VERSION ""

NS_ :

BS_:

BU_:

BO_ 2163223550 CN: 8 Vector__XXX
 SG_ CrashChecksum : 60|4@1+ (1,0) [0|15] "count" Vector__XXX
 SG_ CrashCounter : 56|4@1+ (1,0) [0|15] "count" Vector__XXX
 SG_ CrashType : 0|5@1+ (5,0) [0|0] "bit-mapped" Vector__XXX

BO_ 2230333950 WAND: 8 Vector__XXX
 SG_ WandAngle : 0|16@1+ (0.002,-64) [-64|64.51] "deg" Vector__XXX
 SG_ WandSensorFigureofMerit : 16|2@1+ (1,0) [0|3] "" Vector__XXX

BO_ 2230334206 LDISP: 8 Vector__XXX
 SG_ LnrDsplmntSnsrSnsrFgrfMrt : 16|2@1+ (1,0) [0|3] "" Vector__XXX
 SG_ MeasuredLinearDisplacement : 0|16@1+ (0.1,0) [0|6425.5] "mm" Vector__XXX

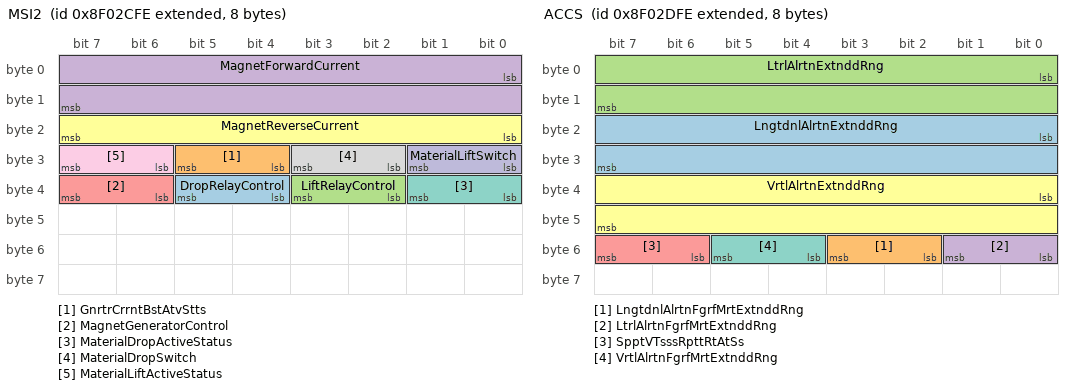
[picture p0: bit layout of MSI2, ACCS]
BO_ 2297441534 MSI2: 8 Vector__XXX
 SG_ DropRelayControl : 36|2@1+ (1,0) [0|3] "" Vector__XXX
 SG_ GnrtrCrrntBstAtvStts : 28|2@1+ (1,0) [0|3] "" Vector__XXX
 SG_ LiftRelayControl : 34|2@1+ (1,0) [0|3] "" Vector__XXX
 SG_ MagnetForwardCurrent : 0|16@1+ (1,0) [0|64255] "A" Vector__XXX
 SG_ MagnetGeneratorControl : 38|2@1+ (1,0) [0|3] "" Vector__XXX
 SG_ MagnetReverseCurrent : 16|8@1+ (1,0) [0|250] "A" Vector__XXX
 SG_ MaterialDropActiveStatus : 32|2@1+ (1,0) [0|3] "" Vector__XXX
 SG_ MaterialDropSwitch : 26|2@1+ (1,0) [0|3] "" Vector__XXX
 SG_ MaterialLiftActiveStatus : 30|2@1+ (1,0) [0|3] "" Vector__XXX
 SG_ MaterialLiftSwitch : 24|2@1+ (1,0) [0|3] "" Vector__XXX

BO_ 2297441790 ACCS: 8 Vector__XXX
 SG_ LngtdnlAlrtnExtnddRng : 16|16@1+ (0.01,-320) [-320|322.55] "m/(s*s)" Vector__XXX
 SG_ LngtdnlAlrtnFgrfMrtExtnddRng : 50|2@1+ (1,0) [0|3] "" Vector__XXX
 SG_ LtrlAlrtnExtnddRng : 0|16@1+ (0.01,-320) [-320|322.55] "m/(s*s)" Vector__XXX
 SG_ LtrlAlrtnFgrfMrtExtnddRng : 48|2@1+ (1,0) [0|3] "" Vector__XXX
 SG_ SpptVTsssRpttRtAtSs : 54|2@1+ (1,0) [0|3] "" Vector__XXX
 SG_ VrtlAlrtnExtnddRng : 32|16@1+ (0.01,-320) [-320|322.55] "m/(s*s)" Vector__XXX
 SG_ VrtlAlrtnFgrfMrtExtnddRng : 52|2@1+ (1,0) [0|3] "" Vector__XXX

BO_ 2297455358 ETC12: 8 Vector__XXX
 SG_ TrnsmssnDrtnlOtptShftSpd : 32|16@1+ (1,-32127) [-32127|32128] "rpm" Vector__XXX
 SG_ TrnsmssnHdrsttLp1Prssr : 0|16@1+ (1,0) [0|64255] "kPa" Vector__XXX
 SG_ TrnsmssnHdrsttLp2Prssr : 16|16@1+ (1,0) [0|64255] "kPa" Vector__XXX
 SG_ TrnsmssnIntrmdtShftSpd : 48|16@1+ (0.125,0) [0|8031.875] "rpm" Vector__XXX

BO_ 2297499902 B2: 8 Vector__XXX
 SG_ BrakePedalSwitch2 : 16|2@1+ (1,0) [0|3] "" Vector__XXX
 SG_ DmnddBrkAppltnPrssr : 0|16@1+ (0.1,0) [0|6425.5] "kPa" Vector__XXX

BO_ 2298375934 HRW: 8 Vector__XXX
 SG_ FrontAxleLeftWheelSpeed : 0|16@1+ (0.00390625,0) [0|250.996] "km/h" Vector__XXX
 SG_ Frontaxlerightwheelspeed : 16|16@1+ (0.00390625,0) [0|250.996] "km/h" Vector__XXX
 SG_ Rearaxleleftwheelspeed : 32|16@1+ (0.00390625,0) [0|250.996] "km/h" Vector__XXX
 SG_ Rearaxlerightwheelspeed : 48|16@1+ (0.00390625,0) [0|250.996] "km/h" Vector__XXX

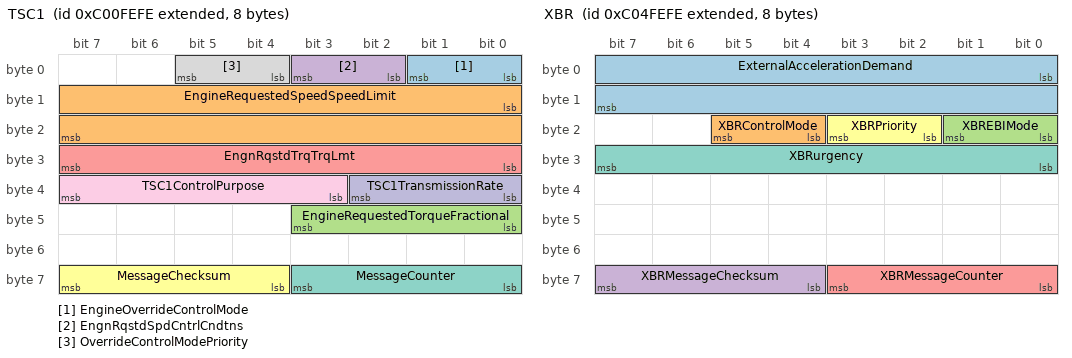
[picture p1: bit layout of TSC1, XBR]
BO_ 2348875518 TSC1: 8 Vector__XXX
 SG_ EngineOverrideControlMode : 0|2@1+ (1,0) [0|3] "" Vector__XXX
 SG_ EngineRequestedSpeedSpeedLimit : 8|16@1+ (0.125,0) [0|8031.875] "rpm" Vector__XXX
 SG_ EngineRequestedTorqueFractional : 40|4@1+ (0.125,0) [0|0.875] "%" Vector__XXX
 SG_ EngnRqstdSpdCntrlCndtns : 2|2@1+ (1,0) [0|3] "" Vector__XXX
 SG_ EngnRqstdTrqTrqLmt : 24|8@1+ (1,-125) [-125|125] "%" Vector__XXX
 SG_ MessageChecksum : 60|4@1+ (1,0) [0|15] "count" Vector__XXX
 SG_ MessageCounter : 56|4@1+ (1,0) [0|15] "count" Vector__XXX
 SG_ OverrideControlModePriority : 4|2@1+ (1,0) [0|3] "" Vector__XXX
 SG_ TSC1ControlPurpose : 35|5@1+ (1,0) [0|31] "" Vector__XXX
 SG_ TSC1TransmissionRate : 32|3@1+ (1,0) [0|7] "" Vector__XXX

BO_ 2348941054 TC1: 8 Vector__XXX
 SG_ DisengageDrivelineRequest : 4|2@1+ (1,0) [0|3] "" Vector__XXX
 SG_ DsnggDffrntlLkRqstCntrl : 32|2@1+ (1,0) [0|3] "" Vector__XXX
 SG_ DsnggDffrntlLkRqstCntrlFrnt : 34|2@1+ (1,0) [0|3] "" Vector__XXX
 SG_ DsnggDffrntlLkRqstCntrlRr : 36|2@1+ (1,0) [0|3] "" Vector__XXX
 SG_ DsnggDffrntlLkRqstFrntAxl1 : 24|2@1+ (1,0) [0|3] "" Vector__XXX
 SG_ DsnggDffrntlLkRqstFrntAxl2 : 26|2@1+ (1,0) [0|3] "" Vector__XXX
 SG_ DsnggDffrntlLkRqstRrAxl1 : 28|2@1+ (1,0) [0|3] "" Vector__XXX
 SG_ DsnggDffrntlLkRqstRrAxl2 : 30|2@1+ (1,0) [0|3] "" Vector__XXX
 SG_ RequestedPercentClutchSlip : 8|8@1+ (0.4,0) [0|100] "%" Vector__XXX
 SG_ TransmissionMode1 : 40|2@1+ (1,0) [0|3] "" Vector__XXX
 SG_ TransmissionMode2 : 42|2@1+ (1,0) [0|3] "" Vector__XXX
 SG_ TransmissionMode3 : 44|2@1+ (1,0) [0|3] "" Vector__XXX
 SG_ TransmissionMode4 : 46|2@1+ (1,0) [0|3] "" Vector__XXX
 SG_ TransmissionMode5 : 56|2@1+ (1,0) [0|3] "" Vector__XXX
 SG_ TransmissionMode6 : 58|2@1+ (1,0) [0|3] "" Vector__XXX
 SG_ TransmissionMode7 : 60|2@1+ (1,0) [0|3] "" Vector__XXX
 SG_ TransmissionMode8 : 62|2@1+ (1,0) [0|3] "" Vector__XXX
 SG_ TransmissionRequestedGear : 16|8@1+ (1,-125) [-125|125] "gear value" Vector__XXX
 SG_ TransmissionRequestedLaunchGear : 50|4@1+ (1,0) [0|15] "" Vector__XXX
 SG_ TrnsmssnAtNtrlMnlRtrnRqst : 48|2@1+ (1,0) [0|3] "" Vector__XXX
 SG_ TrnsmssnGrShftInhtRqst : 0|2@1+ (1,0) [0|3] "" Vector__XXX
 SG_ TrnsmssnLdRdtnInhtRqst : 38|2@1+ (1,0) [0|3] "" Vector__XXX
 SG_ TrnsmssnRvrsGrShftInhtRqst : 6|2@1+ (1,0) [0|3] "" Vector__XXX
 SG_ TrnsmssnShftSltrDsplMdSwth : 54|2@1+ (1,0) [0|3] "" Vector__XXX
 SG_ TrnsmssnTrqCnvrtrLkpRqst : 2|2@1+ (1,0) [0|3] "" Vector__XXX

BO_ 2349137662 XBR: 8 Vector__XXX
 SG_ ExternalAccelerationDemand : 0|16@1+ (0.00048828125,-15.687) [-15.687|15.687] "m/(s*s)" Vector__XXX
 SG_ XBRControlMode : 20|2@1+ (1,0) [0|3] "" Vector__XXX
 SG_ XBREBIMode : 16|2@1+ (1,0) [0|3] "" Vector__XXX
 SG_ XBRMessageChecksum : 60|4@1+ (1,0) [0|15] "count" Vector__XXX
 SG_ XBRMessageCounter : 56|4@1+ (1,0) [0|15] "count" Vector__XXX
 SG_ XBRPriority : 18|2@1+ (1,0) [0|3] "" Vector__XXX
 SG_ XBRurgency : 24|8@1+ (0.4,0) [0|100] "%" Vector__XXX

BO_ 2349399806 AUXIO5: 8 Vector__XXX
 SG_ AuxiliaryIOChannel3 : 48|16@1+ (1,0) [0|64255] "count" Vector__XXX
 SG_ AuxiliaryIOChannel4 : 32|16@1+ (1,0) [0|64255] "count" Vector__XXX
 SG_ AuxiliaryIOChannel5 : 16|16@1+ (1,0) [0|64255] "count" Vector__XXX
 SG_ AuxiliaryIOChannel6 : 0|16@1+ (1,0) [0|64255] "count" Vector__XXX

BO_ 2349465342 SRASI: 8 Vector__XXX
 SG_ StaticRollAngle : 0|8@1+ (1,-125) [-125|125] "deg" Vector__XXX
 SG_ StaticRollAngleStatus : 8|3@1+ (1,0) [0|7] "" Vector__XXX

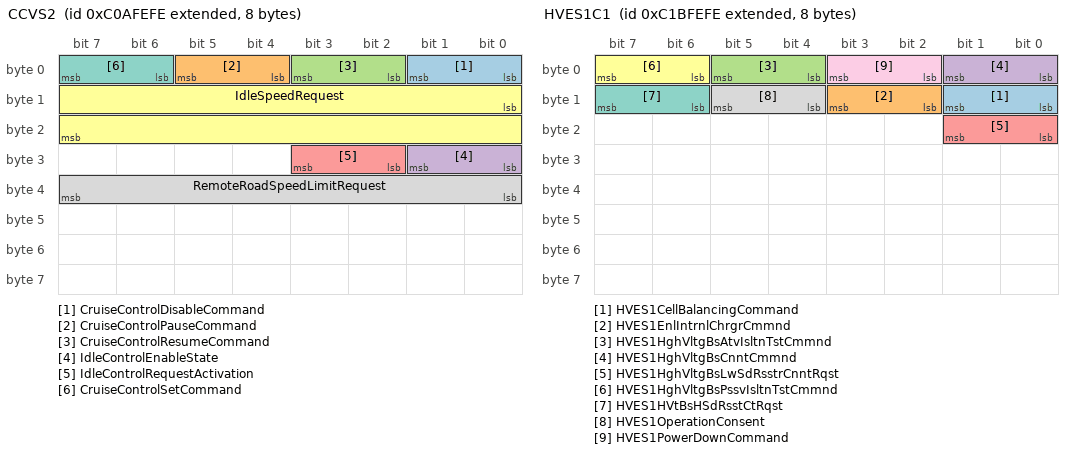
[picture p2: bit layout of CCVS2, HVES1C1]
BO_ 2349530878 CCVS2: 8 Vector__XXX
 SG_ CruiseControlDisableCommand : 0|2@1+ (1,0) [0|3] "" Vector__XXX
 SG_ CruiseControlPauseCommand : 4|2@1+ (1,0) [0|3] "" Vector__XXX
 SG_ CruiseControlResumeCommand : 2|2@1+ (1,0) [0|3] "" Vector__XXX
 SG_ IdleControlEnableState : 24|2@1+ (1,0) [0|3] "" Vector__XXX
 SG_ IdleControlRequestActivation : 26|2@1+ (1,0) [0|3] "" Vector__XXX
 SG_ IdleSpeedRequest : 8|16@1+ (0.125,0) [0|8031.875] "rpm" Vector__XXX
 SG_ CruiseControlSetCommand : 6|2@1+ (1,0) [0|3] "" Vector__XXX
 SG_ RemoteRoadSpeedLimitRequest : 32|8@1+ (1,0) [0|250] "km/h" Vector__XXX

BO_ 2349596414 AEBS2: 8 Vector__XXX
 SG_ AEBS2messagechecksum : 60|4@1+ (1,0) [0|15] "count" Vector__XXX
 SG_ AEBS2messageCounter : 56|4@1+ (1,0) [0|15] "count" Vector__XXX
 SG_ DvtvtddAdvdEBSst : 0|2@1+ (1,0) [0|3] "" Vector__XXX

BO_ 2349727486 TC2: 8 Vector__XXX
 SG_ TransmissionMode10 : 2|2@1+ (1,0) [0|3] "" Vector__XXX
 SG_ TransmissionMode9 : 0|2@1+ (1,0) [0|3] "" Vector__XXX

BO_ 2350644990 HVES1C1: 8 Vector__XXX
 SG_ HVES1CellBalancingCommand : 8|2@1+ (1,0) [0|3] "" Vector__XXX
 SG_ HVES1EnlIntrnlChrgrCmmnd : 10|2@1+ (1,0) [0|3] "" Vector__XXX
 SG_ HVES1HghVltgBsAtvIsltnTstCmmnd : 4|2@1+ (1,0) [0|3] "" Vector__XXX
 SG_ HVES1HghVltgBsCnntCmmnd : 0|2@1+ (1,0) [0|3] "" Vector__XXX
 SG_ HVES1HghVltgBsLwSdRsstrCnntRqst : 16|2@1+ (1,0) [0|3] "" Vector__XXX
 SG_ HVES1HghVltgBsPssvIsltnTstCmmnd : 6|2@1+ (1,0) [0|3] "" Vector__XXX
 SG_ HVES1HVtBsHSdRsstCtRqst : 14|2@1+ (1,0) [0|3] "" Vector__XXX
 SG_ HVES1OperationConsent : 12|2@1+ (1,0) [0|3] "" Vector__XXX
 SG_ HVES1PowerDownCommand : 2|2@1+ (1,0) [0|3] "" Vector__XXX

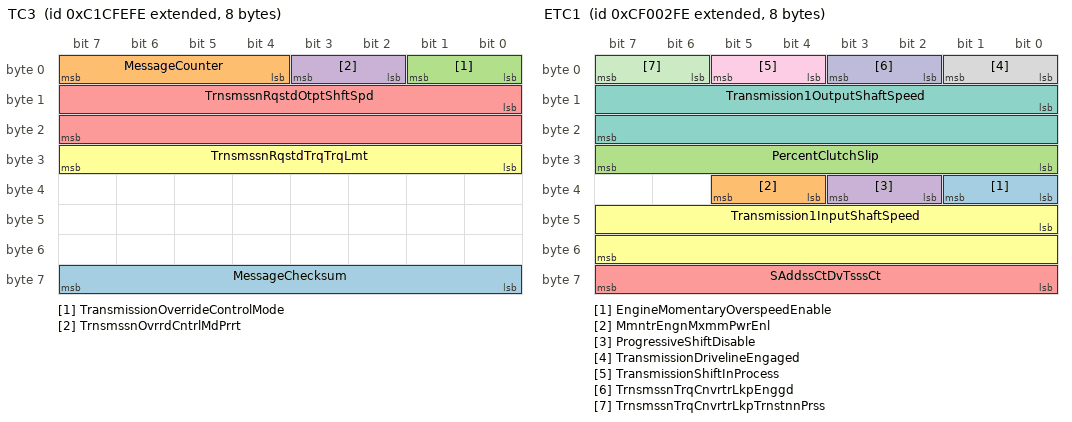
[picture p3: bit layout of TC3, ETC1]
BO_ 2350710526 TC3: 8 Vector__XXX
 SG_ MessageChecksum : 56|8@1+ (1,0) [0|255] "count" Vector__XXX
 SG_ MessageCounter : 4|4@1+ (1,0) [0|15] "count" Vector__XXX
 SG_ TransmissionOverrideControlMode : 0|2@1+ (1,0) [0|3] "" Vector__XXX
 SG_ TrnsmssnOvrrdCntrlMdPrrt : 2|2@1+ (1,0) [0|3] "" Vector__XXX
 SG_ TrnsmssnRqstdOtptShftSpd : 8|16@1+ (0.25,-8031.75) [-8031.75|8032] "rpm" Vector__XXX
 SG_ TrnsmssnRqstdTrqTrqLmt : 24|8@1+ (1,-125) [-125|125] "%" Vector__XXX

BO_ 2350776062 EIC: 8 Vector__XXX
 SG_ EngineTimingAdvance : 0|16@1+ (0.0078125,-200) [-200|301.99] "deg" Vector__XXX

BO_ 2350841598 ALTC: 8 Vector__XXX
 SG_ AlternatorTorqueRampTimeCommand : 24|8@1+ (0.1,0) [0|25] "s" Vector__XXX
 SG_ AltrntrExttnMxmmCrrntLmt : 16|8@1+ (0.25,0) [0|62.5] "A" Vector__XXX
 SG_ AltrntrStpntVltgCmmnd : 0|16@1+ (0.001,0) [0|64.255] "V" Vector__XXX
 SG_ AltrntrTrqRmpMxmmSpdCmmnd : 32|8@1+ (32,0) [0|8000] "rpm" Vector__XXX

BO_ 2358902526 JLCM: 8 Vector__XXX
 SG_ Joystick1Lamp10Command : 18|2@1+ (1,0) [0|3] "" Vector__XXX
 SG_ Joystick1Lamp1Command : 0|2@1+ (1,0) [0|3] "" Vector__XXX
 SG_ Joystick1Lamp2Command : 2|2@1+ (1,0) [0|3] "" Vector__XXX
 SG_ Joystick1Lamp3Command : 4|2@1+ (1,0) [0|3] "" Vector__XXX
 SG_ Joystick1Lamp4Command : 6|2@1+ (1,0) [0|3] "" Vector__XXX
 SG_ Joystick1Lamp5Command : 8|2@1+ (1,0) [0|3] "" Vector__XXX
 SG_ Joystick1Lamp6Command : 10|2@1+ (1,0) [0|3] "" Vector__XXX
 SG_ Joystick1Lamp7Command : 12|2@1+ (1,0) [0|3] "" Vector__XXX
 SG_ Joystick1Lamp8Command : 14|2@1+ (1,0) [0|3] "" Vector__XXX
 SG_ Joystick1Lamp9Command : 16|2@1+ (1,0) [0|3] "" Vector__XXX
 SG_ Joystick2Lamp10Command : 38|2@1+ (1,0) [0|3] "" Vector__XXX
 SG_ Joystick2Lamp1Command : 20|2@1+ (1,0) [0|3] "" Vector__XXX
 SG_ Joystick2Lamp2Command : 22|2@1+ (1,0) [0|3] "" Vector__XXX
 SG_ Joystick2Lamp3Command : 24|2@1+ (1,0) [0|3] "" Vector__XXX
 SG_ Joystick2Lamp4Command : 26|2@1+ (1,0) [0|3] "" Vector__XXX
 SG_ Joystick2Lamp5Command : 28|2@1+ (1,0) [0|3] "" Vector__XXX
 SG_ Joystick2Lamp6Command : 30|2@1+ (1,0) [0|3] "" Vector__XXX
 SG_ Joystick2Lamp7Command : 32|2@1+ (1,0) [0|3] "" Vector__XXX
 SG_ Joystick2Lamp8Command : 34|2@1+ (1,0) [0|3] "" Vector__XXX
 SG_ Joystick2Lamp9Command : 36|2@1+ (1,0) [0|3] "" Vector__XXX
 SG_ Joystick3Lamp10Command : 58|2@1+ (1,0) [0|3] "" Vector__XXX
 SG_ Joystick3Lamp1Command : 40|2@1+ (1,0) [0|3] "" Vector__XXX
 SG_ Joystick3Lamp2Command : 42|2@1+ (1,0) [0|3] "" Vector__XXX
 SG_ Joystick3Lamp3Command : 44|2@1+ (1,0) [0|3] "" Vector__XXX
 SG_ Joystick3Lamp4Command : 46|2@1+ (1,0) [0|3] "" Vector__XXX
 SG_ Joystick3Lamp5Command : 48|2@1+ (1,0) [0|3] "" Vector__XXX
 SG_ Joystick3Lamp6Command : 50|2@1+ (1,0) [0|3] "" Vector__XXX
 SG_ Joystick3Lamp7Command : 52|2@1+ (1,0) [0|3] "" Vector__XXX
 SG_ Joystick3Lamp8Command : 54|2@1+ (1,0) [0|3] "" Vector__XXX
 SG_ Joystick3Lamp9Command : 56|2@1+ (1,0) [0|3] "" Vector__XXX

BO_ 2362572542 ASC6: 8 Vector__XXX
 SG_ LevelPresetFrontAxleLeft : 0|16@1+ (0.1,-3200) [-3200|3225.5] "mm" Vector__XXX
 SG_ LevelPresetFrontAxleRight : 16|16@1+ (0.1,-3200) [-3200|3225.5] "mm" Vector__XXX
 SG_ LevelPresetRearAxleLeft : 32|16@1+ (0.1,-3200) [-3200|3225.5] "mm" Vector__XXX
 SG_ LevelPresetRearAxleRight : 48|16@1+ (0.1,-3200) [-3200|3225.5] "mm" Vector__XXX

BO_ 2362638078 ASC2: 8 Vector__XXX
 SG_ AllwLvlCntrlDrngBrkngCmmnd : 54|2@1+ (1,0) [0|3] "" Vector__XXX
 SG_ Atmttrtnhlpldtrnsfr : 0|2@1+ (1,0) [0|3] "" Vector__XXX
 SG_ DamperStiffnessRequestFrontAxle : 24|8@1+ (0.4,0) [0|100] "%" Vector__XXX
 SG_ DamperStiffnessRequestRearAxle : 32|8@1+ (0.4,0) [0|100] "%" Vector__XXX
 SG_ DmprStffnssRqstLftTgAxl : 40|8@1+ (0.4,0) [0|100] "%" Vector__XXX
 SG_ KneelingCommandFrontAxle : 48|2@1+ (1,0) [0|3] "" Vector__XXX
 SG_ KneelingCommandRearAxle : 50|2@1+ (1,0) [0|3] "" Vector__XXX
 SG_ KneelingControlModeRequest : 6|2@1+ (1,0) [0|3] "" Vector__XXX
 SG_ KneelingRequestLeftSide : 2|2@1+ (1,0) [0|3] "" Vector__XXX
 SG_ KneelingRequestRightSide : 4|2@1+ (1,0) [0|3] "" Vector__XXX
 SG_ LevelControlModeRequest : 16|4@1+ (1,0) [0|15] "" Vector__XXX
 SG_ LiftAxle1PositionCommand : 20|2@1+ (1,0) [0|3] "" Vector__XXX
 SG_ LiftAxle2PositionCommand : 22|2@1+ (1,0) [0|3] "" Vector__XXX
 SG_ Memorylevelrequest : 60|4@1+ (1,0) [0|15] "" Vector__XXX
 SG_ NominalLevelRequestFrontAxle : 8|4@1+ (1,0) [0|15] "" Vector__XXX
 SG_ NominalLevelRequestRearAxle : 12|4@1+ (1,0) [0|15] "" Vector__XXX
 SG_ PrhtAtmtArSspnsnCntrl : 58|2@1+ (1,0) [0|3] "" Vector__XXX
 SG_ Prohibitairsuspensioncontrol : 52|2@1+ (1,0) [0|3] "" Vector__XXX
 SG_ SpdDpndntLvlCntrlRqst : 56|2@1+ (1,0) [0|3] "" Vector__XXX

BO_ 2364539646 ETC1: 8 Vector__XXX
 SG_ EngineMomentaryOverspeedEnable : 32|2@1+ (1,0) [0|3] "" Vector__XXX
 SG_ MmntrEngnMxmmPwrEnl : 36|2@1+ (1,0) [0|3] "" Vector__XXX
 SG_ PercentClutchSlip : 24|8@1+ (0.4,0) [0|100] "%" Vector__XXX
 SG_ ProgressiveShiftDisable : 34|2@1+ (1,0) [0|3] "" Vector__XXX
 SG_ SAddssCtDvTsssCt : 56|8@1+ (1,0) [0|255] "SA" Vector__XXX
 SG_ Transmission1InputShaftSpeed : 40|16@1+ (0.125,0) [0|8031.875] "rpm" Vector__XXX
 SG_ Transmission1OutputShaftSpeed : 8|16@1+ (0.125,0) [0|8031.875] "rpm" Vector__XXX
 SG_ TransmissionDrivelineEngaged : 0|2@1+ (1,0) [0|3] "" Vector__XXX
 SG_ TransmissionShiftInProcess : 4|2@1+ (1,0) [0|3] "" Vector__XXX
 SG_ TrnsmssnTrqCnvrtrLkpEnggd : 2|2@1+ (1,0) [0|3] "" Vector__XXX
 SG_ TrnsmssnTrqCnvrtrLkpTrnstnnPrss : 6|2@1+ (1,0) [0|3] "" Vector__XXX

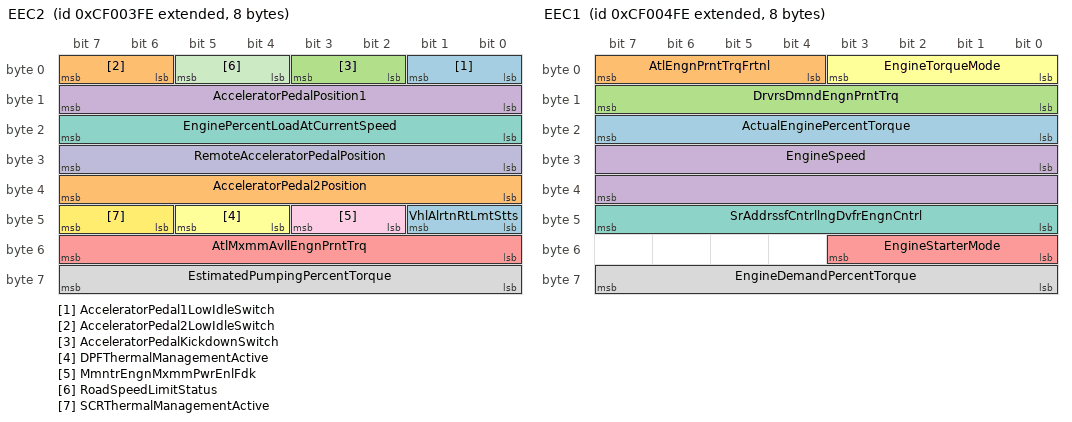
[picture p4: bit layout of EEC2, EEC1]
BO_ 2364539902 EEC2: 8 Vector__XXX
 SG_ AcceleratorPedal1LowIdleSwitch : 0|2@1+ (1,0) [0|3] "" Vector__XXX
 SG_ AcceleratorPedal2LowIdleSwitch : 6|2@1+ (1,0) [0|3] "" Vector__XXX
 SG_ AcceleratorPedalKickdownSwitch : 2|2@1+ (1,0) [0|3] "" Vector__XXX
 SG_ AcceleratorPedalPosition1 : 8|8@1+ (0.4,0) [0|100] "%" Vector__XXX
 SG_ AtlMxmmAvllEngnPrntTrq : 48|8@1+ (0.4,0) [0|100] "%" Vector__XXX
 SG_ DPFThermalManagementActive : 44|2@1+ (1,0) [0|3] "" Vector__XXX
 SG_ EnginePercentLoadAtCurrentSpeed : 16|8@1+ (1,0) [0|250] "%" Vector__XXX
 SG_ EstimatedPumpingPercentTorque : 56|8@1+ (1,-125) [-125|125] "%" Vector__XXX
 SG_ MmntrEngnMxmmPwrEnlFdk : 42|2@1+ (1,0) [0|3] "" Vector__XXX
 SG_ RemoteAcceleratorPedalPosition : 24|8@1+ (0.4,0) [0|100] "%" Vector__XXX
 SG_ RoadSpeedLimitStatus : 4|2@1+ (1,0) [0|3] "" Vector__XXX
 SG_ SCRThermalManagementActive : 46|2@1+ (1,0) [0|3] "" Vector__XXX
 SG_ VhlAlrtnRtLmtStts : 40|2@1+ (1,0) [0|3] "" Vector__XXX
 SG_ AcceleratorPedal2Position : 32|8@1+ (0.4,0) [0|100] "%" Vector__XXX

BO_ 2364540158 EEC1: 8 Vector__XXX
 SG_ ActualEnginePercentTorque : 16|8@1+ (1,-125) [-125|125] "%" Vector__XXX
 SG_ AtlEngnPrntTrqFrtnl : 4|4@1+ (0.125,0) [0|0.875] "%" Vector__XXX
 SG_ DrvrsDmndEngnPrntTrq : 8|8@1+ (1,-125) [-125|125] "%" Vector__XXX
 SG_ EngineSpeed : 24|16@1+ (0.125,0) [0|8031.875] "rpm" Vector__XXX
 SG_ EngineStarterMode : 48|4@1+ (1,0) [0|15] "" Vector__XXX
 SG_ EngineTorqueMode : 0|4@1+ (1,0) [0|15] "" Vector__XXX
 SG_ SrAddrssfCntrllngDvfrEngnCntrl : 40|8@1+ (1,0) [0|255] "SA" Vector__XXX
 SG_ EngineDemandPercentTorque : 56|8@1+ (1,-125) [-125|125] "%" Vector__XXX

BO_ 2364541694 EGF1: 8 Vector__XXX
 SG_ EngineIntakeAirMassFlowRate : 16|16@1+ (0.05,0) [0|3212.75] "kg/h" Vector__XXX
 SG_ EngnExhstGsRrltn1MssFlwRt : 0|16@1+ (0.05,0) [0|3212.75] "kg/h" Vector__XXX
 SG_ EngnExhstGsRrltn2MssFlwRt : 32|16@1+ (0.05,0) [0|3212.75] "kg/h" Vector__XXX

BO_ 2364542206 ETC8: 8 Vector__XXX
 SG_ TrnsmssnClthCnvrtrInptSpd : 16|16@1+ (0.125,0) [0|8031.875] "rpm" Vector__XXX
 SG_ TrnsmssnTrqCnvrtrRt : 0|16@1+ (0.001,0) [0|64.255] "Ratio" Vector__XXX
 SG_ TransmissionShiftInhibitReason : 32|8@1+ (1,0) [0|255] "" Vector__XXX
 SG_ TrnsmssnTrqCnvrtrLkpInhtRsn : 40|8@1+ (1,0) [0|255] "" Vector__XXX
 SG_ TrnsmssnTrqCnvrtrLkpInhtIndtr : 48|2@1+ (1,0) [0|3] "" Vector__XXX

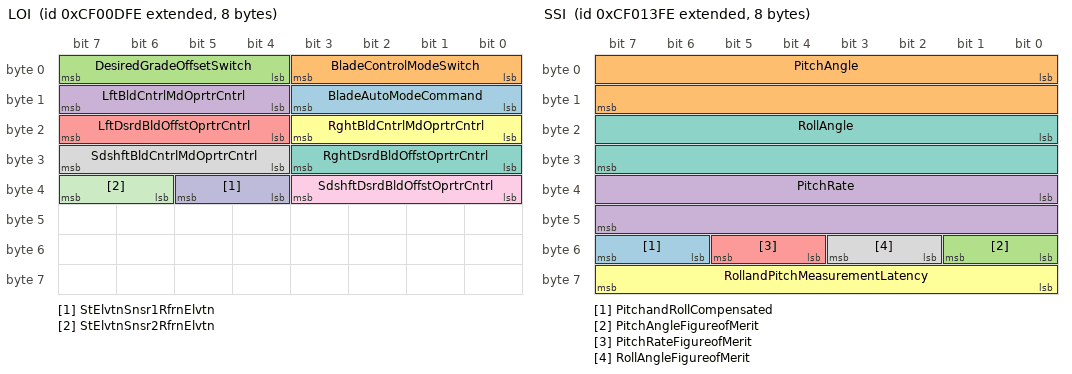
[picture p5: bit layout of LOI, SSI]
BO_ 2364542462 LOI: 8 Vector__XXX
 SG_ BladeAutoModeCommand : 8|4@1+ (1,0) [0|15] "" Vector__XXX
 SG_ BladeControlModeSwitch : 0|4@1+ (1,0) [0|15] "" Vector__XXX
 SG_ DesiredGradeOffsetSwitch : 4|4@1+ (1,0) [0|15] "" Vector__XXX
 SG_ LftBldCntrlMdOprtrCntrl : 12|4@1+ (1,0) [0|15] "" Vector__XXX
 SG_ LftDsrdBldOffstOprtrCntrl : 20|4@1+ (1,0) [0|15] "" Vector__XXX
 SG_ RghtBldCntrlMdOprtrCntrl : 16|4@1+ (1,0) [0|15] "" Vector__XXX
 SG_ RghtDsrdBldOffstOprtrCntrl : 24|4@1+ (1,0) [0|15] "" Vector__XXX
 SG_ SdshftBldCntrlMdOprtrCntrl : 28|4@1+ (1,0) [0|15] "" Vector__XXX
 SG_ SdshftDsrdBldOffstOprtrCntrl : 32|4@1+ (1,0) [0|15] "" Vector__XXX
 SG_ StElvtnSnsr1RfrnElvtn : 36|2@1+ (1,0) [0|3] "" Vector__XXX
 SG_ StElvtnSnsr2RfrnElvtn : 38|2@1+ (1,0) [0|3] "" Vector__XXX

BO_ 2364543998 SSI: 8 Vector__XXX
 SG_ PitchandRollCompensated : 54|2@1+ (1,0) [0|3] "" Vector__XXX
 SG_ PitchAngle : 0|16@1+ (0.002,-64) [-64|64.51] "deg" Vector__XXX
 SG_ PitchAngleFigureofMerit : 48|2@1+ (1,0) [0|3] "" Vector__XXX
 SG_ PitchRate : 32|16@1+ (0.002,-64) [-64|64.51] "deg/s" Vector__XXX
 SG_ PitchRateFigureofMerit : 52|2@1+ (1,0) [0|3] "" Vector__XXX
 SG_ RollandPitchMeasurementLatency : 56|8@1+ (0.5,0) [0|125] "ms" Vector__XXX
 SG_ RollAngle : 16|16@1+ (0.002,-64) [-64|64.51] "deg" Vector__XXX
 SG_ RollAngleFigureofMerit : 50|2@1+ (1,0) [0|3] "" Vector__XXX

BO_ 2364544254 BI: 8 Vector__XXX
 SG_ BladeRotationAngle : 16|16@1+ (0.0078125,-200) [-200|301.99] "deg" Vector__XXX
 SG_ BladeRotationAngleFigureofMerit : 42|2@1+ (1,0) [0|3] "" Vector__XXX
 SG_ RelativeBladeHeight : 0|16@1+ (0.1,-3200) [-3200|3225.5] "mm" Vector__XXX
 SG_ RltvBldHghtFgrfMrt : 40|2@1+ (1,0) [0|3] "" Vector__XXX
 SG_ RtvBdHtdBdRttAMstLt : 32|8@1+ (0.5,0) [0|125] "ms" Vector__XXX

BO_ 2364544510 RGTACRP: 8 Vector__XXX
 SG_ RqstdGnrtrOvrllPwrFtr : 32|16@1+ (0.00006103515625,-1) [-1|2.921814] "" Vector__XXX
 SG_ RqstdGnrtrOvrllPwrFtrLggng : 48|2@1+ (1,0) [0|3] "" Vector__XXX
 SG_ RqstdGnrtrTtlACRtvPwr : 0|32@1+ (1,-2000000000) [-2000000000|2.21108E+09] "VA" Vector__XXX

BO_ 2364544766 CCS: 8 Vector__XXX
 SG_ EngineCylinder1CombustionStatus : 0|2@1+ (1,0) [0|3] "" Vector__XXX
 SG_ EngineCylinder2CombustionStatus : 2|2@1+ (1,0) [0|3] "" Vector__XXX
 SG_ EngineCylinder3CombustionStatus : 4|2@1+ (1,0) [0|3] "" Vector__XXX
 SG_ EngineCylinder4CombustionStatus : 6|2@1+ (1,0) [0|3] "" Vector__XXX
 SG_ EngineCylinder5CombustionStatus : 8|2@1+ (1,0) [0|3] "" Vector__XXX
 SG_ EngineCylinder6CombustionStatus : 10|2@1+ (1,0) [0|3] "" Vector__XXX
 SG_ EngineCylinder7CombustionStatus : 12|2@1+ (1,0) [0|3] "" Vector__XXX
 SG_ EngineCylinder8CombustionStatus : 14|2@1+ (1,0) [0|3] "" Vector__XXX
 SG_ EngineCylinder9CombustionStatus : 16|2@1+ (1,0) [0|3] "" Vector__XXX
 SG_ EngnClndr10CmstnStts : 18|2@1+ (1,0) [0|3] "" Vector__XXX
 SG_ EngnClndr11CmstnStts : 20|2@1+ (1,0) [0|3] "" Vector__XXX
 SG_ EngnClndr12CmstnStts : 22|2@1+ (1,0) [0|3] "" Vector__XXX
 SG_ EngnClndr13CmstnStts : 24|2@1+ (1,0) [0|3] "" Vector__XXX
 SG_ EngnClndr14CmstnStts : 26|2@1+ (1,0) [0|3] "" Vector__XXX
 SG_ EngnClndr15CmstnStts : 28|2@1+ (1,0) [0|3] "" Vector__XXX
 SG_ EngnClndr16CmstnStts : 30|2@1+ (1,0) [0|3] "" Vector__XXX
 SG_ EngnClndr17CmstnStts : 32|2@1+ (1,0) [0|3] "" Vector__XXX
 SG_ EngnClndr18CmstnStts : 34|2@1+ (1,0) [0|3] "" Vector__XXX
 SG_ EngnClndr19CmstnStts : 36|2@1+ (1,0) [0|3] "" Vector__XXX
 SG_ EngnClndr20CmstnStts : 38|2@1+ (1,0) [0|3] "" Vector__XXX
 SG_ EngnClndr21CmstnStts : 40|2@1+ (1,0) [0|3] "" Vector__XXX
 SG_ EngnClndr22CmstnStts : 42|2@1+ (1,0) [0|3] "" Vector__XXX
 SG_ EngnClndr23CmstnStts : 44|2@1+ (1,0) [0|3] "" Vector__XXX
 SG_ EngnClndr24CmstnStts : 46|2@1+ (1,0) [0|3] "" Vector__XXX

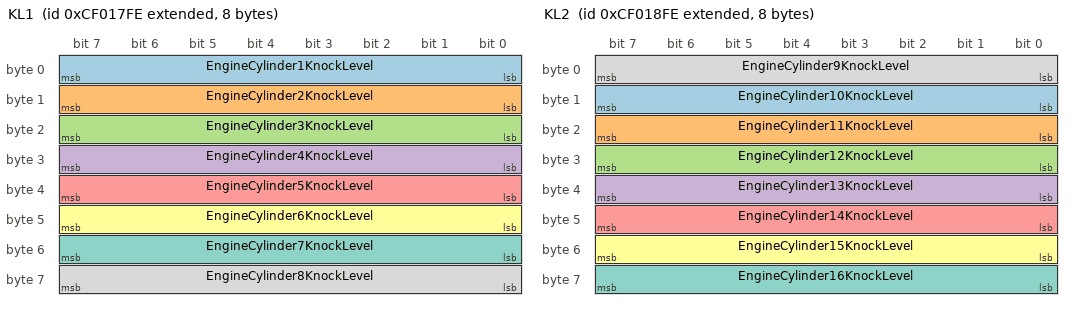
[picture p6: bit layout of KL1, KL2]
BO_ 2364545022 KL1: 8 Vector__XXX
 SG_ EngineCylinder1KnockLevel : 0|8@1+ (1,0) [0|250] "%" Vector__XXX
 SG_ EngineCylinder2KnockLevel : 8|8@1+ (1,0) [0|250] "%" Vector__XXX
 SG_ EngineCylinder3KnockLevel : 16|8@1+ (1,0) [0|250] "%" Vector__XXX
 SG_ EngineCylinder4KnockLevel : 24|8@1+ (1,0) [0|250] "%" Vector__XXX
 SG_ EngineCylinder5KnockLevel : 32|8@1+ (1,0) [0|250] "%" Vector__XXX
 SG_ EngineCylinder6KnockLevel : 40|8@1+ (1,0) [0|250] "%" Vector__XXX
 SG_ EngineCylinder7KnockLevel : 48|8@1+ (1,0) [0|250] "%" Vector__XXX
 SG_ EngineCylinder8KnockLevel : 56|8@1+ (1,0) [0|250] "%" Vector__XXX

BO_ 2364545278 KL2: 8 Vector__XXX
 SG_ EngineCylinder10KnockLevel : 8|8@1+ (1,0) [0|250] "%" Vector__XXX
 SG_ EngineCylinder11KnockLevel : 16|8@1+ (1,0) [0|250] "%" Vector__XXX
 SG_ EngineCylinder12KnockLevel : 24|8@1+ (1,0) [0|250] "%" Vector__XXX
 SG_ EngineCylinder13KnockLevel : 32|8@1+ (1,0) [0|250] "%" Vector__XXX
 SG_ EngineCylinder14KnockLevel : 40|8@1+ (1,0) [0|250] "%" Vector__XXX
 SG_ EngineCylinder15KnockLevel : 48|8@1+ (1,0) [0|250] "%" Vector__XXX
 SG_ EngineCylinder16KnockLevel : 56|8@1+ (1,0) [0|250] "%" Vector__XXX
 SG_ EngineCylinder9KnockLevel : 0|8@1+ (1,0) [0|250] "%" Vector__XXX

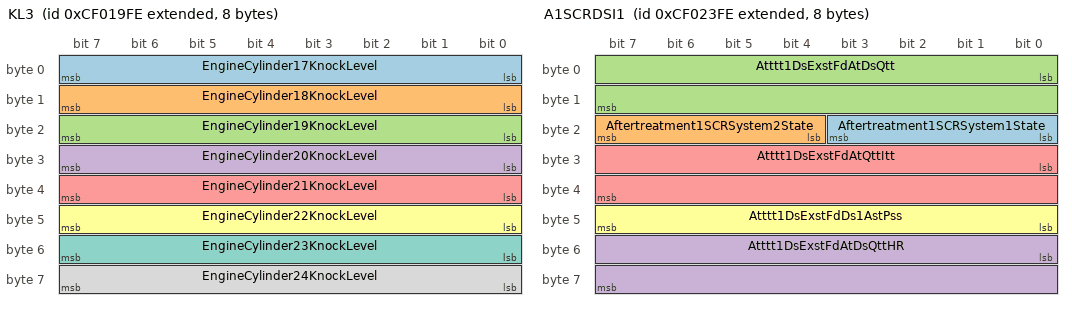
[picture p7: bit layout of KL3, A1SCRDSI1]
BO_ 2364545534 KL3: 8 Vector__XXX
 SG_ EngineCylinder17KnockLevel : 0|8@1+ (1,0) [0|250] "%" Vector__XXX
 SG_ EngineCylinder18KnockLevel : 8|8@1+ (1,0) [0|250] "%" Vector__XXX
 SG_ EngineCylinder19KnockLevel : 16|8@1+ (1,0) [0|250] "%" Vector__XXX
 SG_ EngineCylinder20KnockLevel : 24|8@1+ (1,0) [0|250] "%" Vector__XXX
 SG_ EngineCylinder21KnockLevel : 32|8@1+ (1,0) [0|250] "%" Vector__XXX
 SG_ EngineCylinder22KnockLevel : 40|8@1+ (1,0) [0|250] "%" Vector__XXX
 SG_ EngineCylinder23KnockLevel : 48|8@1+ (1,0) [0|250] "%" Vector__XXX
 SG_ EngineCylinder24KnockLevel : 56|8@1+ (1,0) [0|250] "%" Vector__XXX

BO_ 2364546302 RGAAC: 8 Vector__XXX
 SG_ RqstdGnrtrAvrgLnLnACRMSVltg : 0|32@1+ (0.0078125,0) [0|3.28990E+07] "V" Vector__XXX

BO_ 2364546814 GC2: 8 Vector__XXX
 SG_ EngineLoadSetpointRequest : 24|16@1+ (0.5,0) [0|32127.5] "kW" Vector__XXX
 SG_ EngineSelfInducedDerateInhibit : 16|2@1+ (1,0) [0|3] "" Vector__XXX
 SG_ GeneratorGoverningBias : 0|16@1+ (0.004,-125) [-125|132.02] "%" Vector__XXX

BO_ 2364548094 A1SCRDSI1: 8 Vector__XXX
 SG_ Aftertreatment1SCRSystem1State : 16|4@1+ (1,0) [0|15] "" Vector__XXX
 SG_ Aftertreatment1SCRSystem2State : 20|4@1+ (1,0) [0|15] "" Vector__XXX
 SG_ Atttt1DsExstFdAtDsQtt : 0|16@1+ (0.3,0) [0|19276.5] "g/h" Vector__XXX
 SG_ Atttt1DsExstFdAtDsQttHR : 48|16@1+ (0.05,0) [0|3212.75] "g/min" Vector__XXX
 SG_ Atttt1DsExstFdAtQttItt : 24|16@1+ (0.1,0) [0|6425.5] "g" Vector__XXX
 SG_ Atttt1DsExstFdDs1AstPss : 40|8@1+ (8,0) [0|2000] "kPa" Vector__XXX

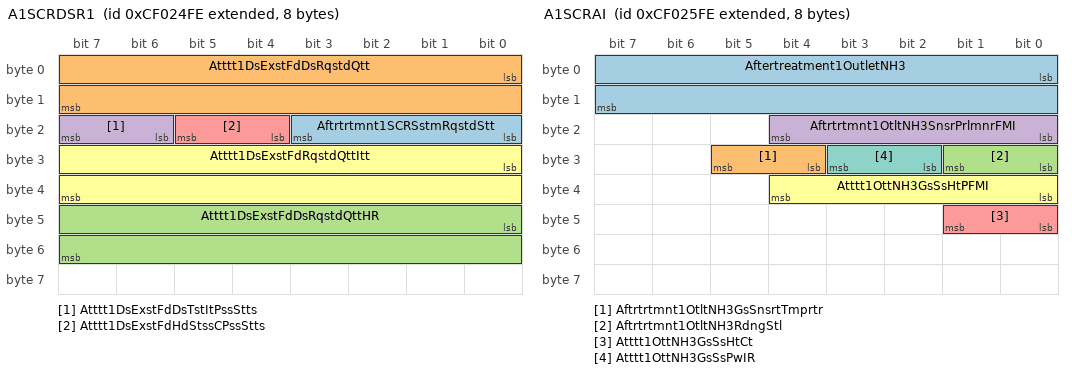
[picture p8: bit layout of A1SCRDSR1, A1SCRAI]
BO_ 2364548350 A1SCRDSR1: 8 Vector__XXX
 SG_ Aftrtrtmnt1SCRSstmRqstdStt : 16|4@1+ (1,0) [0|15] "" Vector__XXX
 SG_ Atttt1DsExstFdDsRqstdQtt : 0|16@1+ (0.3,0) [0|19276.5] "g/h" Vector__XXX
 SG_ Atttt1DsExstFdDsRqstdQttHR : 40|16@1+ (0.05,0) [0|3212.75] "g/min" Vector__XXX
 SG_ Atttt1DsExstFdDsTstItPssStts : 22|2@1+ (1,0) [0|3] "" Vector__XXX
 SG_ Atttt1DsExstFdHdStssCPssStts : 20|2@1+ (1,0) [0|3] "" Vector__XXX
 SG_ Atttt1DsExstFdRqstdQttItt : 24|16@1+ (0.1,0) [0|6425.5] "g" Vector__XXX

BO_ 2364548606 A1SCRAI: 8 Vector__XXX
 SG_ Aftertreatment1OutletNH3 : 0|16@1+ (0.05,-200) [-200|3012.75] "ppm" Vector__XXX
 SG_ Aftrtrtmnt1OtltNH3GsSnsrtTmprtr : 28|2@1+ (1,0) [0|3] "" Vector__XXX
 SG_ Aftrtrtmnt1OtltNH3RdngStl : 24|2@1+ (1,0) [0|3] "" Vector__XXX
 SG_ Aftrtrtmnt1OtltNH3SnsrPrlmnrFMI : 16|5@1+ (1,0) [0|31] "binary" Vector__XXX
 SG_ Atttt1OttNH3GsSsHtCt : 40|2@1+ (1,0) [0|3] "" Vector__XXX
 SG_ Atttt1OttNH3GsSsHtPFMI : 32|5@1+ (1,0) [0|31] "binary" Vector__XXX
 SG_ Atttt1OttNH3GsSsPwIR : 26|2@1+ (1,0) [0|3] "" Vector__XXX

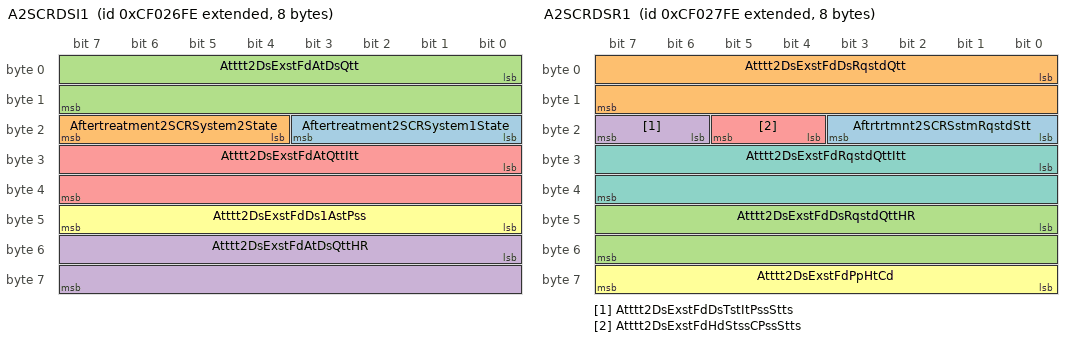
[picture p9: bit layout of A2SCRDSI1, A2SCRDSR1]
BO_ 2364548862 A2SCRDSI1: 8 Vector__XXX
 SG_ Aftertreatment2SCRSystem1State : 16|4@1+ (1,0) [0|15] "" Vector__XXX
 SG_ Aftertreatment2SCRSystem2State : 20|4@1+ (1,0) [0|15] "" Vector__XXX
 SG_ Atttt2DsExstFdAtDsQtt : 0|16@1+ (0.3,0) [0|19276.5] "g/h" Vector__XXX
 SG_ Atttt2DsExstFdAtDsQttHR : 48|16@1+ (0.05,0) [0|3212.75] "g/min" Vector__XXX
 SG_ Atttt2DsExstFdAtQttItt : 24|16@1+ (0.1,0) [0|6425.5] "g" Vector__XXX
 SG_ Atttt2DsExstFdDs1AstPss : 40|8@1+ (8,0) [0|2000] "kPa" Vector__XXX

BO_ 2364549118 A2SCRDSR1: 8 Vector__XXX
 SG_ Aftrtrtmnt2SCRSstmRqstdStt : 16|4@1+ (1,0) [0|15] "" Vector__XXX
 SG_ Atttt2DsExstFdDsRqstdQtt : 0|16@1+ (0.3,0) [0|19276.5] "g/h" Vector__XXX
 SG_ Atttt2DsExstFdDsRqstdQttHR : 40|16@1+ (0.05,0) [0|3212.75] "g/min" Vector__XXX
 SG_ Atttt2DsExstFdDsTstItPssStts : 22|2@1+ (1,0) [0|3] "" Vector__XXX
 SG_ Atttt2DsExstFdHdStssCPssStts : 20|2@1+ (1,0) [0|3] "" Vector__XXX
 SG_ Atttt2DsExstFdPpHtCd : 56|8@1+ (0.4,0) [0|100] "%" Vector__XXX
 SG_ Atttt2DsExstFdRqstdQttItt : 24|16@1+ (0.1,0) [0|6425.5] "g" Vector__XXX

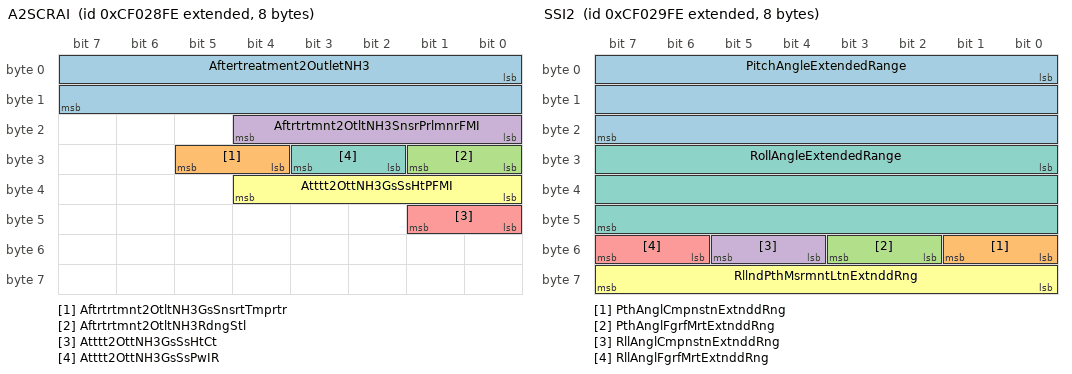
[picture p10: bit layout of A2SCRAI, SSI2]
BO_ 2364549374 A2SCRAI: 8 Vector__XXX
 SG_ Aftertreatment2OutletNH3 : 0|16@1+ (0.05,-200) [-200|3012.75] "ppm" Vector__XXX
 SG_ Aftrtrtmnt2OtltNH3GsSnsrtTmprtr : 28|2@1+ (1,0) [0|3] "" Vector__XXX
 SG_ Aftrtrtmnt2OtltNH3RdngStl : 24|2@1+ (1,0) [0|3] "" Vector__XXX
 SG_ Aftrtrtmnt2OtltNH3SnsrPrlmnrFMI : 16|5@1+ (1,0) [0|31] "binary" Vector__XXX
 SG_ Atttt2OttNH3GsSsHtCt : 40|2@1+ (1,0) [0|3] "" Vector__XXX
 SG_ Atttt2OttNH3GsSsHtPFMI : 32|5@1+ (1,0) [0|31] "binary" Vector__XXX
 SG_ Atttt2OttNH3GsSsPwIR : 26|2@1+ (1,0) [0|3] "" Vector__XXX

BO_ 2364549630 SSI2: 8 Vector__XXX
 SG_ PitchAngleExtendedRange : 0|24@1+ (0.000030517578125,-250) [-250|252] "deg" Vector__XXX
 SG_ PthAnglCmpnstnExtnddRng : 48|2@1+ (1,0) [0|3] "" Vector__XXX
 SG_ PthAnglFgrfMrtExtnddRng : 50|2@1+ (1,0) [0|3] "" Vector__XXX
 SG_ RllAnglCmpnstnExtnddRng : 52|2@1+ (1,0) [0|3] "" Vector__XXX
 SG_ RllAnglFgrfMrtExtnddRng : 54|2@1+ (1,0) [0|3] "" Vector__XXX
 SG_ RllndPthMsrmntLtnExtnddRng : 56|8@1+ (0.5,0) [0|125] "ms" Vector__XXX
 SG_ RollAngleExtendedRange : 24|24@1+ (0.000030517578125,-250) [-250|252] "deg" Vector__XXX

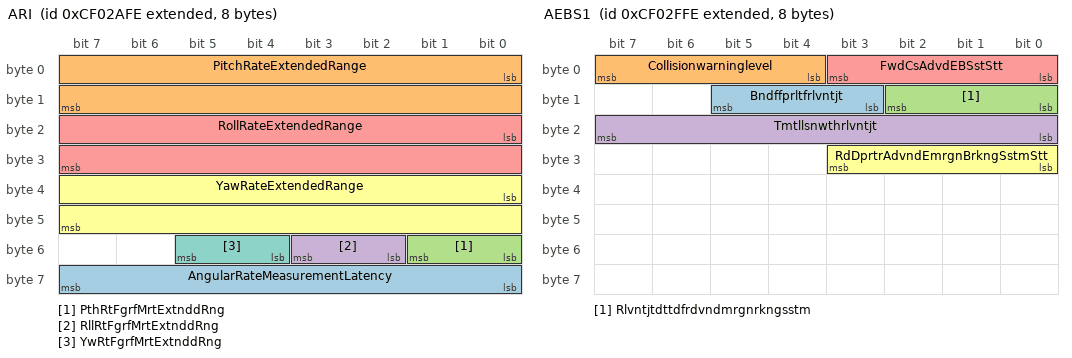
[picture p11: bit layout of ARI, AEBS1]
BO_ 2364549886 ARI: 8 Vector__XXX
 SG_ AngularRateMeasurementLatency : 56|8@1+ (0.5,0) [0|125] "ms" Vector__XXX
 SG_ PitchRateExtendedRange : 0|16@1+ (0.0078125,-250) [-250|250.992] "deg/s" Vector__XXX
 SG_ PthRtFgrfMrtExtnddRng : 48|2@1+ (1,0) [0|3] "" Vector__XXX
 SG_ RllRtFgrfMrtExtnddRng : 50|2@1+ (1,0) [0|3] "" Vector__XXX
 SG_ RollRateExtendedRange : 16|16@1+ (0.0078125,-250) [-250|250.992] "deg/s" Vector__XXX
 SG_ YawRateExtendedRange : 32|16@1+ (0.0078125,-250) [-250|250.992] "deg/s" Vector__XXX
 SG_ YwRtFgrfMrtExtnddRng : 52|2@1+ (1,0) [0|3] "" Vector__XXX

BO_ 2364551166 AEBS1: 8 Vector__XXX
 SG_ Bndffprltfrlvntjt : 11|3@1+ (1,0) [0|7] "" Vector__XXX
 SG_ Collisionwarninglevel : 4|4@1+ (1,0) [0|15] "" Vector__XXX
 SG_ Rlvntjtdttdfrdvndmrgnrkngsstm : 8|3@1+ (1,0) [0|7] "" Vector__XXX
 SG_ Tmtllsnwthrlvntjt : 16|8@1+ (0.05,0) [0|12.5] "s" Vector__XXX
 SG_ FwdCsAdvdEBSstStt : 0|4@1+ (1,0) [0|15] "" Vector__XXX
 SG_ RdDprtrAdvndEmrgnBrkngSstmStt : 24|4@1+ (1,0) [0|15] "" Vector__XXX

BO_ 2364551422 WS: 8 Vector__XXX
 SG_ TransmitterCommandState : 20|4@1+ (1,0) [0|15] "" Vector__XXX
 SG_ TransmitterID1 : 24|24@1+ (1,0) [0|1.64496E+07] "ID" Vector__XXX
 SG_ WirelessRollingMessageCounter : 0|16@1+ (1,0) [0|64255] "count" Vector__XXX
 SG_ WirelessSignalStrength1 : 48|8@1+ (0.5,-125) [-125|0] "dBm" Vector__XXX

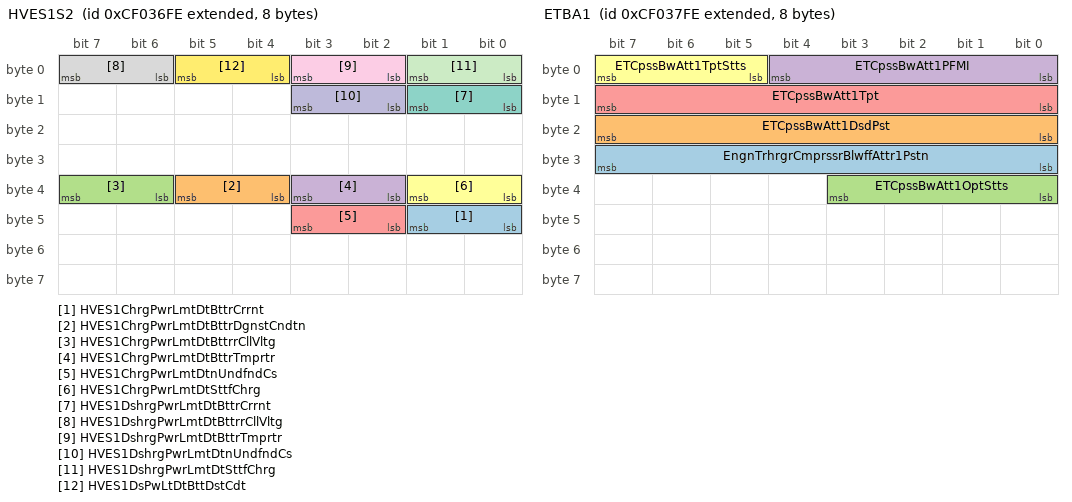
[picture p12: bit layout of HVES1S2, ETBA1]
BO_ 2364552958 HVES1S2: 8 Vector__XXX
 SG_ HVES1ChrgPwrLmtDtBttrCrrnt : 40|2@1+ (1,0) [0|3] "" Vector__XXX
 SG_ HVES1ChrgPwrLmtDtBttrDgnstCndtn : 36|2@1+ (1,0) [0|3] "" Vector__XXX
 SG_ HVES1ChrgPwrLmtDtBttrrCllVltg : 38|2@1+ (1,0) [0|3] "" Vector__XXX
 SG_ HVES1ChrgPwrLmtDtBttrTmprtr : 34|2@1+ (1,0) [0|3] "" Vector__XXX
 SG_ HVES1ChrgPwrLmtDtnUndfndCs : 42|2@1+ (1,0) [0|3] "" Vector__XXX
 SG_ HVES1ChrgPwrLmtDtSttfChrg : 32|2@1+ (1,0) [0|3] "" Vector__XXX
 SG_ HVES1DshrgPwrLmtDtBttrCrrnt : 8|2@1+ (1,0) [0|3] "" Vector__XXX
 SG_ HVES1DshrgPwrLmtDtBttrrCllVltg : 6|2@1+ (1,0) [0|3] "" Vector__XXX
 SG_ HVES1DshrgPwrLmtDtBttrTmprtr : 2|2@1+ (1,0) [0|3] "" Vector__XXX
 SG_ HVES1DshrgPwrLmtDtnUndfndCs : 10|2@1+ (1,0) [0|3] "" Vector__XXX
 SG_ HVES1DshrgPwrLmtDtSttfChrg : 0|2@1+ (1,0) [0|3] "" Vector__XXX
 SG_ HVES1DsPwLtDtBttDstCdt : 4|2@1+ (1,0) [0|3] "" Vector__XXX

BO_ 2364553214 ETBA1: 8 Vector__XXX
 SG_ EngnTrhrgrCmprssrBlwffAttr1Pstn : 24|8@1+ (0.4,0) [0|100] "%" Vector__XXX
 SG_ ETCpssBwAtt1DsdPst : 16|8@1+ (0.4,0) [0|100] "%" Vector__XXX
 SG_ ETCpssBwAtt1OptStts : 32|4@1+ (1,0) [0|15] "" Vector__XXX
 SG_ ETCpssBwAtt1PFMI : 0|5@1+ (1,0) [0|31] "binary" Vector__XXX
 SG_ ETCpssBwAtt1Tpt : 8|8@1+ (1,-40) [-40|210] "degC" Vector__XXX
 SG_ ETCpssBwAtt1TptStts : 5|3@1+ (1,0) [0|7] "" Vector__XXX

BO_ 2364553470 ETFR: 8 Vector__XXX
 SG_ EngineCylinderTorque : 40|16@1+ (1,0) [0|64255] "Nm" Vector__XXX
 SG_ EngineDualFuelModeCommand : 56|2@1+ (1,0) [0|3] "" Vector__XXX
 SG_ EngnClndrDslMssFlwRtCmmnd : 24|16@1+ (0.00006103515625,0) [0|3.921813965] "kg/s" Vector__XXX
 SG_ EngnClndrGsMssFlwRtCmmnd : 8|16@1+ (0.00006103515625,0) [0|3.921813965] "kg/s" Vector__XXX
 SG_ EngnGsSstttnFlPrntgCmmnd : 0|8@1+ (0.5,0) [0|125] "%" Vector__XXX

BO_ 2364553726 EASI: 8 Vector__XXX
 SG_ EngineDesiredAirFuelRatio : 0|16@1+ (0.001,0) [0|64.255] "Ratio" Vector__XXX
 SG_ EngnFlSstm1TtlIntkMssArFlwRt : 16|16@1+ (0.0009765625,0) [0|62.74902344] "kg/s" Vector__XXX
 SG_ EngnFlSstm2TtlIntkMssArFlwRt : 32|16@1+ (0.0009765625,0) [0|62.74902344] "kg/s" Vector__XXX

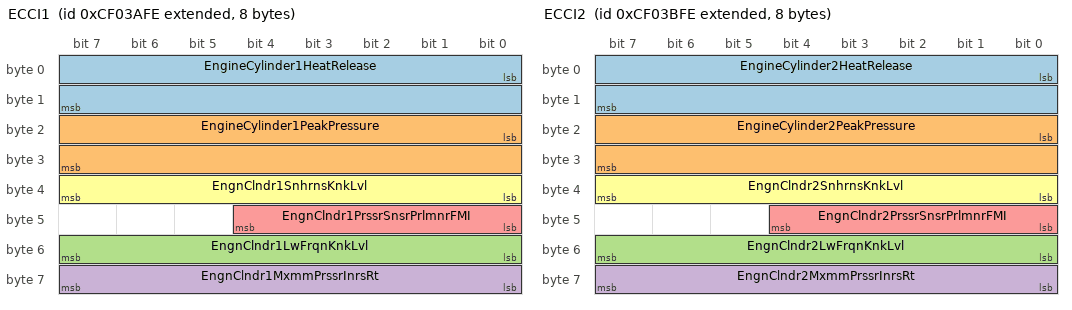
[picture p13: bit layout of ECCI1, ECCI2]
BO_ 2364553982 ECCI1: 8 Vector__XXX
 SG_ EngineCylinder1HeatRelease : 0|16@1+ (0.0001220703125,-1) [-1|6.84362793] "kJ/l" Vector__XXX
 SG_ EngineCylinder1PeakPressure : 16|16@1+ (0.0009765625,0) [0|62.74902344] "MPa" Vector__XXX
 SG_ EngnClndr1LwFrqnKnkLvl : 48|8@1+ (1,0) [0|250] "%" Vector__XXX
 SG_ EngnClndr1MxmmPrssrInrsRt : 56|8@1+ (16,0) [0|4000] "kPa/deg crank angle" Vector__XXX
 SG_ EngnClndr1PrssrSnsrPrlmnrFMI : 40|5@1+ (1,0) [0|31] "binary" Vector__XXX
 SG_ EngnClndr1SnhrnsKnkLvl : 32|8@1+ (1,0) [0|250] "%" Vector__XXX

BO_ 2364554238 ECCI2: 8 Vector__XXX
 SG_ EngineCylinder2HeatRelease : 0|16@1+ (0.0001220703125,-1) [-1|6.84362793] "kJ/l" Vector__XXX
 SG_ EngineCylinder2PeakPressure : 16|16@1+ (0.0009765625,0) [0|62.74902344] "MPa" Vector__XXX
 SG_ EngnClndr2LwFrqnKnkLvl : 48|8@1+ (1,0) [0|250] "%" Vector__XXX
 SG_ EngnClndr2MxmmPrssrInrsRt : 56|8@1+ (16,0) [0|4000] "kPa/deg crank angle" Vector__XXX
 SG_ EngnClndr2PrssrSnsrPrlmnrFMI : 40|5@1+ (1,0) [0|31] "binary" Vector__XXX
 SG_ EngnClndr2SnhrnsKnkLvl : 32|8@1+ (1,0) [0|250] "%" Vector__XXX

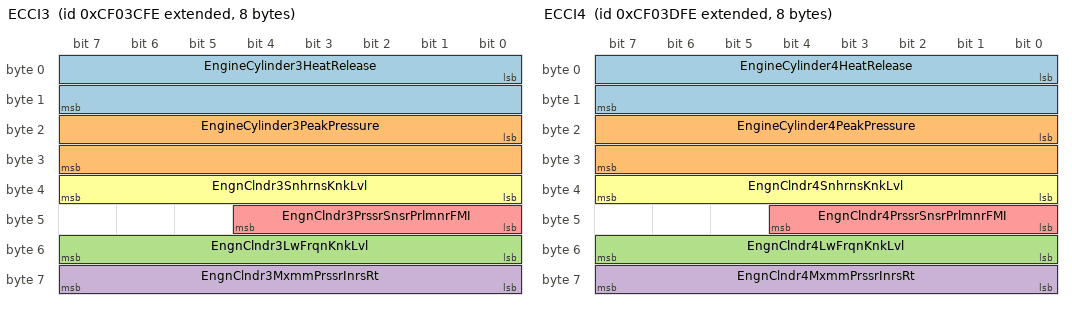
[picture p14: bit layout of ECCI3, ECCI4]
BO_ 2364554494 ECCI3: 8 Vector__XXX
 SG_ EngineCylinder3HeatRelease : 0|16@1+ (0.0001220703125,-1) [-1|6.84362793] "kJ/l" Vector__XXX
 SG_ EngineCylinder3PeakPressure : 16|16@1+ (0.0009765625,0) [0|62.74902344] "MPa" Vector__XXX
 SG_ EngnClndr3LwFrqnKnkLvl : 48|8@1+ (1,0) [0|250] "%" Vector__XXX
 SG_ EngnClndr3MxmmPrssrInrsRt : 56|8@1+ (16,0) [0|4000] "kPa/deg crank angle" Vector__XXX
 SG_ EngnClndr3PrssrSnsrPrlmnrFMI : 40|5@1+ (1,0) [0|31] "binary" Vector__XXX
 SG_ EngnClndr3SnhrnsKnkLvl : 32|8@1+ (1,0) [0|250] "%" Vector__XXX

BO_ 2364554750 ECCI4: 8 Vector__XXX
 SG_ EngineCylinder4HeatRelease : 0|16@1+ (0.0001220703125,-1) [-1|6.84362793] "kJ/l" Vector__XXX
 SG_ EngineCylinder4PeakPressure : 16|16@1+ (0.0009765625,0) [0|62.74902344] "MPa" Vector__XXX
 SG_ EngnClndr4LwFrqnKnkLvl : 48|8@1+ (1,0) [0|250] "%" Vector__XXX
 SG_ EngnClndr4MxmmPrssrInrsRt : 56|8@1+ (16,0) [0|4000] "kPa/deg crank angle" Vector__XXX
 SG_ EngnClndr4PrssrSnsrPrlmnrFMI : 40|5@1+ (1,0) [0|31] "binary" Vector__XXX
 SG_ EngnClndr4SnhrnsKnkLvl : 32|8@1+ (1,0) [0|250] "%" Vector__XXX

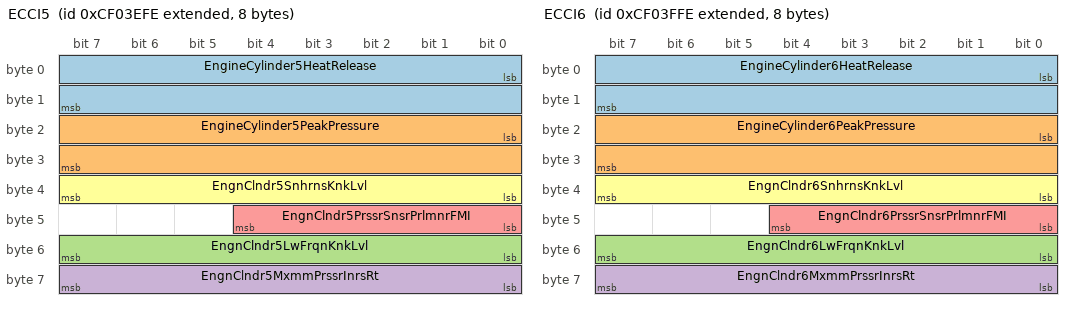
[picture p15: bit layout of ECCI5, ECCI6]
BO_ 2364555006 ECCI5: 8 Vector__XXX
 SG_ EngineCylinder5HeatRelease : 0|16@1+ (0.0001220703125,-1) [-1|6.84362793] "kJ/l" Vector__XXX
 SG_ EngineCylinder5PeakPressure : 16|16@1+ (0.0009765625,0) [0|62.74902344] "MPa" Vector__XXX
 SG_ EngnClndr5LwFrqnKnkLvl : 48|8@1+ (1,0) [0|250] "%" Vector__XXX
 SG_ EngnClndr5MxmmPrssrInrsRt : 56|8@1+ (16,0) [0|4000] "kPa/deg crank angle" Vector__XXX
 SG_ EngnClndr5PrssrSnsrPrlmnrFMI : 40|5@1+ (1,0) [0|31] "binary" Vector__XXX
 SG_ EngnClndr5SnhrnsKnkLvl : 32|8@1+ (1,0) [0|250] "%" Vector__XXX

BO_ 2364555262 ECCI6: 8 Vector__XXX
 SG_ EngineCylinder6HeatRelease : 0|16@1+ (0.0001220703125,-1) [-1|6.84362793] "kJ/l" Vector__XXX
 SG_ EngineCylinder6PeakPressure : 16|16@1+ (0.0009765625,0) [0|62.74902344] "MPa" Vector__XXX
 SG_ EngnClndr6LwFrqnKnkLvl : 48|8@1+ (1,0) [0|250] "%" Vector__XXX
 SG_ EngnClndr6MxmmPrssrInrsRt : 56|8@1+ (16,0) [0|4000] "kPa/deg crank angle" Vector__XXX
 SG_ EngnClndr6PrssrSnsrPrlmnrFMI : 40|5@1+ (1,0) [0|31] "binary" Vector__XXX
 SG_ EngnClndr6SnhrnsKnkLvl : 32|8@1+ (1,0) [0|250] "%" Vector__XXX

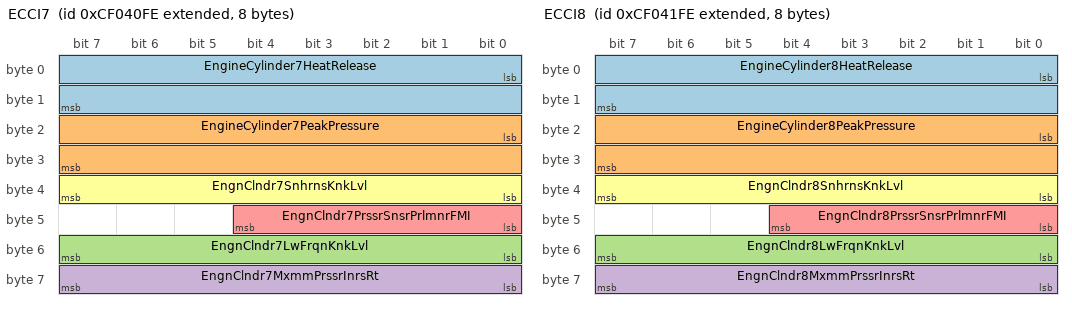
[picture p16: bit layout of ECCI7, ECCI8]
BO_ 2364555518 ECCI7: 8 Vector__XXX
 SG_ EngineCylinder7HeatRelease : 0|16@1+ (0.0001220703125,-1) [-1|6.84362793] "kJ/l" Vector__XXX
 SG_ EngineCylinder7PeakPressure : 16|16@1+ (0.0009765625,0) [0|62.74902344] "MPa" Vector__XXX
 SG_ EngnClndr7LwFrqnKnkLvl : 48|8@1+ (1,0) [0|250] "%" Vector__XXX
 SG_ EngnClndr7MxmmPrssrInrsRt : 56|8@1+ (16,0) [0|4000] "kPa/deg crank angle" Vector__XXX
 SG_ EngnClndr7PrssrSnsrPrlmnrFMI : 40|5@1+ (1,0) [0|31] "binary" Vector__XXX
 SG_ EngnClndr7SnhrnsKnkLvl : 32|8@1+ (1,0) [0|250] "%" Vector__XXX

BO_ 2364555774 ECCI8: 8 Vector__XXX
 SG_ EngineCylinder8HeatRelease : 0|16@1+ (0.0001220703125,-1) [-1|6.84362793] "kJ/l" Vector__XXX
 SG_ EngineCylinder8PeakPressure : 16|16@1+ (0.0009765625,0) [0|62.74902344] "MPa" Vector__XXX
 SG_ EngnClndr8LwFrqnKnkLvl : 48|8@1+ (1,0) [0|250] "%" Vector__XXX
 SG_ EngnClndr8MxmmPrssrInrsRt : 56|8@1+ (16,0) [0|4000] "kPa/deg crank angle" Vector__XXX
 SG_ EngnClndr8PrssrSnsrPrlmnrFMI : 40|5@1+ (1,0) [0|31] "binary" Vector__XXX
 SG_ EngnClndr8SnhrnsKnkLvl : 32|8@1+ (1,0) [0|250] "%" Vector__XXX

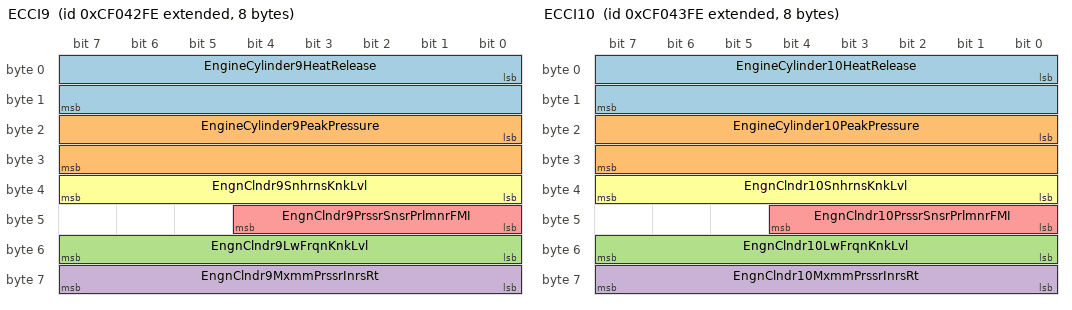
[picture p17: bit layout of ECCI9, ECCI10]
BO_ 2364556030 ECCI9: 8 Vector__XXX
 SG_ EngineCylinder9HeatRelease : 0|16@1+ (0.0001220703125,-1) [-1|6.84362793] "kJ/l" Vector__XXX
 SG_ EngineCylinder9PeakPressure : 16|16@1+ (0.0009765625,0) [0|62.74902344] "MPa" Vector__XXX
 SG_ EngnClndr9LwFrqnKnkLvl : 48|8@1+ (1,0) [0|250] "%" Vector__XXX
 SG_ EngnClndr9MxmmPrssrInrsRt : 56|8@1+ (16,0) [0|4000] "kPa/deg crank angle" Vector__XXX
 SG_ EngnClndr9PrssrSnsrPrlmnrFMI : 40|5@1+ (1,0) [0|31] "binary" Vector__XXX
 SG_ EngnClndr9SnhrnsKnkLvl : 32|8@1+ (1,0) [0|250] "%" Vector__XXX

BO_ 2364556286 ECCI10: 8 Vector__XXX
 SG_ EngineCylinder10HeatRelease : 0|16@1+ (0.0001220703125,-1) [-1|6.84362793] "kJ/l" Vector__XXX
 SG_ EngineCylinder10PeakPressure : 16|16@1+ (0.0009765625,0) [0|62.74902344] "MPa" Vector__XXX
 SG_ EngnClndr10LwFrqnKnkLvl : 48|8@1+ (1,0) [0|250] "%" Vector__XXX
 SG_ EngnClndr10MxmmPrssrInrsRt : 56|8@1+ (16,0) [0|4000] "kPa/deg crank angle" Vector__XXX
 SG_ EngnClndr10PrssrSnsrPrlmnrFMI : 40|5@1+ (1,0) [0|31] "binary" Vector__XXX
 SG_ EngnClndr10SnhrnsKnkLvl : 32|8@1+ (1,0) [0|250] "%" Vector__XXX

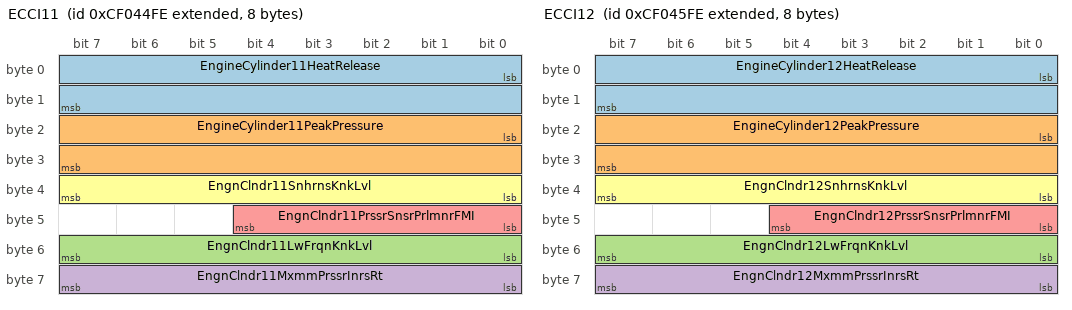
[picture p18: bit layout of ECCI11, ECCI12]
BO_ 2364556542 ECCI11: 8 Vector__XXX
 SG_ EngineCylinder11HeatRelease : 0|16@1+ (0.0001220703125,-1) [-1|6.84362793] "kJ/l" Vector__XXX
 SG_ EngineCylinder11PeakPressure : 16|16@1+ (0.0009765625,0) [0|62.74902344] "MPa" Vector__XXX
 SG_ EngnClndr11LwFrqnKnkLvl : 48|8@1+ (1,0) [0|250] "%" Vector__XXX
 SG_ EngnClndr11MxmmPrssrInrsRt : 56|8@1+ (16,0) [0|4000] "kPa/deg crank angle" Vector__XXX
 SG_ EngnClndr11PrssrSnsrPrlmnrFMI : 40|5@1+ (1,0) [0|31] "binary" Vector__XXX
 SG_ EngnClndr11SnhrnsKnkLvl : 32|8@1+ (1,0) [0|250] "%" Vector__XXX

BO_ 2364556798 ECCI12: 8 Vector__XXX
 SG_ EngineCylinder12HeatRelease : 0|16@1+ (0.0001220703125,-1) [-1|6.84362793] "kJ/l" Vector__XXX
 SG_ EngineCylinder12PeakPressure : 16|16@1+ (0.0009765625,0) [0|62.74902344] "MPa" Vector__XXX
 SG_ EngnClndr12LwFrqnKnkLvl : 48|8@1+ (1,0) [0|250] "%" Vector__XXX
 SG_ EngnClndr12MxmmPrssrInrsRt : 56|8@1+ (16,0) [0|4000] "kPa/deg crank angle" Vector__XXX
 SG_ EngnClndr12PrssrSnsrPrlmnrFMI : 40|5@1+ (1,0) [0|31] "binary" Vector__XXX
 SG_ EngnClndr12SnhrnsKnkLvl : 32|8@1+ (1,0) [0|250] "%" Vector__XXX

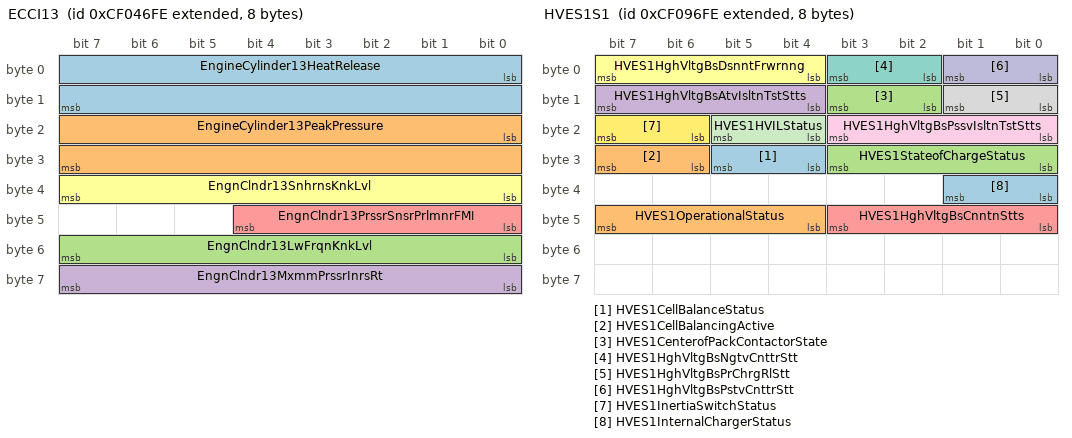
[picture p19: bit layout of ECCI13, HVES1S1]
BO_ 2364557054 ECCI13: 8 Vector__XXX
 SG_ EngineCylinder13HeatRelease : 0|16@1+ (0.0001220703125,-1) [-1|6.84362793] "kJ/l" Vector__XXX
 SG_ EngineCylinder13PeakPressure : 16|16@1+ (0.0009765625,0) [0|62.74902344] "MPa" Vector__XXX
 SG_ EngnClndr13LwFrqnKnkLvl : 48|8@1+ (1,0) [0|250] "%" Vector__XXX
 SG_ EngnClndr13MxmmPrssrInrsRt : 56|8@1+ (16,0) [0|4000] "kPa/deg crank angle" Vector__XXX
 SG_ EngnClndr13PrssrSnsrPrlmnrFMI : 40|5@1+ (1,0) [0|31] "binary" Vector__XXX
 SG_ EngnClndr13SnhrnsKnkLvl : 32|8@1+ (1,0) [0|250] "%" Vector__XXX

BO_ 2364557310 ECCI14: 8 Vector__XXX
 SG_ EngineCylinder14HeatRelease : 0|16@1+ (0.0001220703125,-1) [-1|6.84362793] "kJ/l" Vector__XXX
 SG_ EngineCylinder14PeakPressure : 16|16@1+ (0.0009765625,0) [0|62.74902344] "MPa" Vector__XXX
 SG_ EngnClndr14LwFrqnKnkLvl : 48|8@1+ (1,0) [0|250] "%" Vector__XXX
 SG_ EngnClndr14MxmmPrssrInrsRt : 56|8@1+ (16,0) [0|4000] "kPa/deg crank angle" Vector__XXX
 SG_ EngnClndr14PrssrSnsrPrlmnrFMI : 40|5@1+ (1,0) [0|31] "binary" Vector__XXX
 SG_ EngnClndr14SnhrnsKnkLvl : 32|8@1+ (1,0) [0|250] "%" Vector__XXX

BO_ 2364557566 ECCI15: 8 Vector__XXX
 SG_ EngineCylinder15HeatRelease : 0|16@1+ (0.0001220703125,-1) [-1|6.84362793] "kJ/l" Vector__XXX
 SG_ EngineCylinder15PeakPressure : 16|16@1+ (0.0009765625,0) [0|62.74902344] "MPa" Vector__XXX
 SG_ EngnClndr15LwFrqnKnkLvl : 48|8@1+ (1,0) [0|250] "%" Vector__XXX
 SG_ EngnClndr15MxmmPrssrInrsRt : 56|8@1+ (16,0) [0|4000] "kPa/deg crank angle" Vector__XXX
 SG_ EngnClndr15PrssrSnsrPrlmnrFMI : 40|5@1+ (1,0) [0|31] "binary" Vector__XXX
 SG_ EngnClndr15SnhrnsKnkLvl : 32|8@1+ (1,0) [0|250] "%" Vector__XXX

BO_ 2364557822 ECCI16: 8 Vector__XXX
 SG_ EngineCylinder16HeatRelease : 0|16@1+ (0.0001220703125,-1) [-1|6.84362793] "kJ/l" Vector__XXX
 SG_ EngineCylinder16PeakPressure : 16|16@1+ (0.0009765625,0) [0|62.74902344] "MPa" Vector__XXX
 SG_ EngnClndr16LwFrqnKnkLvl : 48|8@1+ (1,0) [0|250] "%" Vector__XXX
 SG_ EngnClndr16MxmmPrssrInrsRt : 56|8@1+ (16,0) [0|4000] "kPa/deg crank angle" Vector__XXX
 SG_ EngnClndr16PrssrSnsrPrlmnrFMI : 40|5@1+ (1,0) [0|31] "binary" Vector__XXX
 SG_ EngnClndr16SnhrnsKnkLvl : 32|8@1+ (1,0) [0|250] "%" Vector__XXX

BO_ 2364558078 ECCI17: 8 Vector__XXX
 SG_ EngineCylinder17HeatRelease : 0|16@1+ (0.0001220703125,-1) [-1|6.84362793] "kJ/l" Vector__XXX
 SG_ EngineCylinder17PeakPressure : 16|16@1+ (0.0009765625,0) [0|62.74902344] "MPa" Vector__XXX
 SG_ EngnClndr17LwFrqnKnkLvl : 48|8@1+ (1,0) [0|250] "%" Vector__XXX
 SG_ EngnClndr17MxmmPrssrInrsRt : 56|8@1+ (16,0) [0|4000] "kPa/deg crank angle" Vector__XXX
 SG_ EngnClndr17PrssrSnsrPrlmnrFMI : 40|5@1+ (1,0) [0|31] "binary" Vector__XXX
 SG_ EngnClndr17SnhrnsKnkLvl : 32|8@1+ (1,0) [0|250] "%" Vector__XXX

BO_ 2364558334 ECCI18: 8 Vector__XXX
 SG_ EngineCylinder18HeatRelease : 0|16@1+ (0.0001220703125,-1) [-1|6.84362793] "kJ/l" Vector__XXX
 SG_ EngineCylinder18PeakPressure : 16|16@1+ (0.0009765625,0) [0|62.74902344] "MPa" Vector__XXX
 SG_ EngnClndr18LwFrqnKnkLvl : 48|8@1+ (1,0) [0|250] "%" Vector__XXX
 SG_ EngnClndr18MxmmPrssrInrsRt : 56|8@1+ (16,0) [0|4000] "kPa/deg crank angle" Vector__XXX
 SG_ EngnClndr18PrssrSnsrPrlmnrFMI : 40|5@1+ (1,0) [0|31] "binary" Vector__XXX
 SG_ EngnClndr18SnhrnsKnkLvl : 32|8@1+ (1,0) [0|250] "%" Vector__XXX

BO_ 2364558590 ECCI19: 8 Vector__XXX
 SG_ EngineCylinder19HeatRelease : 0|16@1+ (0.0001220703125,-1) [-1|6.84362793] "kJ/l" Vector__XXX
 SG_ EngineCylinder19PeakPressure : 16|16@1+ (0.0009765625,0) [0|62.74902344] "MPa" Vector__XXX
 SG_ EngnClndr19LwFrqnKnkLvl : 48|8@1+ (1,0) [0|250] "%" Vector__XXX
 SG_ EngnClndr19MxmmPrssrInrsRt : 56|8@1+ (16,0) [0|4000] "kPa/deg crank angle" Vector__XXX
 SG_ EngnClndr19PrssrSnsrPrlmnrFMI : 40|5@1+ (1,0) [0|31] "binary" Vector__XXX
 SG_ EngnClndr19SnhrnsKnkLvl : 32|8@1+ (1,0) [0|250] "%" Vector__XXX

BO_ 2364558846 ECCI20: 8 Vector__XXX
 SG_ EngineCylinder20HeatRelease : 0|16@1+ (0.0001220703125,-1) [-1|6.84362793] "kJ/l" Vector__XXX
 SG_ EngineCylinder20PeakPressure : 16|16@1+ (0.0009765625,0) [0|62.74902344] "MPa" Vector__XXX
 SG_ EngnClndr20LwFrqnKnkLvl : 48|8@1+ (1,0) [0|250] "%" Vector__XXX
 SG_ EngnClndr20MxmmPrssrInrsRt : 56|8@1+ (16,0) [0|4000] "kPa/deg crank angle" Vector__XXX
 SG_ EngnClndr20PrssrSnsrPrlmnrFMI : 40|5@1+ (1,0) [0|31] "binary" Vector__XXX
 SG_ EngnClndr20SnhrnsKnkLvl : 32|8@1+ (1,0) [0|250] "%" Vector__XXX

BO_ 2364564478 GFI5: 8 Vector__XXX
 SG_ EngnGssFlVlvNmnlDrtnCmmnd : 0|16@1+ (2,0) [0|128510] "micro s" Vector__XXX
 SG_ EngnGssFlVlvNmnlStrtfAttnCmmnd : 16|16@1+ (0.0078125,-400) [-400|101.99] "deg" Vector__XXX
 SG_ EngnPrChmrFlVlvNmnlDrtnCmmnd : 32|16@1+ (2,0) [0|128510] "micro s" Vector__XXX
 SG_ EPCFVvNSttAttCd : 48|16@1+ (0.0078125,-400) [-400|101.99] "deg" Vector__XXX

BO_ 2364564734 EGFVDC1: 8 Vector__XXX
 SG_ EngnGssFlVlv1DrtnCmmnd : 0|16@1+ (2,0) [0|128510] "micro s" Vector__XXX
 SG_ EngnGssFlVlv2DrtnCmmnd : 16|16@1+ (2,0) [0|128510] "micro s" Vector__XXX
 SG_ EngnGssFlVlv3DrtnCmmnd : 32|16@1+ (2,0) [0|128510] "micro s" Vector__XXX
 SG_ EngnGssFlVlv4DrtnCmmnd : 48|16@1+ (2,0) [0|128510] "micro s" Vector__XXX

BO_ 2364564990 EGFVDC2: 8 Vector__XXX
 SG_ EngnGssFlVlv5DrtnCmmnd : 0|16@1+ (2,0) [0|128510] "micro s" Vector__XXX
 SG_ EngnGssFlVlv6DrtnCmmnd : 16|16@1+ (2,0) [0|128510] "micro s" Vector__XXX
 SG_ EngnGssFlVlv7DrtnCmmnd : 32|16@1+ (2,0) [0|128510] "micro s" Vector__XXX
 SG_ EngnGssFlVlv8DrtnCmmnd : 48|16@1+ (2,0) [0|128510] "micro s" Vector__XXX

BO_ 2364565246 EGFVDC3: 8 Vector__XXX
 SG_ EngnGssFlVlv10DrtnCmmnd : 16|16@1+ (2,0) [0|128510] "micro s" Vector__XXX
 SG_ EngnGssFlVlv11DrtnCmmnd : 32|16@1+ (2,0) [0|128510] "micro s" Vector__XXX
 SG_ EngnGssFlVlv12DrtnCmmnd : 48|16@1+ (2,0) [0|128510] "micro s" Vector__XXX
 SG_ EngnGssFlVlv9DrtnCmmnd : 0|16@1+ (2,0) [0|128510] "micro s" Vector__XXX

BO_ 2364565502 EGFVDC4: 8 Vector__XXX
 SG_ EngnGssFlVlv13DrtnCmmnd : 0|16@1+ (2,0) [0|128510] "micro s" Vector__XXX
 SG_ EngnGssFlVlv14DrtnCmmnd : 16|16@1+ (2,0) [0|128510] "micro s" Vector__XXX
 SG_ EngnGssFlVlv15DrtnCmmnd : 32|16@1+ (2,0) [0|128510] "micro s" Vector__XXX
 SG_ EngnGssFlVlv16DrtnCmmnd : 48|16@1+ (2,0) [0|128510] "micro s" Vector__XXX

BO_ 2364565758 EGFVDC5: 8 Vector__XXX
 SG_ EngnGssFlVlv17DrtnCmmnd : 0|16@1+ (2,0) [0|128510] "micro s" Vector__XXX
 SG_ EngnGssFlVlv18DrtnCmmnd : 16|16@1+ (2,0) [0|128510] "micro s" Vector__XXX
 SG_ EngnGssFlVlv19DrtnCmmnd : 32|16@1+ (2,0) [0|128510] "micro s" Vector__XXX
 SG_ EngnGssFlVlv20DrtnCmmnd : 48|16@1+ (2,0) [0|128510] "micro s" Vector__XXX

BO_ 2364566014 EGFVSOAC1: 8 Vector__XXX
 SG_ EngnGssFlVlv1StrtfAttnCmmnd : 0|16@1+ (0.0078125,-400) [-400|101.99] "deg" Vector__XXX
 SG_ EngnGssFlVlv2StrtfAttnCmmnd : 16|16@1+ (0.0078125,-400) [-400|101.99] "deg" Vector__XXX
 SG_ EngnGssFlVlv3StrtfAttnCmmnd : 32|16@1+ (0.0078125,-400) [-400|101.99] "deg" Vector__XXX
 SG_ EngnGssFlVlv4StrtfAttnCmmnd : 48|16@1+ (0.0078125,-400) [-400|101.99] "deg" Vector__XXX

BO_ 2364566270 EGFVSOAC2: 8 Vector__XXX
 SG_ EngnGssFlVlv5StrtfAttnCmmnd : 0|16@1+ (0.0078125,-400) [-400|101.99] "deg" Vector__XXX
 SG_ EngnGssFlVlv6StrtfAttnCmmnd : 16|16@1+ (0.0078125,-400) [-400|101.99] "deg" Vector__XXX
 SG_ EngnGssFlVlv7StrtfAttnCmmnd : 32|16@1+ (0.0078125,-400) [-400|101.99] "deg" Vector__XXX
 SG_ EngnGssFlVlv8StrtfAttnCmmnd : 48|16@1+ (0.0078125,-400) [-400|101.99] "deg" Vector__XXX

BO_ 2364566526 EGFVSOAC3: 8 Vector__XXX
 SG_ EngnGssFlVlv10StrtfAttnCmmnd : 16|16@1+ (0.0078125,-400) [-400|101.99] "deg" Vector__XXX
 SG_ EngnGssFlVlv11StrtfAttnCmmnd : 32|16@1+ (0.0078125,-400) [-400|101.99] "deg" Vector__XXX
 SG_ EngnGssFlVlv12StrtfAttnCmmnd : 48|16@1+ (0.0078125,-400) [-400|101.99] "deg" Vector__XXX
 SG_ EngnGssFlVlv9StrtfAttnCmmnd : 0|16@1+ (0.0078125,-400) [-400|101.99] "deg" Vector__XXX

BO_ 2364566782 EGFVSOAC4: 8 Vector__XXX
 SG_ EngnGssFlVlv13StrtfAttnCmmnd : 0|16@1+ (0.0078125,-400) [-400|101.99] "deg" Vector__XXX
 SG_ EngnGssFlVlv14StrtfAttnCmmnd : 16|16@1+ (0.0078125,-400) [-400|101.99] "deg" Vector__XXX
 SG_ EngnGssFlVlv15StrtfAttnCmmnd : 32|16@1+ (0.0078125,-400) [-400|101.99] "deg" Vector__XXX
 SG_ EngnGssFlVlv16StrtfAttnCmmnd : 48|16@1+ (0.0078125,-400) [-400|101.99] "deg" Vector__XXX

BO_ 2364567038 EGFVSOAC5: 8 Vector__XXX
 SG_ EngnGssFlVlv17StrtfAttnCmmnd : 0|16@1+ (0.0078125,-400) [-400|101.99] "deg" Vector__XXX
 SG_ EngnGssFlVlv18StrtfAttnCmmnd : 16|16@1+ (0.0078125,-400) [-400|101.99] "deg" Vector__XXX
 SG_ EngnGssFlVlv19StrtfAttnCmmnd : 32|16@1+ (0.0078125,-400) [-400|101.99] "deg" Vector__XXX
 SG_ EngnGssFlVlv20StrtfAttnCmmnd : 48|16@1+ (0.0078125,-400) [-400|101.99] "deg" Vector__XXX

BO_ 2364567294 FPAC: 8 Vector__XXX
 SG_ EngnFlInjtnPmp1FlCntrlVlvCmmnd : 0|16@1+ (0.0025,0) [0|160.6375] "%" Vector__XXX
 SG_ EngnFlInjtnPmp2FlCntrlVlvCmmnd : 16|16@1+ (0.0025,0) [0|160.6375] "%" Vector__XXX

BO_ 2364575998 HVES1D1: 8 Vector__XXX
 SG_ HVES1AvailableChargePower : 16|16@1+ (0.05,0) [0|3212.75] "kW" Vector__XXX
 SG_ HVES1AvailableDischargePower : 0|16@1+ (0.05,0) [0|3212.75] "kW" Vector__XXX
 SG_ HVES1Current : 48|16@1+ (0.05,-1600) [-1600|1612.75] "A" Vector__XXX
 SG_ HVES1VoltageLevel : 32|16@1+ (0.05,0) [0|3212.75] "V" Vector__XXX

BO_ 2364576254 HVES1D2: 8 Vector__XXX
 SG_ HVES1CllVltgDffrntlStts : 48|4@1+ (1,0) [0|15] "" Vector__XXX
 SG_ HVES1FastUpdateStateofCharge : 0|16@1+ (0.0015625,0) [0|100.3984375] "%" Vector__XXX
 SG_ HVES1HighestCellVoltage : 16|16@1+ (0.001,0) [0|64.255] "V" Vector__XXX
 SG_ HVES1LowestCellVoltage : 32|16@1+ (0.001,0) [0|64.255] "V" Vector__XXX

BO_ 2364576510 HVES1D3: 8 Vector__XXX
 SG_ HVES1AverageCellTemperature : 32|16@1+ (0.03125,-273) [-273|1734.96875] "degC" Vector__XXX
 SG_ HVES1CllTmprtrDffrntlStts : 48|2@1+ (1,0) [0|3] "" Vector__XXX
 SG_ HVES1HighestCellTemperature : 0|16@1+ (0.03125,-273) [-273|1734.96875] "degC" Vector__XXX
 SG_ HVES1LowestCellTemperature : 16|16@1+ (0.03125,-273) [-273|1734.96875] "degC" Vector__XXX

BO_ 2364576766 HVES1D4: 8 Vector__XXX
 SG_ HVES1CellBalancingCount : 32|16@1+ (1,0) [0|64255] "count" Vector__XXX
 SG_ HVES1ChargeCapacity : 16|16@1+ (0.01,0) [0|642.55] "Ah" Vector__XXX
 SG_ HVES1DischargeCapacity : 0|16@1+ (0.01,0) [0|642.55] "Ah" Vector__XXX

BO_ 2364577022 HVES1D5: 8 Vector__XXX
 SG_ HVES1ChargeCurrentLimit : 16|16@1+ (0.05,-1600) [-1600|1612.75] "A" Vector__XXX
 SG_ HVES1DischargeCurrentLimit : 0|16@1+ (0.05,-1600) [-1600|1612.75] "A" Vector__XXX
 SG_ HVES1MaximumCellStateofCharge : 48|16@1+ (0.0015625,0) [0|100.3984375] "%" Vector__XXX
 SG_ HVES1MinimumCellStateofCharge : 32|16@1+ (0.0015625,0) [0|100.3984375] "%" Vector__XXX

BO_ 2364577278 HVES1D6: 8 Vector__XXX
 SG_ HVES1BusVoltage : 0|16@1+ (0.05,0) [0|3212.75] "V" Vector__XXX
 SG_ HVES1ElectronicsTemperature : 48|8@1+ (1,-40) [-40|210] "degC" Vector__XXX
 SG_ HVES1IgnitionVoltage : 16|16@1+ (0.01,0) [0|642.55] "V" Vector__XXX
 SG_ HVES1IntakeCoolantTemperature : 32|8@1+ (1,-40) [-40|210] "degC" Vector__XXX
 SG_ HVES1OutletCoolantTemperature : 40|8@1+ (1,-40) [-40|210] "degC" Vector__XXX
 SG_ HVES1Temperature : 56|8@1+ (1,-40) [-40|210] "degC" Vector__XXX

BO_ 2364577534 HVES1S1: 8 Vector__XXX
 SG_ HVES1CellBalanceStatus : 28|2@1+ (1,0) [0|3] "" Vector__XXX
 SG_ HVES1CellBalancingActive : 30|2@1+ (1,0) [0|3] "" Vector__XXX
 SG_ HVES1CenterofPackContactorState : 10|2@1+ (1,0) [0|3] "" Vector__XXX
 SG_ HVES1HghVltgBsAtvIsltnTstStts : 12|4@1+ (1,0) [0|15] "" Vector__XXX
 SG_ HVES1HghVltgBsCnntnStts : 40|4@1+ (1,0) [0|15] "" Vector__XXX
 SG_ HVES1HghVltgBsDsnntFrwrnng : 4|4@1+ (1,0) [0|15] "" Vector__XXX
 SG_ HVES1HghVltgBsNgtvCnttrStt : 2|2@1+ (1,0) [0|3] "" Vector__XXX
 SG_ HVES1HghVltgBsPrChrgRlStt : 8|2@1+ (1,0) [0|3] "" Vector__XXX
 SG_ HVES1HghVltgBsPssvIsltnTstStts : 16|4@1+ (1,0) [0|15] "" Vector__XXX
 SG_ HVES1HghVltgBsPstvCnttrStt : 0|2@1+ (1,0) [0|3] "" Vector__XXX
 SG_ HVES1HVILStatus : 20|2@1+ (1,0) [0|3] "" Vector__XXX
 SG_ HVES1InertiaSwitchStatus : 22|2@1+ (1,0) [0|3] "" Vector__XXX
 SG_ HVES1InternalChargerStatus : 32|2@1+ (1,0) [0|3] "" Vector__XXX
 SG_ HVES1OperationalStatus : 44|4@1+ (1,0) [0|15] "" Vector__XXX
 SG_ HVES1StateofChargeStatus : 24|4@1+ (1,0) [0|15] "" Vector__XXX

BO_ 2364580094 HVES1D7: 8 Vector__XXX
 SG_ HVES1ChargeEnergyCapacity : 24|24@1+ (0.001,0) [0|16449.535] "kWh" Vector__XXX
 SG_ HVES1DischargeEnergyCapacity : 0|24@1+ (0.001,0) [0|16449.535] "kWh" Vector__XXX
 SG_ HVES1MaximumChargeVoltageLimit : 48|16@1+ (0.05,0) [0|3212.75] "V" Vector__XXX

CM_ BO_ 2163223550 "Crash Notification";
CM_ SG_ 2163223550 CrashChecksum "The Crash Checksum is used to verify the signal path from the airbag ECU to other devices in case of a crash.The 4 bit checksum is the sum of the high nibble an…";
CM_ SG_ 2163223550 CrashCounter "The Crash Counter prevents other ECUs from reacting to a faulty transmission of the Crash Notification PGN and serves as a safety mechanism. The Crash Counter b…";
CM_ SG_ 2163223550 CrashType "Type of crash event. 00001b = frontal crash00010b = rear crash00100b = side crash (left)01000b = side crash (right)10000b = rolloverIt is possible to combine di…";
CM_ BO_ 2230333950 "Wand Sensor";
CM_ SG_ 2230333950 WandAngle "A wand sensor measures the angle of deflection of a wand from its null position. This parameter reports the measured angle of a wand sensor.…";
CM_ SG_ 2230333950 WandSensorFigureofMerit "Figure of Merit sensor status for a wand sensor.00b = Sensor fully functional01b = Sensor degraded10b = Sensor failed11b = Sensor not available…";
CM_ BO_ 2230334206 "Linear Displacement Sensor";
CM_ SG_ 2230334206 LnrDsplmntSnsrSnsrFgrfMrt "Figure of Merit sensor status of Linear Displacement Sensor.00b = Sensor fully functional01b = Sensor degraded10b = Sensor failed11b = Sensor not available…";
CM_ SG_ 2230334206 MeasuredLinearDisplacement "Distance to target as measured by the Linear Displacement Sensor.…";
CM_ BO_ 2297441534 "Magnet Status Information 2";
CM_ SG_ 2297441534 DropRelayControl "Command signal used to Engage and Disengage the Drop Relay controlling a Steady-State Magnet.00b = Off, Disable Drop Relay Request01b = On, Enable Drop Relay Re…";
CM_ SG_ 2297441534 GnrtrCrrntBstAtvStts "Status of generator current boost relay that can boost the generator output current for picking-up material operations. When this relay is on, the generator is …";
CM_ SG_ 2297441534 LiftRelayControl "Command signal used to Engage and Disengage the Lift Relay controlling a Steady-State Magnet.00b = Off, Disable Lift Relay Request 01b = On, Enable Lift Relay R…";
CM_ SG_ 2297441534 MagnetForwardCurrent "The forward current being supplied by the generator to the electric magnet to create a magnet field to lift material.…";
CM_ SG_ 2297441534 MagnetGeneratorControl "Command signal used to Enable and Disable the Generator controlling a Magnet.00b = Off, Disable Generator01b = On, Enable Generator10b = Reserved11b = Take No A…";
CM_ SG_ 2297441534 MagnetReverseCurrent "A reverse current being supplied to the electric magnet to reduce the forward current generated magnet field as quick as possible so that the magnet can release…";
CM_ SG_ 2297441534 MaterialDropActiveStatus "The status of Material Drop Relay. When it is on, the generator generates reverse direction current so that the material handler machine can release material.00…";
CM_ SG_ 2297441534 MaterialDropSwitch "This is a switch that can be used to enable the drop functionality of the Material Handler machine.00b = Don't Drop01b = Drop10b = Error11b = Not Available…";
CM_ SG_ 2297441534 MaterialLiftActiveStatus "The status of Material Lift Relay. When it is on, the generator generates forward direction current so that the material handler machine can pick up material.00…";
CM_ SG_ 2297441534 MaterialLiftSwitch "This is a switch that can be used to enable the lift functionality of the Material Handler machine. When it is activated, the magnet is energized to pick up mat…";
CM_ BO_ 2297441790 "Acceleration Sensor";
CM_ SG_ 2297441790 LngtdnlAlrtnExtnddRng "Indicates longitudinal acceleration of the vehicle (the component of vehicle acceleration vector along the X-axis).  A positive longitudinal acceleration signal…";
CM_ SG_ 2297441790 LngtdnlAlrtnFgrfMrtExtnddRng "Figure of merit for longitudinal acceleration measurement.00b = longitudinal acceleration is fully functional.  Data is within sensor specification01b = longitu…";
CM_ SG_ 2297441790 LtrlAlrtnExtnddRng "Indicates lateral acceleration of the vehicle (the component of vehicle acceleration vector along the Y-axis).  A positive lateral acceleration signal results w…";
CM_ SG_ 2297441790 LtrlAlrtnFgrfMrtExtnddRng "Figure of merit for lateral acceleration measurement.00b = lateral acceleration is fully functional.  Data is within sensor specification01b = lateral accelerat…";
CM_ SG_ 2297441790 SpptVTsssRpttRtAtSs "Indicates which acceleration transmission rate are supported by the ECU in addition to the required 10 ms transmission rate.00 = Reserve for SAE assignment01 = …";
CM_ SG_ 2297441790 VrtlAlrtnExtnddRng "Indicates vertical acceleration of the vehicle and the effect of gravity (the component of vehicle acceleration vector along the Z-axis).  A positive vertical a…";
CM_ SG_ 2297441790 VrtlAlrtnFgrfMrtExtnddRng "Figure of merit for vertical acceleration measurement.00b = vertical acceleration is fully functional.  Data is within sensor specification01b = verticalacceler…";
CM_ BO_ 2297455358 "Electronic Transmission Controller #12";
CM_ SG_ 2297455358 TrnsmssnDrtnlOtptShftSpd "The rotational velocity and direction of the output shaft. Positive values are used for forward vehicle motion, negative values for reverse vehicle motion.SPN 1…";
CM_ SG_ 2297455358 TrnsmssnHdrsttLp1Prssr "Oil pressure in the transmission hydrostatic loop #1 between the pump and motor.…";
CM_ SG_ 2297455358 TrnsmssnHdrsttLp2Prssr "Oil pressure in the transmission hydrostatic loop #2 between the pump and motor.…";
CM_ SG_ 2297455358 TrnsmssnIntrmdtShftSpd "Rotational velocity of the first intermediate shaft of the transmission.…";
CM_ BO_ 2297499902 "Brakes 2";
CM_ SG_ 2297499902 BrakePedalSwitch2 "Second switch signal instance which indicates that the driver operated brake foot pedal is being pressed. This parameter is functionally equivalent to SPN 597, …";
CM_ SG_ 2297499902 DmnddBrkAppltnPrssr "Gage pressure of the compressed air or fluid in the vehicle braking system that is used to apply brake shoes (or pads) against the brake drums (or discs). This …";
CM_ BO_ 2298375934 "High Resolution Wheel Speed";
CM_ SG_ 2298375934 FrontAxleLeftWheelSpeed "High resolution measurement of the speed of the left wheel on the front axle.…";
CM_ SG_ 2298375934 Frontaxlerightwheelspeed "High resolution measurement of the speed of the right wheel on the front axle.…";
CM_ SG_ 2298375934 Rearaxleleftwheelspeed "High resolution measurement of the speed of the left wheel on the rear axle.…";
CM_ SG_ 2298375934 Rearaxlerightwheelspeed "High resolution measurement of the speed of the right wheel on the rear axle.…";
CM_ BO_ 2348875518 "Torque/Speed Control 1";
CM_ SG_ 2348875518 EngineOverrideControlMode "The override control mode defines which sort of command is used:00b = Override disabled - Disable any existing control commanded by the source of this command.0…";
CM_ SG_ 2348875518 EngineRequestedSpeedSpeedLimit "Parameter provided to the engine from external sources in the torque/speed control message.  This is the engine speed which the engine is expected to operate at…";
CM_ SG_ 2348875518 EngineRequestedTorqueFractional "This parameter displays an additional torque in percent of the reference engine torque. When the MSB is set to 1, this parameter is not available.  When the MSB…";
CM_ SG_ 2348875518 EngnRqstdSpdCntrlCndtns "This mode tells the engine control system the governor characteristics that are desired during speed control.  The four characteristics defined are:00b = Transi…";
CM_ SG_ 2348875518 EngnRqstdTrqTrqLmt "Parameter provided to the engine or retarder in the torque/speed control message for controlling or limiting the output torque.Requested torque to the engine is…";
CM_ SG_ 2348875518 MessageChecksum "The message checksum is used to verify the signal path from the transmitting device to the receiving device. The message checksum is calculated using the first …";
CM_ SG_ 2348875518 MessageCounter "The message counter is used to detect situations where the transmitting ECU malfunction repeats the same frame all the time.  The receiver of the information ma…";
CM_ SG_ 2348875518 OverrideControlModePriority "This field is used as an input to the engine or retarder to determine the priority of the Override Control Mode received in the Torque/Speed Control message (se…";
CM_ SG_ 2348875518 TSC1ControlPurpose "State signal which indicates which control mode the sending device is using to generate the TSC1 command.  Note that the modes are not in prioritized order. Not…";
CM_ SG_ 2348875518 TSC1TransmissionRate "This parameter indicates the transmission rate at which the sending device will transmit the TSC1 message.  The engine shall adjust its timeout for TSC1 message…";
CM_ BO_ 2348941054 "Transmission Control 1";
CM_ SG_ 2348941054 DisengageDrivelineRequest "Command signal used to simply disengage the driveline, e.g., to prevent engine drag torque from causing high wheel slip on slippery surfaces.00b = Allow driveli…";
CM_ SG_ 2348941054 DsnggDffrntlLkRqstCntrl "Command signal used to disengage the various differential locks, e.g., to allow an undistributed individual wheel control by ABS.  The differential locks are lo…";
CM_ SG_ 2348941054 DsnggDffrntlLkRqstCntrlFrnt "Command signal used to disengage the various differential locks, e.g., to allow an undistributed individual wheel control by ABS.  The differential locks are lo…";
CM_ SG_ 2348941054 DsnggDffrntlLkRqstCntrlRr "Command signal used to disengage the various differential locks, e.g., to allow an undistributed individual wheel control by ABS.  The differential locks are lo…";
CM_ SG_ 2348941054 DsnggDffrntlLkRqstFrntAxl1 "Command signal used to disengage the various differential locks, e.g., to allow an undistributed individual wheel control by ABS.  The differential locks are lo…";
CM_ SG_ 2348941054 DsnggDffrntlLkRqstFrntAxl2 "Command signal used to disengage the various differential locks, e.g., to allow an undistributed individual wheel control by ABS.  The differential locks are lo…";
CM_ SG_ 2348941054 DsnggDffrntlLkRqstRrAxl1 "Command signal used to disengage the various differential locks, e.g., to allow an undistributed individual wheel control by ABS.  The differential locks are lo…";
CM_ SG_ 2348941054 DsnggDffrntlLkRqstRrAxl2 "Command signal used to disengage the various differential locks, e.g., to allow an undistributed individual wheel control by ABS.  The differential locks are lo…";
CM_ SG_ 2348941054 RequestedPercentClutchSlip "Parameter which represents the percent clutch slip requested by a device.…";
CM_ SG_ 2348941054 TransmissionMode1 "Indicates whether transmission mode 1 is enabled.  Modes are manufacturer specific and are not necessarily mutually exclusive.  See also SPN 2536.00b = Disable0…";
CM_ SG_ 2348941054 TransmissionMode2 "Indicates whether transmission mode 2 is enabled.  Modes are manufacturer specific and are not necessarily mutually exclusive.  See also SPN 2537.00b = Disable0…";
CM_ SG_ 2348941054 TransmissionMode3 "Indicates whether transmission mode 3 is enabled.  Modes are manufacturer specific and are not necessarily mutually exclusive.  See also SPN 2538.00b = Disable0…";
CM_ SG_ 2348941054 TransmissionMode4 "Indicates whether transmission mode 4 is enabled.  Modes are manufacturer specific and are not necessarily mutually exclusive.  See also SPN 2539.00b = Disable0…";
CM_ SG_ 2348941054 TransmissionMode5 "Indicates whether transmission mode 5 is enabled. Modes are manufacturer specific and are not necessarily mutually exclusive. See also SPN 4250.00b = Disable01b…";
CM_ SG_ 2348941054 TransmissionMode6 "Indicates whether transmission mode 6 is enabled. Modes are manufacturer specific and are not necessarily mutually exclusive. See also SPN 4251.00b = Disable01b…";
CM_ SG_ 2348941054 TransmissionMode7 "Indicates whether transmission mode 7 is enabled. Modes are manufacturer specific and are not necessarily mutually exclusive. See also SPN 4252.00b = Disable01b…";
CM_ SG_ 2348941054 TransmissionMode8 "Indicates whether transmission mode 8 is enabled. Modes are manufacturer specific and are not necessarily mutually exclusive. See also SPN 4253.00b = Disable01b…";
CM_ SG_ 2348941054 TransmissionRequestedGear "Gear requested by the operator, ABS, or engine.Negative values are reverse gears, positive values are forward gears, zero is neutral, parameter specific indicat…";
CM_ SG_ 2348941054 TransmissionRequestedLaunchGear "Initial gear for the transmission to start out in when the vehicle is launched from a standing stop, as specified by the vehicle operator or vehicle system.  Au…";
CM_ SG_ 2348941054 TrnsmssnAtNtrlMnlRtrnRqst "This parameter conveys a vehicle system desire to override the operator's current shift selector request (e.g. Drive, Reverse) and shift the transmission into N…";
CM_ SG_ 2348941054 TrnsmssnGrShftInhtRqst "Command signal to inhibit gear shifts.00b = Gear shifts are allowed  (disable function)01b = Gear shifts are inhibited  (enable function)10b = Reserved11b = Tak…";
CM_ SG_ 2348941054 TrnsmssnLdRdtnInhtRqst "Request signal to the transmission to inhibit activation of load reduction functions.Automatic transmissions may incorporate functions designed to reduce engine…";
CM_ SG_ 2348941054 TrnsmssnRvrsGrShftInhtRqst "Allows devices external to the normal transmission shift selector system to request the transmission to inhibit shifts into any Reverse gear and force the trans…";
CM_ SG_ 2348941054 TrnsmssnShftSltrDsplMdSwth "Status of the operator's switch used to 'toggle' through multiple display modes of a shift selector display.  When a shift selector display is capable of displa…";
CM_ SG_ 2348941054 TrnsmssnTrqCnvrtrLkpRqst "Command signal to override normal transmission control of the torque converter lockup clutch. This command may be used to control lockup as needed for different…";
CM_ BO_ 2349137662 "External Brake Request";
CM_ SG_ 2349137662 ExternalAccelerationDemand "Parameter provided to the brake system from external sources. This is the acceleration which the brake system is expected to realize. It is specified as an abso…";
CM_ SG_ 2349137662 XBRControlMode "The XBR Control Mode is used as an input to the brake system and defines how the external acceleration demand has to be realized.00b = Override disabled – Disab…";
CM_ SG_ 2349137662 XBREBIMode "The XBR EBI (Endurance Brake Integration) Mode is used as an input for the brake system to prescribe the use of endurance brakes like retarders or engine brakes…";
CM_ SG_ 2349137662 XBRMessageChecksum "The XBR message checksum is used to verify the signal path from the demanding device to the brake controller on electronic brake systems.  The support of this p…";
CM_ SG_ 2349137662 XBRMessageCounter "The XBR message counter is to verify the signal path from the demanding device to the brake controller on electronic brake systems..  The support of this parame…";
CM_ SG_ 2349137662 XBRPriority "The XBR Priority is used as an input to the brake system to manage the priority of overlapping external and internal requests.00b = Highest priority – used for …";
CM_ SG_ 2349137662 XBRurgency "The idea of the urgency value is to adjust the endurance brake integration behavior in the EBS system according to the traffic situation.On low urgency values (…";
CM_ BO_ 2349399806 "Auxiliary Input/Output Status 5";
CM_ SG_ 2349399806 AuxiliaryIOChannel3 "Identifies the current value of auxiliary input/output channels that are configured uniquely per application.…";
CM_ SG_ 2349399806 AuxiliaryIOChannel4 "Identifies the current value of auxiliary input/output channels that are configured uniquely per application.…";
CM_ SG_ 2349399806 AuxiliaryIOChannel5 "Identifies the current value of auxiliary input/output channels that are configured uniquely per application.…";
CM_ SG_ 2349399806 AuxiliaryIOChannel6 "Identifies the current value of auxiliary input/output channels that are configured uniquely per application.…";
CM_ BO_ 2349465342 "Static Roll Angle Sensor Information";
CM_ SG_ 2349465342 StaticRollAngle "The measured static roll angle between the vehicle y-axis and the ground plane about the X-axis.  The sign of the roll angle is determined in accordance to the …";
CM_ SG_ 2349465342 StaticRollAngleStatus "Status of the transmitted roll angle data.000b = Sensor Busy001b = Sensor OK010b = Sensor Defect011b = Sensor Reboots100b = Angle Data Invalid101b = Reserved110…";
CM_ BO_ 2349530878 "Cruise Control / Vehicle Speed 2";
CM_ SG_ 2349530878 CruiseControlDisableCommand "This parameter is used to disable cruise control from a source other than the driver controlled switch if cruise control is active.  It is also used to inhibit …";
CM_ SG_ 2349530878 CruiseControlPauseCommand "This parameter is used to temporarily disable cruise control from a source other than the driver controlled switch if cruise control is active.  If this paramet…";
CM_ SG_ 2349530878 CruiseControlResumeCommand "This parameter is used to request the cruise control to resume operation from a source other than the driver controlled switch.  Implementers may wish to restri…";
CM_ SG_ 2349530878 IdleControlEnableState "Indicates whether enabling conditions (switch position, park brake, transmission neutral status, etc.) have been met for an idle speed request. Similar to a cru…";
CM_ SG_ 2349530878 IdleControlRequestActivation "Indicates whether the idle speed request (SPN 8438) should be honored. This parameter does not inhibit or apply to Engine Operator Primary Intermediate Speed Se…";
CM_ SG_ 2349530878 IdleSpeedRequest "Requested idle speed. Allows an operator or ECU to modify the engine idle setpoint within a range supported by the engine. Requests above or below the supported…";
CM_ SG_ 2349530878 CruiseControlSetCommand "This parameter is used to set the cruise control speed from a source other than the driver controlled switch when Cruise Control Enable Switch (SPN 596) is ON a…";
CM_ SG_ 2349530878 RemoteRoadSpeedLimitRequest "Indicates a request to temporarily limit the maximum vehicle speed.  The value is sent from a body builder platform or other vehicle system.As this request may …";
CM_ BO_ 2349596414 "Advanced Emergency Braking System 2";
CM_ SG_ 2349596414 AEBS2messagechecksum "Used to check the message checksum of the transmitting (HMI) unit within the AEBS2 system.Checksum = (Byte1 + Byte2 + Byte3 + Byte4 + Byte5 + Byte6 + Byte7 + (m…";
CM_ SG_ 2349596414 AEBS2messageCounter "The message counter is increased with every transmitted AEBS2 message.  After reaching a value of Fh the next value will be 0.…";
CM_ SG_ 2349596414 DvtvtddAdvdEBSst "According to the Vienna world convention on road traffic the driver must be provided with means to deactivate an Advanced Emergency Braking System. This command…";
CM_ BO_ 2349727486 "Transmission Control 2";
CM_ SG_ 2349727486 TransmissionMode10 "Indicates whether transmission mode 10 is enabled. Modes are manufacturer specific and are not necessarily mutually exclusive. See also SPN 6568. 00b = Disable0…";
CM_ SG_ 2349727486 TransmissionMode9 "Indicates whether transmission mode 9 is enabled. Modes are manufacturer specific and are not necessarily mutually exclusive. See also SPN 6567. 00b = Disable01…";
CM_ BO_ 2350644990 "High Voltage Energy Storage 1 Control 1";
CM_ SG_ 2350644990 HVES1CellBalancingCommand "Command for the High Voltage Energy Storage 1 pack (or system) to perform cell balancing.00b = Cell Balancing not requested01b = Cell Balancing requested10b = R…";
CM_ SG_ 2350644990 HVES1EnlIntrnlChrgrCmmnd "When the HVES has an internal charger this parameter will enable it.   External chargers may use the External Energy Source Connection Demand (SPN 7890) and rel…";
CM_ SG_ 2350644990 HVES1HghVltgBsAtvIsltnTstCmmnd "Command for the High Voltage Energy Storage 1 pack (or system) to perform an active electrical isolation test on the high voltage bus.An active isolation test m…";
CM_ SG_ 2350644990 HVES1HghVltgBsCnntCmmnd "Command to connect the High Voltage Energy Storage 1 pack (or system) to the high-voltage bus.  The emergency contactor closure request may be used in situation…";
CM_ SG_ 2350644990 HVES1HghVltgBsLwSdRsstrCnntRqst "This parameter is used to request connection of the HVES1 High-Voltage bus low side resistor in order to perform an isolation test.  See also HVES1 High-Voltage…";
CM_ SG_ 2350644990 HVES1HghVltgBsPssvIsltnTstCmmnd "Command for the High Voltage Energy Storage 1 pack (or system) to perform a passive electrical isolation test on the high voltage bus.A passive isolation test u…";
CM_ SG_ 2350644990 HVES1HVtBsHSdRsstCtRqst "This parameter is used to request connection of the HVES1 High-Voltage bus high side resistor in order to perform an isolation test.  See also HVES1 High-Voltag…";
CM_ SG_ 2350644990 HVES1OperationConsent "This parameter provides an indication to the HVES1 pack (or system) that an external device is ready for HVES1 to proceed with normal operation.  In application…";
CM_ SG_ 2350644990 HVES1PowerDownCommand "Command to shut down the High Voltage Energy Storage 1 pack (or system).  A normal power-down may involve steps that take some period of time (tests, writing of…";
CM_ BO_ 2350710526 "Transmission Control 3";
CM_ SG_ 2350710526 MessageChecksum "The message checksum is used to verify the signal path from the transmitting device to the receiving device. The message checksum is calculated using the first …";
CM_ SG_ 2350710526 MessageCounter "The message counter is used to detect situations where the transmitting ECU malfunction repeats the same frame all the time.  The receiver of the information ma…";
CM_ SG_ 2350710526 TransmissionOverrideControlMode "The override control mode defines the type of control mode used to control transmission operation.00b = Override disabled - Disable any existing control command…";
CM_ SG_ 2350710526 TrnsmssnOvrrdCntrlMdPrrt "This field is used as an input to the transmission to determine the priority of the Override Control Mode received in the Torque/Speed Control message.  The def…";
CM_ SG_ 2350710526 TrnsmssnRqstdOtptShftSpd "Used to request output shaft speed of the transmission which has a output through a driveline to the wheels of a machine/vehicle.…";
CM_ SG_ 2350710526 TrnsmssnRqstdTrqTrqLmt "Requested transmission output torque measured as a percentage of Transmission Reference Torque (SPN 7778). This is the output torque at which the transmission i…";
CM_ BO_ 2350776062 "Engine Ignition Controller";
CM_ SG_ 2350776062 EngineTimingAdvance "Ignition timing as a command to the ignition control module.  Positive values command an increasingly advanced timing from TDC. The same timing applies to all c…";
CM_ BO_ 2350841598 "Alternator Control";
CM_ SG_ 2350841598 AlternatorTorqueRampTimeCommand "Sets the torque ramp rate in which the alternator can respond to a change in electrical load. 100% represents the reference engine torque (SPN 544). This value …";
CM_ SG_ 2350841598 AltrntrExttnMxmmCrrntLmt "Command sent to alternator to set the maximum excitation current of the alternator.…";
CM_ SG_ 2350841598 AltrntrStpntVltgCmmnd "Setpoint voltage command to alternator. The setpoint voltage is the point that is regulated by the alternator. This may or may not be the output of the alternat…";
CM_ SG_ 2350841598 AltrntrTrqRmpMxmmSpdCmmnd "The Alternator Torque Ramp Time Command (SPN 7591) is applied if the alternator speed is less than Alternator Torque Ramp Maximum Speed Command (SPN 7592). If t…";
CM_ BO_ 2358902526 "Joystick Lamp Command Message";
CM_ SG_ 2358902526 Joystick1Lamp10Command "Tells joystick 1 to switch on/off/blinking lamp 10.00b = Off01b = On10b = Blinking11b = Don't care / Take no action…";
CM_ SG_ 2358902526 Joystick1Lamp1Command "Tells joystick 1 to switch on/off/blinking lamp 1.00b = Off01b = On10b = Blinking11b = Don't care / Take no action…";
CM_ SG_ 2358902526 Joystick1Lamp2Command "Tells joystick 1 to switch on/off/blinking lamp 2.00b = Off01b = On10b = Blinking11b = Don't care / Take no action…";
CM_ SG_ 2358902526 Joystick1Lamp3Command "Tells joystick 1 to switch on/off/blinking lamp 3.00b = Off01b = On10b = Blinking11b = Don't care / Take no action…";
CM_ SG_ 2358902526 Joystick1Lamp4Command "Tells joystick 1 to switch on/off/blinking lamp 4.00b = Off01b = On10b = Blinking11b = Don't care / Take no action…";
CM_ SG_ 2358902526 Joystick1Lamp5Command "Tells joystick 1 to switch on/off/blinking lamp 5.00b = Off01b = On10b = Blinking11b = Don't care / Take no action…";
CM_ SG_ 2358902526 Joystick1Lamp6Command "Tells joystick 1 to switch on/off/blinking lamp 6.00b = Off01b = On10b = Blinking11b = Don't care / Take no action…";
CM_ SG_ 2358902526 Joystick1Lamp7Command "Tells joystick 1 to switch on/off/blinking lamp 7.00b = Off01b = On10b = Blinking11b = Don't care / Take no action…";
CM_ SG_ 2358902526 Joystick1Lamp8Command "Tells joystick 1 to switch on/off/blinking lamp 8.00b = Off01b = On10b = Blinking11b = Don't care / Take no action…";
CM_ SG_ 2358902526 Joystick1Lamp9Command "Tells joystick 1 to switch on/off/blinking lamp 9.00b = Off01b = On10b = Blinking11b = Don't care / Take no action…";
CM_ SG_ 2358902526 Joystick2Lamp10Command "Tells joystick 2 to switch on/off/blinking lamp 10.00b = Off01b = On10b = Blinking11b = Don't care / Take no action…";
CM_ SG_ 2358902526 Joystick2Lamp1Command "Tells joystick 2 to switch on/off/blinking lamp 1.00b = Off01b = On10b = Blinking11b = Don't care / Take no action…";
CM_ SG_ 2358902526 Joystick2Lamp2Command "Tells joystick 2 to switch on/off/blinking lamp 2.00b = Off01b = On10b = Blinking11b = Don't care / Take no action…";
CM_ SG_ 2358902526 Joystick2Lamp3Command "Tells joystick 2 to switch on/off/blinking lamp 3.00b = Off01b = On10b = Blinking11b = Don't care / Take no action…";
CM_ SG_ 2358902526 Joystick2Lamp4Command "Tells joystick 2 to switch on/off/blinking lamp 4.00b = Off01b = On10b = Blinking11b = Don't care / Take no action…";
CM_ SG_ 2358902526 Joystick2Lamp5Command "Tells joystick 2 to switch on/off/blinking lamp 5.00b = Off01b = On10b = Blinking11b = Don't care / Take no action…";
CM_ SG_ 2358902526 Joystick2Lamp6Command "Tells joystick 2 to switch on/off/blinking lamp 6.00b = Off01b = On10b = Blinking11b = Don't care / Take no action…";
CM_ SG_ 2358902526 Joystick2Lamp7Command "Tells joystick 2 to switch on/off/blinking lamp 7.00b = Off01b = On10b = Blinking11b = Don't care / Take no action…";
CM_ SG_ 2358902526 Joystick2Lamp8Command "Tells joystick 2 to switch on/off/blinking lamp 8.00b = Off01b = On10b = Blinking11b = Don't care / Take no action…";
CM_ SG_ 2358902526 Joystick2Lamp9Command "Tells joystick 2 to switch on/off/blinking lamp 9.00b = Off01b = On10b = Blinking11b = Don't care / Take no action…";
CM_ SG_ 2358902526 Joystick3Lamp10Command "Tells joystick 3 to switch on/off/blinking lamp 10.00b = Off01b = On10b = Blinking11b = Don't care / Take no action…";
CM_ SG_ 2358902526 Joystick3Lamp1Command "Tells joystick 3 to switch on/off/blinking lamp 1.00b = Off01b = On10b = Blinking11b = Don't care / Take no action…";
CM_ SG_ 2358902526 Joystick3Lamp2Command "Tells joystick 3 to switch on/off/blinking lamp 2.00b = Off01b = On10b = Blinking11b = Don't care / Take no action…";
CM_ SG_ 2358902526 Joystick3Lamp3Command "Tells joystick 3 to switch on/off/blinking lamp 3.00b = Off01b = On10b = Blinking11b = Don't care / Take no action…";
CM_ SG_ 2358902526 Joystick3Lamp4Command "Tells joystick 3 to switch on/off/blinking lamp 4.00b = Off01b = On10b = Blinking11b = Don't care / Take no action…";
CM_ SG_ 2358902526 Joystick3Lamp5Command "Tells joystick 3 to switch on/off/blinking lamp 5.00b = Off01b = On10b = Blinking11b = Don't care / Take no action…";
CM_ SG_ 2358902526 Joystick3Lamp6Command "Tells joystick 3 to switch on/off/blinking lamp 6.00b = Off01b = On10b = Blinking11b = Don't care / Take no action…";
CM_ SG_ 2358902526 Joystick3Lamp7Command "Tells joystick 3 to switch on/off/blinking lamp 7.00b = Off01b = On10b = Blinking11b = Don't care / Take no action…";
CM_ SG_ 2358902526 Joystick3Lamp8Command "Tells joystick 3 to switch on/off/blinking lamp 8.00b = Off01b = On10b = Blinking11b = Don't care / Take no action…";
CM_ SG_ 2358902526 Joystick3Lamp9Command "Tells joystick 3 to switch on/off/blinking lamp 9.00b = Off01b = On10b = Blinking11b = Don't care / Take no action…";
CM_ BO_ 2362572542 "Air Suspension Control 6";
CM_ SG_ 2362572542 LevelPresetFrontAxleLeft "Set value for nominal level 'preset level' at the left side of the front axle. This value is referred to 'Normal level 1'.  For explanations of normal level 1 s…";
CM_ SG_ 2362572542 LevelPresetFrontAxleRight "Set value for nominal level 'preset level' at the right side of the front axle. This value is referred to 'Normal level 1'.  For explanations of normal level 1 …";
CM_ SG_ 2362572542 LevelPresetRearAxleLeft "Set value for nominal level 'preset level' at the left side of the rear axle. This value is referred to 'Normal level 1'.  For explanations of normal level 1 se…";
CM_ SG_ 2362572542 LevelPresetRearAxleRight "Set value for nominal level 'preset level' at the right side of the rear axle. This value is referred to 'Normal level 1'.  For explanations of normal level 1 s…";
CM_ BO_ 2362638078 "Air Suspension Control 2";
CM_ SG_ 2362638078 AllwLvlCntrlDrngBrkngCmmnd "This parameter overides the inhibit of level control during braking.00b = Disallow level control during braking (normal operation)01b = Allow level control duri…";
CM_ SG_ 2362638078 Atmttrtnhlpldtrnsfr "This signal enables the traction help (load transfer) in case of an active ASR function00b = Disable automatic traction help 01b = Enable automatic traction hel…";
CM_ SG_ 2362638078 DamperStiffnessRequestFrontAxle "Demand value for the shock absorber control at the front axle.…";
CM_ SG_ 2362638078 DamperStiffnessRequestRearAxle "Demand value for the shock absorber control at the rear  axle.…";
CM_ SG_ 2362638078 DmprStffnssRqstLftTgAxl "Demand value for the shock absorber control at the lift or tag axle…";
CM_ SG_ 2362638078 KneelingCommandFrontAxle "Command signal to activate the kneeling functionality at the front axle of the vehicle00b = Deactivate kneeling01b = Activate kneeling10b = Reserved11b = Don't …";
CM_ SG_ 2362638078 KneelingCommandRearAxle "Command signal to activate the kneeling functionality at the rear axle of the vehicle.00b = Deactivate kneeling01b = Activate kneeling10b = Reserved11b = Don't …";
CM_ SG_ 2362638078 KneelingControlModeRequest "Command signal to select the kneeling functionality00b = Automatically actuated01b = Manually actuated10b = Reserved11b = Don't care/take no action…";
CM_ SG_ 2362638078 KneelingRequestLeftSide "Command signal to activate the kneeling functionality on the left side of the vehicle00b = No kneeling request01b = Kneeling request10b = Reserved11b = Don't ca…";
CM_ SG_ 2362638078 KneelingRequestRightSide "Command signal to activate the kneeling functionality on the right side of the vehicle00b = No kneeling request01b = Kneeling request10b = Reserved11b = Don't c…";
CM_ SG_ 2362638078 LevelControlModeRequest "Command signal to activate a level control mode0000b = Normal operation; i.e. the system performs a pure control of the vehicle height0001b = Traction help (loa…";
CM_ SG_ 2362638078 LiftAxle1PositionCommand "Signal to command the position/load condition of lift/tag axle #1.  Numbering of lift/tag axles starts at front axle.00b = Lift axle position down / tag axle la…";
CM_ SG_ 2362638078 LiftAxle2PositionCommand "Signal to command the position / load condition of lift / tag axle #2.  Numbering of lift/tag axles starts at front axle.00b = Lift axle position down / tag axl…";
CM_ SG_ 2362638078 Memorylevelrequest "Signal which indicates that the air suspension control requests a memory level or a memory level shall be stored.The storage of  the current memory level is req…";
CM_ SG_ 2362638078 NominalLevelRequestFrontAxle "Command signal to activate a level of the front axle programmed and/or memorized in the ECU   For explanations of nominal level see SPN 1734 - Nominal Level Fro…";
CM_ SG_ 2362638078 NominalLevelRequestRearAxle "Command signal to activate a level of the rear axle programmed and/or memorized in the ECU.  For explanations of nominal level see SPN 1734 - Nominal Level Fron…";
CM_ SG_ 2362638078 PrhtAtmtArSspnsnCntrl "This parameter is an internal request to the air suspension control system to prohibit automatic air suspension control.  If the request is accepted,  response …";
CM_ SG_ 2362638078 Prohibitairsuspensioncontrol "This parameter is an external request to the air suspension control system to prohibit all air suspension control.  If the request is accepted,  response intend…";
CM_ SG_ 2362638078 SpdDpndntLvlCntrlRqst "This parameter activates speed dependent level control in suspension system.00b = Deactivate01b = Activate10b = Reserved11b = Don't care/take no action…";
CM_ BO_ 2364539646 "Electronic Transmission Controller 1";
CM_ SG_ 2364539646 EngineMomentaryOverspeedEnable "Command signal used to indicate that the engine speed may be boosted up to the maximum engine overspeed value to accommodate transmission downshifts.  The maxim…";
CM_ SG_ 2364539646 MmntrEngnMxmmPwrEnl "Momentarily Requesting highest torque map from the engine control00b = not requesting maximum power available01b = momentarily requesting maximum power availabl…";
CM_ SG_ 2364539646 PercentClutchSlip "Parameter which represents the ratio of input shaft speed to current engine speed (in percent).Percent Clutch Slip = ((Engine rpm - Input shaft rpm)/(Engine rpm…";
CM_ SG_ 2364539646 ProgressiveShiftDisable "Command signal used to indicate that progressive shifting by the engine should be disallowed.00b = Progressive shift is not disabled01b = Progressive shift is d…";
CM_ SG_ 2364539646 SAddssCtDvTsssCt "The source address of the SAE J1939 device currently controlling the transmission. Its value may be the source address of the ECU transmitting the message (whic…";
CM_ SG_ 2364539646 Transmission1InputShaftSpeed "Rotational velocity of the primary shaft transferring power into the first transmission.  When a torque converter is present, it is the output of the torque con…";
CM_ SG_ 2364539646 Transmission1OutputShaftSpeed "Calculated speed of the transmission 1 output shaft.…";
CM_ SG_ 2364539646 TransmissionDrivelineEngaged "Driveline engaged indicates the transmission controlled portion of the driveline is engaged sufficiently to allow a transfer of torque through the transmission.…";
CM_ SG_ 2364539646 TransmissionShiftInProcess "Indicates that the transmission is in process of shifting from the current gear to the selected gear. This state is generally ACTIVE during the entire time that…";
CM_ SG_ 2364539646 TrnsmssnTrqCnvrtrLkpEnggd "State signal which indicates whether the torque converter lockup is engaged.00b = Torque converter lockup disengaged01b = Torque converter lockup engaged10b = E…";
CM_ SG_ 2364539646 TrnsmssnTrqCnvrtrLkpTrnstnnPrss "State signal indicating whether or not the transmission torque converter lock up clutch is transitioning between being applied and being released.  The broadcas…";
CM_ BO_ 2364539902 "Electronic Engine Controller 2";
CM_ SG_ 2364539902 AcceleratorPedal1LowIdleSwitch "Switch signal which indicates the state of the accelerator pedal 1 low idle switch.  The low idle switch is defined in SAE Recommended Practice J1843.00b = Acce…";
CM_ SG_ 2364539902 AcceleratorPedal2LowIdleSwitch "Switch signal which indicates the state of the accelerator pedal 2 low idle switch.  The low idle switch is defined in SAE J1843.00b = Accelerator pedal 2 not i…";
CM_ SG_ 2364539902 AcceleratorPedalKickdownSwitch "Switch signal which indicates whether the accelerator pedal kickdown switch is opened or closed.  The kickdown switch is defined in SAE J1843.00b = Kickdown pas…";
CM_ SG_ 2364539902 AcceleratorPedalPosition1 "This parameter is intended for the primary accelerator control in an application. SPN 91 is the calculated ratio of actual position of the operator’s [engine] s…";
CM_ SG_ 2364539902 AtlMxmmAvllEngnPrntTrq "This is the maximum amount of torque that the engine can immediately deliver as a percentage of the reference engine torque (SPN 544).  The Actual Maximum Avail…";
CM_ SG_ 2364539902 DPFThermalManagementActive "Indicates that the exhaust temperatures have been elevated for regeneration of the diesel particulate filter aftertreatment system or in preparation of regenera…";
CM_ SG_ 2364539902 EnginePercentLoadAtCurrentSpeed "The ratio of actual engine percent torque (indicated) to maximum indicated torque available at the current engine speed, clipped to zero torque during engine br…";
CM_ SG_ 2364539902 EstimatedPumpingPercentTorque "The calculated torque that indicates the estimated amount of torque loss due to the engine air handling system. The value transmitted in this parameter is inclu…";
CM_ SG_ 2364539902 MmntrEngnMxmmPwrEnlFdk "Momentarily requesting Engine Maximum Power Enable - feature support feedback00b = disabled01b = supported 10b = reserved11b = don't care…";
CM_ SG_ 2364539902 RemoteAcceleratorPedalPosition "The ratio of actual position of the remote analog engine speed/torque request input device (such as an accelerator pedal or throttle lever) to the maximum posit…";
CM_ SG_ 2364539902 RoadSpeedLimitStatus "Status (active or not active) of the system used to limit maximum vehicle velocity.00b = Active01b = Not Active10b = Error11b = Not availableNOTE - While somewh…";
CM_ SG_ 2364539902 SCRThermalManagementActive "Indicates that the exhaust temperatures have been elevated for regeneration of the SCR aftertreatment system or in preparation of regeneration of the SCR aftert…";
CM_ SG_ 2364539902 VhlAlrtnRtLmtStts "Status (active or not active) of the system used to limit maximum forward vehicle acceleration.00b = Limit not active01b = Limit active10b = Reserved11b = Not a…";
CM_ SG_ 2364539902 AcceleratorPedal2Position "The ratio of actual position of the second analog engine speed/torque request input device (such as an accelerator pedal or throttle lever) to the maximum posit…";
CM_ BO_ 2364540158 "Electronic Engine Controller 1";
CM_ SG_ 2364540158 ActualEnginePercentTorque "The calculated output torque of the engine.  The data is transmitted in indicated torque as a percent of reference engine torque (see the engine configuration m…";
CM_ SG_ 2364540158 AtlEngnPrntTrqFrtnl "This parameter displays an additional torque in percent of the reference engine torque. When the MSB is set to 1, this parameter is not available.  When the MSB…";
CM_ SG_ 2364540158 DrvrsDmndEngnPrntTrq "The requested torque output of the engine by the driver. It is based on input from the following requestors external to the powertrain: operator (via the accele…";
CM_ SG_ 2364540158 EngineSpeed "Actual engine speed which is calculated over a minimum crankshaft angle of 720 degrees divided by the number of cylinders.…";
CM_ SG_ 2364540158 EngineStarterMode "There are several phases in a starting action and different reasons why a start cannot take place.0000b = start not requested0001b = starter active but not enga…";
CM_ SG_ 2364540158 EngineTorqueMode "State signal which indicates which engine torque mode is currently generating, limiting, or controlling the torque.  Note that the modes are not in prioritized …";
CM_ SG_ 2364540158 SrAddrssfCntrllngDvfrEngnCntrl "The source address of the SAE J1939 device currently controlling the engine.  It is used to expand the torque mode parameter (see SPN 899) in cases where contro…";
CM_ SG_ 2364540158 EngineDemandPercentTorque "The requested torque output of the engine by all dynamic internal inputs, including smoke control, noise control and low and high speed governing.…";
CM_ BO_ 2364541694 "Engine Gas Flow Rate";
CM_ SG_ 2364541694 EngineIntakeAirMassFlowRate "Mass flow rate of fresh air entering the engine air intake, before any EGR mixer, if used.  Flow rate of fresh air conducted to the engine cylinders to support …";
CM_ SG_ 2364541694 EngnExhstGsRrltn1MssFlwRt "Flow rate of gas through the EGR system. Flow rate of the exhaust gas being recirculated into the combustion air.…";
CM_ SG_ 2364541694 EngnExhstGsRrltn2MssFlwRt "Flow rate of gas through the second EGR system. Flow rate of the exhaust gas being recirculated from the 2nd EGR system into combustion air.…";
CM_ BO_ 2364542206 "Electronic Transmission Controller #8";
CM_ SG_ 2364542206 TrnsmssnClthCnvrtrInptSpd "Rotational velocity of the input to a transmission's master clutch or torque converter. In most cases the rotational velocity will be the same as engine flywhee…";
CM_ SG_ 2364542206 TrnsmssnTrqCnvrtrRt "Ratio of the transmissions torque converter output torque to torque converter input torque at current speed.The ratio of 1.000 (03E8h) indicates torque converte…";
CM_ SG_ 2364542206 TransmissionShiftInhibitReason "Parameter indicates the reason that the requested transmission range shift is being prevented.In most circumstances, the “Shift Inhibited” states will be enunci…";
CM_ SG_ 2364542206 TrnsmssnTrqCnvrtrLkpInhtRsn "Parameter indicates the reason that transmission torque converter clutch lockup is being prevented.In most circumstances, the “Lockup Inhibited” states will be …";
CM_ SG_ 2364542206 TrnsmssnTrqCnvrtrLkpInhtIndtr "Parameter conveys a transmission request for the Torque Converter Lockup Inhibit Indicator to be active or inactive. The inhibit indicator can be of lamp or tex…";
CM_ BO_ 2364542462 "Land Leveling System Operational Information";
CM_ SG_ 2364542462 BladeAutoModeCommand "Allows other controllers to command to the primary control system what they think is the appropriate auto control mode to be engaged in, based on the informatio…";
CM_ SG_ 2364542462 BladeControlModeSwitch "Indicates the blade control mode switch state the user has set for the land leveling system.  The switch value directly correlates to the current switch state, …";
CM_ SG_ 2364542462 DesiredGradeOffsetSwitch "Indicates the grade offset switch state the user has set for the land leveling system.  The desired grade offset value is the vertical offset measured from a gi…";
CM_ SG_ 2364542462 LftBldCntrlMdOprtrCntrl "This parameter indicates the left blade control mode operator control state the user has set for the land leveling system.  The operator control value directly …";
CM_ SG_ 2364542462 LftDsrdBldOffstOprtrCntrl "This parameter indicates the left blade offset operator control state the user has set for the land leveling system.  The left desired blade offset value is the…";
CM_ SG_ 2364542462 RghtBldCntrlMdOprtrCntrl "This parameter indicates the right blade control mode operator control state the user has set for the land leveling system.  The operator control value directly…";
CM_ SG_ 2364542462 RghtDsrdBldOffstOprtrCntrl "This parameter indicates the right blade offset operator control state the user has set for the land leveling system.  The right desired blade offset value is t…";
CM_ SG_ 2364542462 SdshftBldCntrlMdOprtrCntrl "This parameter indicates the side-shift offset operator control state the user has set for the land leveling system. When an implement moves in a side-shift dir…";
CM_ SG_ 2364542462 SdshftDsrdBldOffstOprtrCntrl "This parameter indicates the side-shift blade control mode operator control state the user has set for the land leveling system.  When an implement moves in a s…";
CM_ SG_ 2364542462 StElvtnSnsr1RfrnElvtn "Command from a display or other external device (i.e. remote switch) to the land leveling system controller instructing the controller to set the reference elva…";
CM_ SG_ 2364542462 StElvtnSnsr2RfrnElvtn "Command from a display or other external device (i.e. remote switch) to the land leveling system controller instructing the controller to set the reference elva…";
CM_ BO_ 2364543998 "Slope Sensor Information";
CM_ SG_ 2364543998 PitchandRollCompensated "Compensated mode for the pitch and roll measurements.  Compensation is the use of multiple sensors together to enhance the output of pitch and roll measurements…";
CM_ SG_ 2364543998 PitchAngle "The angle between the vehicle x-axis and the ground plane (i.e. rotation about the vehicle Y-axis).  The pitch angle for an angle of ascent is reported with a p…";
CM_ SG_ 2364543998 PitchAngleFigureofMerit "Figure of merit for pitch angle measurement.00b = Pitch angle fully functional.  Data is within sensor specification. 01b = Pitch angle degraded.  Data is suspe…";
CM_ SG_ 2364543998 PitchRate "Pitch rate is the rate-of-change of the pitch angle over time, where the pitch angle vector is in the direction of travel of the vehicle. The pitch rate for inc…";
CM_ SG_ 2364543998 PitchRateFigureofMerit "Figure of merit for the pitch rate measurement.00b = Pitch rate fully functional.  Data is within sensor specification.   01b = Pitch rate degraded.  Data is su…";
CM_ SG_ 2364543998 RollandPitchMeasurementLatency "The estimated measurement latency of the measurement.  NOTE: This is only the sensor latency and does not include any additional latencies that might exist beca…";
CM_ SG_ 2364543998 RollAngle "The angle between the vehicle y-axis and the ground plane (i.e. rotation about the X-axis).  The roll angle for a roll to the right is reported with a positive …";
CM_ SG_ 2364543998 RollAngleFigureofMerit "Figure of merit for roll angle measurement.00b = Roll angle fully functional.  Data is within sensor specification.   01b = Roll angle degraded.  Data is suspec…";
CM_ BO_ 2364544254 "Blade Information";
CM_ SG_ 2364544254 BladeRotationAngle "The blade rotation angle measurement around the yaw (z-axis).  The Blade Rotation Angle is defined to be the angle from the null position on the machine.  The n…";
CM_ SG_ 2364544254 BladeRotationAngleFigureofMerit "Figure of merit for blade rotation measurement.Bits00b = Blade Rotation Angle fully functional.  Data is within sensor specification.   01b = Blade Rotation Ang…";
CM_ SG_ 2364544254 RelativeBladeHeight "The measured vertical distance from a fixed location on the machine blade to a ground-based reference (i.e. relative height).  Examples of a ground based refere…";
CM_ SG_ 2364544254 RltvBldHghtFgrfMrt "Figure of merit for blade height measurement.Bits00b = Relative Blade Height fully functional.  Data is within sensor specification.   01b = Relative Blade Heig…";
CM_ SG_ 2364544254 RtvBdHtdBdRttAMstLt "The estimated measurement latency of the measurement.NOTE: This is only the sensor latency and does not include any additional latencies that might exist becaus…";
CM_ BO_ 2364544510 "Requested Generator Total AC Reactive Power";
CM_ SG_ 2364544510 RqstdGnrtrOvrllPwrFtr "The requested average power factor of the generator.…";
CM_ SG_ 2364544510 RqstdGnrtrOvrllPwrFtrLggng "The requested lead/lag status for the generator average AC power factor00b = Leading01b = Lagging10b = Reserved11b = Not available or Not installed…";
CM_ SG_ 2364544510 RqstdGnrtrTtlACRtvPwr "The total reactive power requested to be delivered by the generator…";
CM_ BO_ 2364544766 "Cylinder Combustion Status";
CM_ SG_ 2364544766 EngineCylinder1CombustionStatus "This parameter is used to indicate state of combustion in engine cylinder #100b = No combustion01b = Combustion exists10b = Error11b = Not available…";
CM_ SG_ 2364544766 EngineCylinder2CombustionStatus "This parameter is used to indicate state of combustion in engine cylinder #200b = No combustion01b = Combustion exists10b = Error11b = Not available…";
CM_ SG_ 2364544766 EngineCylinder3CombustionStatus "This parameter is used to indicate state of combustion in engine cylinder #300b = No combustion01b = Combustion exists10b = Error11b = Not available…";
CM_ SG_ 2364544766 EngineCylinder4CombustionStatus "This parameter is used to indicate state of combustion in engine cylinder #400b = No combustion01b = Combustion exists10b = Error11b = Not available…";
CM_ SG_ 2364544766 EngineCylinder5CombustionStatus "This parameter is used to indicate state of combustion in engine cylinder #500b = No combustion01b = Combustion exists10b = Error11b = Not available…";
CM_ SG_ 2364544766 EngineCylinder6CombustionStatus "This parameter is used to indicate state of combustion in engine cylinder #600b = No combustion01b = Combustion exists10b = Error11b = Not available…";
CM_ SG_ 2364544766 EngineCylinder7CombustionStatus "This parameter is used to indicate state of combustion in engine cylinder #700b = No combustion01b = Combustion exists10b = Error11b = Not available…";
CM_ SG_ 2364544766 EngineCylinder8CombustionStatus "This parameter is used to indicate state of combustion in engine cylinder #800b = No combustion01b = Combustion exists10b = Error11b = Not available…";
CM_ SG_ 2364544766 EngineCylinder9CombustionStatus "This parameter is used to indicate state of combustion in engine cylinder #900b = No combustion01b = Combustion exists10b = Error11b = Not available…";
CM_ SG_ 2364544766 EngnClndr10CmstnStts "This parameter is used to indicate state of combustion in engine cylinder #1000b = No combustion01b = Combustion exists10b = Error11b = Not available…";
CM_ SG_ 2364544766 EngnClndr11CmstnStts "This parameter is used to indicate state of combustion in engine cylinder #1100b = No combustion01b = Combustion exists10b = Error11b = Not available…";
CM_ SG_ 2364544766 EngnClndr12CmstnStts "This parameter is used to indicate state of combustion in engine cylinder #1200b = No combustion01b = Combustion exists10b = Error11b = Not available…";
CM_ SG_ 2364544766 EngnClndr13CmstnStts "This parameter is used to indicate state of combustion in engine cylinder #1300b = No combustion01b = Combustion exists10b = Error11b = Not available…";
CM_ SG_ 2364544766 EngnClndr14CmstnStts "This parameter is used to indicate state of combustion in engine cylinder #1400b = No combustion01b = Combustion exists10b = Error11b = Not available…";
CM_ SG_ 2364544766 EngnClndr15CmstnStts "This parameter is used to indicate state of combustion in engine cylinder #1500b = No combustion01b = Combustion exists10b = Error11b = Not available…";
CM_ SG_ 2364544766 EngnClndr16CmstnStts "This parameter is used to indicate state of combustion in engine cylinder #1600b = No combustion01b = Combustion exists10b = Error11b = Not available…";
CM_ SG_ 2364544766 EngnClndr17CmstnStts "This parameter is used to indicate state of combustion in engine cylinder #1700b = No combustion01b = Combustion exists10b = Error11b = Not available…";
CM_ SG_ 2364544766 EngnClndr18CmstnStts "This parameter is used to indicate state of combustion in engine cylinder #1800b = No combustion01b = Combustion exists10b = Error11b = Not available…";
CM_ SG_ 2364544766 EngnClndr19CmstnStts "This parameter is used to indicate state of combustion in engine cylinder #1900b = No combustion01b = Combustion exists10b = Error11b = Not available…";
CM_ SG_ 2364544766 EngnClndr20CmstnStts "This parameter is used to indicate state of combustion in engine cylinder #2000b = No combustion01b = Combustion exists10b = Error11b = Not available…";
CM_ SG_ 2364544766 EngnClndr21CmstnStts "This parameter is used to indicate state of combustion in engine cylinder #2100b = No combustion01b = Combustion exists10b = Error11b = Not available…";
CM_ SG_ 2364544766 EngnClndr22CmstnStts "This parameter is used to indicate state of combustion in engine cylinder #2200b = No combustion01b = Combustion exists10b = Error11b = Not available…";
CM_ SG_ 2364544766 EngnClndr23CmstnStts "This parameter is used to indicate state of combustion in engine cylinder #2300b = No combustion01b = Combustion exists10b = Error11b = Not available…";
CM_ SG_ 2364544766 EngnClndr24CmstnStts "This parameter is used to indicate state of combustion in engine cylinder #2400b = No combustion01b = Combustion exists10b = Error11b = Not available…";
CM_ BO_ 2364545022 "Engine Knock Level #1";
CM_ SG_ 2364545022 EngineCylinder1KnockLevel "Used to indicate the level of knock for engine cylinder 1. The level of knock is reported using a relative scale where 0% is least level of knock, and increasin…";
CM_ SG_ 2364545022 EngineCylinder2KnockLevel "Used to indicate the level of knock for engine cylinder 2. The level of knock is reported using a relative scale where 0% is least level of knock, and increasin…";
CM_ SG_ 2364545022 EngineCylinder3KnockLevel "Used to indicate the level of knock for engine cylinder 3. The level of knock is reported using a relative scale where 0% is least level of knock, and increasin…";
CM_ SG_ 2364545022 EngineCylinder4KnockLevel "Used to indicate the level of knock for engine cylinder 4. The level of knock is reported using a relative scale where 0% is least level of knock, and increasin…";
CM_ SG_ 2364545022 EngineCylinder5KnockLevel "Used to indicate the level of knock for engine cylinder 5. The level of knock is reported using a relative scale where 0% is least level of knock, and increasin…";
CM_ SG_ 2364545022 EngineCylinder6KnockLevel "Used to indicate the level of knock for engine cylinder 6. The level of knock is reported using a relative scale where 0% is least level of knock, and increasin…";
CM_ SG_ 2364545022 EngineCylinder7KnockLevel "Used to indicate the level of knock for engine cylinder 7. The level of knock is reported using a relative scale where 0% is least level of knock, and increasin…";
CM_ SG_ 2364545022 EngineCylinder8KnockLevel "Used to indicate the level of knock for engine cylinder 8. The level of knock is reported using a relative scale where 0% is least level of knock, and increasin…";
CM_ BO_ 2364545278 "Engine Knock Level #2";
CM_ SG_ 2364545278 EngineCylinder10KnockLevel "Used to indicate the level of knock for engine cylinder 10. The level of knock is reported using a relative scale where 0% is least level of knock, and increasi…";
CM_ SG_ 2364545278 EngineCylinder11KnockLevel "Used to indicate the level of knock for engine cylinder 11. The level of knock is reported using a relative scale where 0% is least level of knock, and increasi…";
CM_ SG_ 2364545278 EngineCylinder12KnockLevel "Used to indicate the level of knock for engine cylinder 12. The level of knock is reported using a relative scale where 0% is least level of knock, and increasi…";
CM_ SG_ 2364545278 EngineCylinder13KnockLevel "Used to indicate the level of knock for engine cylinder 13. The level of knock is reported using a relative scale where 0% is least level of knock, and increasi…";
CM_ SG_ 2364545278 EngineCylinder14KnockLevel "Used to indicate the level of knock for engine cylinder 14. The level of knock is reported using a relative scale where 0% is least level of knock, and increasi…";
CM_ SG_ 2364545278 EngineCylinder15KnockLevel "Used to indicate the level of knock for engine cylinder 15. The level of knock is reported using a relative scale where 0% is least level of knock, and increasi…";
CM_ SG_ 2364545278 EngineCylinder16KnockLevel "Used to indicate the level of knock for engine cylinder 16. The level of knock is reported using a relative scale where 0% is least level of knock, and increasi…";
CM_ SG_ 2364545278 EngineCylinder9KnockLevel "Used to indicate the level of knock for engine cylinder 9. The level of knock is reported using a relative scale where 0% is least level of knock, and increasin…";
CM_ BO_ 2364545534 "Engine Knock Level #3";
CM_ SG_ 2364545534 EngineCylinder17KnockLevel "Used to indicate the level of knock for engine cylinder 17. The level of knock is reported using a relative scale where 0% is least level of knock, and increasi…";
CM_ SG_ 2364545534 EngineCylinder18KnockLevel "Used to indicate the level of knock for engine cylinder 18. The level of knock is reported using a relative scale where 0% is least level of knock, and increasi…";
CM_ SG_ 2364545534 EngineCylinder19KnockLevel "Used to indicate the level of knock for engine cylinder 19. The level of knock is reported using a relative scale where 0% is least level of knock, and increasi…";
CM_ SG_ 2364545534 EngineCylinder20KnockLevel "Used to indicate the level of knock for engine cylinder 20. The level of knock is reported using a relative scale where 0% is least level of knock, and increasi…";
CM_ SG_ 2364545534 EngineCylinder21KnockLevel "Used to indicate the level of knock for engine cylinder 21. The level of knock is reported using a relative scale where 0% is least level of knock, and increasi…";
CM_ SG_ 2364545534 EngineCylinder22KnockLevel "Used to indicate the level of knock for engine cylinder 22. The level of knock is reported using a relative scale where 0% is least level of knock, and increasi…";
CM_ SG_ 2364545534 EngineCylinder23KnockLevel "Used to indicate the level of knock for engine cylinder 23. The level of knock is reported using a relative scale where 0% is least level of knock, and increasi…";
CM_ SG_ 2364545534 EngineCylinder24KnockLevel "Used to indicate the level of knock for engine cylinder 24. The level of knock is reported using a relative scale where 0% is least level of knock, and increasi…";
CM_ BO_ 2364546302 "Requested Generator Average Basic AC Quantities";
CM_ SG_ 2364546302 RqstdGnrtrAvrgLnLnACRMSVltg "The requested average AC RMS voltage to be delivered by the generator.…";
CM_ BO_ 2364546814 "Generator Control 2";
CM_ SG_ 2364546814 EngineLoadSetpointRequest "Setpoint request (in kW) sent to the engine by a genset control system.…";
CM_ SG_ 2364546814 EngineSelfInducedDerateInhibit "Parameter to indicate if the genset control system allows the Engine Control Module to impose its own induced derate.00b = Engine is allowed to impose a self-in…";
CM_ SG_ 2364546814 GeneratorGoverningBias "Control signal used to govern the genset's speed or load (depending on isochronous or utility parallel operation, respectively)NOTE:  If this method of engine c…";
CM_ BO_ 2364548094 "Aftertreatment 1 SCR Dosing System Information 1";
CM_ SG_ 2364548094 Aftertreatment1SCRSystem1State "Actual state of SCR system0000b = Dormant (sleep mode)0001b = Preparing dosing readiness (wake up; prepare to operate; wait for start)0010b = Normal dosing oper…";
CM_ SG_ 2364548094 Aftertreatment1SCRSystem2State "Actual state of SCR system 20000b = Dormant (sleep mode)0001b = Preparing dosing readiness (wake up; prepare to operate; wait for start)0010b = Normal dosing op…";
CM_ SG_ 2364548094 Atttt1DsExstFdAtDsQtt "Actual reducing agent quantity of SCR-system…";
CM_ SG_ 2364548094 Atttt1DsExstFdAtDsQttHR "Actual dosing quantity of diesel exhaust fluid. See SPN 4331 if high range measurement is not needed.…";
CM_ SG_ 2364548094 Atttt1DsExstFdAtQttItt "The SCR requested diesel exhaust fluid integrator total quantity for aftertreatment system 1 (exhaust bank 1).…";
CM_ SG_ 2364548094 Atttt1DsExstFdDs1AstPss "The absolute pressure (measured closest to dosing valve) of the first or only DEF dosing unit for aftertreatment system 1 (exhaust bank 1).…";
CM_ BO_ 2364548350 "Aftertreatment 1 SCR Dosing System Requests 1";
CM_ SG_ 2364548350 Aftrtrtmnt1SCRSstmRqstdStt "Requested state of SCR system for aftertreatment system 1 (exhaust bank 1).0000b = Dormant (sleep mode) 0001b = Preparing dosing readiness (wake up; prepare to …";
CM_ SG_ 2364548350 Atttt1DsExstFdDsRqstdQtt "Actual requested dosing quantity of diesel exhaust fluid.…";
CM_ SG_ 2364548350 Atttt1DsExstFdDsRqstdQttHR "Requested dosing quantity of diesel exhaust fluid. This SPN is a high range measurement. See SPN 4348 if high range is not needed.…";
CM_ SG_ 2364548350 Atttt1DsExstFdDsTstItPssStts "After a request to permit the DEF dosing test injection has been indicated, this permission status is expected by the DEF control unit for aftertreatment system…";
CM_ SG_ 2364548350 Atttt1DsExstFdHdStssCPssStts "After a request to permit the DEF hydraulic stiffness check has been indicated, this permission status is expected by the DEF control unit for aftertreatment sy…";
CM_ SG_ 2364548350 Atttt1DsExstFdRqstdQttItt "Represents the command for the diesel exhaust fluid quantity integrator in the dosing control unit.  See SPN 7783 for alternate resolution.…";
CM_ BO_ 2364548606 "Aftertreatment 1 SCR Ammonia Information";
CM_ SG_ 2364548606 Aftertreatment1OutletNH3 "The amount of NH3 in the exhaust exiting the aftertreatment system measured by a NH3 sensor at the aftertreatment outlet, represented in NH3 molecule parts per …";
CM_ SG_ 2364548606 Aftrtrtmnt1OtltNH3GsSnsrtTmprtr "Indicates that the heater element of the aftertreatment outlet NH3 gas sensor is within the manufacturer's specified range for accurate measurements in exhaust …";
CM_ SG_ 2364548606 Aftrtrtmnt1OtltNH3RdngStl "Indicates that the NH3 reading of the aftertreatment outlet NH3 sensor is stable as determined by the manufacturer's control software in exhaust bank 1.00b = Re…";
CM_ SG_ 2364548606 Aftrtrtmnt1OtltNH3SnsrPrlmnrFMI "Used to identify the applicable J1939-73 FMI detected in the aftertreatment outlet NH3 sensor by the manufacturer’s sensor control software in exhaust bank 1. I…";
CM_ SG_ 2364548606 Atttt1OttNH3GsSsHtCt "Indicates the heater status in the warm-up process. Upon receiving a power-up command, the NH3 gas sensor ramps up according to a manufacturer defined profile. …";
CM_ SG_ 2364548606 Atttt1OttNH3GsSsHtPFMI "Used to identify the applicable J1939-73 FMI detected in the heater of the outlet NH3 exhaust gas sensor by the manufacturer’s sensor control software in exhaus…";
CM_ SG_ 2364548606 Atttt1OttNH3GsSsPwIR "Indicates that the power supplied to the aftertreatment outlet NH3 gas sensor is within the manufacturer's specification in exhaust bank 1.00b = Power is not in…";
CM_ BO_ 2364548862 "Aftertreatment 2 SCR Dosing System Information 1";
CM_ SG_ 2364548862 Aftertreatment2SCRSystem1State "Actual state of SCR system 1.0000b = Dormant (sleep mode)0001b = Preparing dosing readiness (wake up; prepare to operate; wait for start)0010b = Normal dosing o…";
CM_ SG_ 2364548862 Aftertreatment2SCRSystem2State "Actual state of SCR system 20000b = Dormant (sleep mode)0001b = Preparing dosing readiness (wake up; prepare to operate; wait for start)0010b = Normal dosing op…";
CM_ SG_ 2364548862 Atttt2DsExstFdAtDsQtt "Actual reducing agent quantity of SCR system.…";
CM_ SG_ 2364548862 Atttt2DsExstFdAtDsQttHR "Actual dosing quantity of diesel exhaust fluid. See SPN 4384 if high range measurement is not needed.…";
CM_ SG_ 2364548862 Atttt2DsExstFdAtQttItt "The SCR requested diesel exhaust fluid integrator total quantity for aftertreatment system 2 (exhaust bank 2).…";
CM_ SG_ 2364548862 Atttt2DsExstFdDs1AstPss "The absolute pressure (measured closest to dosing valve) of the first or only DEF doser for aftertreatment system 2 (exhaust bank 2).…";
CM_ BO_ 2364549118 "Aftertreatment 2 SCR Dosing System Requests 1";
CM_ SG_ 2364549118 Aftrtrtmnt2SCRSstmRqstdStt "Requested state of SCR system for aftertreatment system 2 (exhaust bank 2).0000b = Dormant (sleep mode) 0001b = Preparing dosing readiness (wake up; prepare to …";
CM_ SG_ 2364549118 Atttt2DsExstFdDsRqstdQtt "Actual requested dosing quantity of diesel exhaust fluid.…";
CM_ SG_ 2364549118 Atttt2DsExstFdDsRqstdQttHR "Requested dosing quantity of diesel exhaust fluid. This SPN is a high range measurement. See SPN 4401 if high range is not needed.…";
CM_ SG_ 2364549118 Atttt2DsExstFdDsTstItPssStts "After a request to permit the DEF dosing test injection has been indicated, this permission status is expected by the DEF control unit for aftertreatment system…";
CM_ SG_ 2364549118 Atttt2DsExstFdHdStssCPssStts "After a request to permit the DEF hydraulic stiffness check has been indicated, this permission status is expected by the DEF control unit for aftertreatment sy…";
CM_ SG_ 2364549118 Atttt2DsExstFdPpHtCd "Command for the Aftertreatment 2 Diesel Exhaust Fluid Pump Heater.  A value of 0% means no heating commanded, a value of 100% means full heating commanded.…";
CM_ SG_ 2364549118 Atttt2DsExstFdRqstdQttItt "Represents the command for the diesel exhaust fluid quantity integrator in the dosing control unit. See SPN 7784 for alternate resolution.…";
CM_ BO_ 2364549374 "Aftertreatment 2 SCR Ammonia Information";
CM_ SG_ 2364549374 Aftertreatment2OutletNH3 "The amount of NH3 in the exhaust exiting the aftertreatment system measured by a NH3 sensor at the aftertreatment outlet, represented in NH3 molecule parts per …";
CM_ SG_ 2364549374 Aftrtrtmnt2OtltNH3GsSnsrtTmprtr "Indicates that the heater element of the aftertreatment outlet NH3 gas sensor is within the manufacturer's specified range for accurate measurements in exhaust …";
CM_ SG_ 2364549374 Aftrtrtmnt2OtltNH3RdngStl "Indicates that the NH3 reading of the aftertreatment outlet NH3 sensor is stable as determined by the manufacturer's control software in exhaust bank 2.00b = Re…";
CM_ SG_ 2364549374 Aftrtrtmnt2OtltNH3SnsrPrlmnrFMI "Used to identify the applicable J1939-73 FMI detected in the aftertreatment outlet NH3 sensor by the manufacturer’s sensor control software in exhaust bank 2. I…";
CM_ SG_ 2364549374 Atttt2OttNH3GsSsHtCt "Indicates the heater status in the warm-up process. Upon receiving a power-up command, the NH3 gas sensor ramps up according to a manufacturer defined profile. …";
CM_ SG_ 2364549374 Atttt2OttNH3GsSsHtPFMI "Used to identify the applicable J1939-73 FMI detected in the heater of the outlet NH3 exhaust gas sensor by the manufacturer’s sensor control software in exhaus…";
CM_ SG_ 2364549374 Atttt2OttNH3GsSsPwIR "Indicates that the power supplied to the aftertreatment outlet NH3 gas sensor is within the manufacturer's specification in exhaust bank 2.00b = Heater element …";
CM_ BO_ 2364549630 "Slope Sensor Information 2";
CM_ SG_ 2364549630 PitchAngleExtendedRange "The angle between the vehicle x-axis and the ground plane (i.e. rotation about the vehicle Y-axis).  The pitch angle for an angle of ascent is reported with a p…";
CM_ SG_ 2364549630 PthAnglCmpnstnExtnddRng "Compensated mode for the pitch measurement.  Compensation is the use of multiple sensors together to enhance the output of the pitch measurement.00b = On01b = O…";
CM_ SG_ 2364549630 PthAnglFgrfMrtExtnddRng "Figure of merit for pitch angle measurement.00b = Pitch angle fully functional. Data is within sensor specification.01b = Pitch angle degraded. Data is suspect …";
CM_ SG_ 2364549630 RllAnglCmpnstnExtnddRng "Compensated mode for the roll angle measurement.  Compensation is the use of multiple sensors together to enhance the output of the roll angle measurement.00b =…";
CM_ SG_ 2364549630 RllAnglFgrfMrtExtnddRng "Figure of merit for roll angle measurement.00b = Roll angle fully functional. Data is within sensor specification.01b = Roll angle degraded. Data is suspect due…";
CM_ SG_ 2364549630 RllndPthMsrmntLtnExtnddRng "Time between start of sensor processing and CAN transmission…";
CM_ SG_ 2364549630 RollAngleExtendedRange "The angle between the vehicle y-axis and the ground plane (i.e. rotation about the X-axis).  The roll angle for a roll to the right is reported with a positive …";
CM_ BO_ 2364549886 "Angular Rate Information";
CM_ SG_ 2364549886 AngularRateMeasurementLatency "The estimated measurement latency of the measurement.NOTE: This is only the sensor latency and does not include any additional latencies that might exist becaus…";
CM_ SG_ 2364549886 PitchRateExtendedRange "Pitch rate is the rate-of-change of the pitch angle over time, where the pitch angle vector is in the direction of travel of the vehicle. The pitch rate for inc…";
CM_ SG_ 2364549886 PthRtFgrfMrtExtnddRng "Figure of merit for pitch rate measurement.00b = Pitch rate fully functional. Data is within sensor specification.01b = Pitch rate degraded. Data is suspect due…";
CM_ SG_ 2364549886 RllRtFgrfMrtExtnddRng "Figure of merit for roll rate measurement.00b = Roll rate fully functional. Data is within sensor specification.01b = Roll rate degraded. Data is suspect due to…";
CM_ SG_ 2364549886 RollRateExtendedRange "Roll rate is the rate-of-change of the roll angle over time.  The roll rate for increasing roll to the right is reported with a positive value. Roll angle is th…";
CM_ SG_ 2364549886 YawRateExtendedRange "Yaw rate is the rate-of-change of the yaw angle over time.  A positive yaw rate signal results when the object turns clockwise.  This parameter is defined accor…";
CM_ SG_ 2364549886 YwRtFgrfMrtExtnddRng "Figure of merit for yaw angle measurement.00b = Yaw rate fully functional. Data is within sensor specification.01b = Yaw rate degraded. Data is suspect due to e…";
CM_ BO_ 2364551166 "Advanced Emergency Braking System 1";
CM_ SG_ 2364551166 Bndffprltfrlvntjt "Probabilty if monitored relevant object might start a turning maneuver, which could clear the travelling path of the host vehicle.000b = no indication for a ben…";
CM_ SG_ 2364551166 Collisionwarninglevel "To implement different HMI (human machine interface) concepts, e.g. visual only, visual/audible, different warning tones etc., the AEBS provides different level…";
CM_ SG_ 2364551166 Rlvntjtdttdfrdvndmrgnrkngsstm "Indication if the advanced emergency braking system (AEBS) is monitoring a relevant object000b = No relevant object monitored001b = Relevant object is being mon…";
CM_ SG_ 2364551166 Tmtllsnwthrlvntjt "The time to collision is the duration after which the predicted travelling paths of host vehicle and relevant object lead to a distance of 0m between both.Note:…";
CM_ SG_ 2364551166 FwdCsAdvdEBSstStt "Current operational state of forward collision advanced emergency braking system (AEBS)0000b = system is not ready (initialization not finished)0001b = system i…";
CM_ SG_ 2364551166 RdDprtrAdvndEmrgnBrkngSstmStt "Current operational state of road departure advanced emergency braking system (AEBS)0000b = system is not ready (initialization not finished)0001b = system is t…";
CM_ BO_ 2364551422 "Wireless Status";
CM_ SG_ 2364551422 TransmitterCommandState "The command contained in the signal received by the wireless transceiver from an off-board transmitter.0000b = Stop0001b = Clear0010b = Field Test0011b = Transm…";
CM_ SG_ 2364551422 TransmitterID1 "The ID of the off-board transmitter that sent the incoming message received by the wireless transceiver.…";
CM_ SG_ 2364551422 WirelessRollingMessageCounter "A counter incremented with each instance of the Wireless Status message. The counter shall increment from 0 to 64255, rolling over to 0 on the next increment af…";
CM_ SG_ 2364551422 WirelessSignalStrength1 "The absolute received signal strength of the signal received from the off-board transmitter. The signal strength is reported as a Received Signal Strength Indic…";
CM_ BO_ 2364552958 "High Voltage Energy Storage 1 Status 2";
CM_ SG_ 2364552958 HVES1ChrgPwrLmtDtBttrCrrnt "Indicates whether or not HVES1 charge power is being limited due to battery current.00b = No power limit for this reason01b = Power limited for this reason10b =…";
CM_ SG_ 2364552958 HVES1ChrgPwrLmtDtBttrDgnstCndtn "Indicates whether or not HVES1 charge power is being limited due to a battery diagnostic condition.00b = No power limit for this reason01b = Power limited for t…";
CM_ SG_ 2364552958 HVES1ChrgPwrLmtDtBttrrCllVltg "Indicates whether or not HVES1 charge power is being limited due to a battery or cell voltage level.00b = No power limit for this reason01b = Power limited for …";
CM_ SG_ 2364552958 HVES1ChrgPwrLmtDtBttrTmprtr "Indicates whether or not HVES1 charge power is being limited due to battery temperature.00b = No power limit for this reason01b = Power limited for this reason1…";
CM_ SG_ 2364552958 HVES1ChrgPwrLmtDtnUndfndCs "Indicates whether or not HVES1 charge power is being limited due to an undefined cause.00b = No power limit for this reason01b = Power limited for this reason10…";
CM_ SG_ 2364552958 HVES1ChrgPwrLmtDtSttfChrg "Indicates whether or not HVES1 charge power is being limited due to state of charge.00b = No power limit for this reason01b = Power limited for this reason10b =…";
CM_ SG_ 2364552958 HVES1DshrgPwrLmtDtBttrCrrnt "Indicates whether or not HVES1 discharge power is being limited due to battery current.00b = No power limit for this reason01b = Power limited for this reason10…";
CM_ SG_ 2364552958 HVES1DshrgPwrLmtDtBttrrCllVltg "Indicates whether or not HVES1 discharge power is being limited due to a battery or cell voltage level.00b = No power limit for this reason01b = Power limited f…";
CM_ SG_ 2364552958 HVES1DshrgPwrLmtDtBttrTmprtr "Indicates whether or not HVES1 discharge power is being limited due to battery temperature.00b = No power limit for this reason01b = Power limited for this reas…";
CM_ SG_ 2364552958 HVES1DshrgPwrLmtDtnUndfndCs "Indicates whether or not HVES1 discharge power is being limited due to an undefined cause.00b = No power limit for this reason01b = Power limited for this reaso…";
CM_ SG_ 2364552958 HVES1DshrgPwrLmtDtSttfChrg "Indicates whether or not HVES1 discharge power is being limited due to state of charge.00b = No power limit for this reason01b = Power limited for this reason10…";
CM_ SG_ 2364552958 HVES1DsPwLtDtBttDstCdt "Indicates whether or not HVES1 discharge power is being limited due to a battery diagnostic condition.00b = No power limit for this reason01b = Power limited fo…";
CM_ BO_ 2364553214 "Engine Turbocharger Blowoff Actuator 1";
CM_ SG_ 2364553214 EngnTrhrgrCmprssrBlwffAttr1Pstn "Actual position of the turbocharger compressor blowoff actuator, where 0% represents fully closed and 100% represents fully open.…";
CM_ SG_ 2364553214 ETCpssBwAtt1DsdPst "The requested position of the Engine Turbocharger Compressor Blowoff actuator by the engine ECU, where 0% represents bypass fully closed and 100% represents ful…";
CM_ SG_ 2364553214 ETCpssBwAtt1OptStts "Used to identify the status of Engine Turbocharger Compressor Blowoff Actuator 1.0000b = Normal0001b = Alarm (fully operational but needs service)0010b = Alarm …";
CM_ SG_ 2364553214 ETCpssBwAtt1PFMI "Used to identify the applicable J1939-73 FMI detected in the Engine Turbocharger Blowoff Actuator 1 by the manufacturer's software.  When there are multiple fai…";
CM_ SG_ 2364553214 ETCpssBwAtt1Tpt "Temperature of the Engine Turbocharger Compressor Bypass Actuator 1 drive circuitry. Temperature excursions may affect the torque output.…";
CM_ SG_ 2364553214 ETCpssBwAtt1TptStts "Used to identify the status of the Engine Turbocharger Compresssor Blowoff Actuator 1 drive circuitry temperature. Temperature excursions may affect the torque …";
CM_ BO_ 2364553470 "Engine Torque / Fuel Request";
CM_ SG_ 2364553470 EngineCylinderTorque "Calculated engine torque output per cylinder.…";
CM_ SG_ 2364553470 EngineDualFuelModeCommand "Request to enable dual fuel mode.00b = De-activate dual fuel mode01b = Activate dual fuel mode10b = Reserved11b = Not available…";
CM_ SG_ 2364553470 EngnClndrDslMssFlwRtCmmnd "Commanded Mass Flow rate of diesel fuel delivered to the engine normalized per cylinder.…";
CM_ SG_ 2364553470 EngnClndrGsMssFlwRtCmmnd "Commanded Mass Flow rate of gaseous fuel delivered to the engine normalized per cylinder.…";
CM_ SG_ 2364553470 EngnGsSstttnFlPrntgCmmnd "Percentage of Gaseous fuel used, in terms of % mass of fuel. 0% means no Gaseous fuel used and 100 % means completely gaseous fuel is used.Gas substitution is t…";
CM_ BO_ 2364553726 "Engine Air System Information";
CM_ SG_ 2364553726 EngineDesiredAirFuelRatio "Reports the desired Air Fuel ratio for the engine.Air Fuel Ratio specifies the amount of air required to completely burn one unit of fuel in the engine to meet …";
CM_ SG_ 2364553726 EngnFlSstm1TtlIntkMssArFlwRt "Mass Flow rate of air entering the engine (or the first fuel system on a configuration with more than 1 fuel system). This also includes the amount of exhaust g…";
CM_ SG_ 2364553726 EngnFlSstm2TtlIntkMssArFlwRt "Mass Flow rate of air entering the second fuel system of the engine. This also includes the amount of exhaust gas recirculated, if any.…";
CM_ BO_ 2364553982 "Engine Cylinder 1 Combustion Information";
CM_ SG_ 2364553982 EngineCylinder1HeatRelease "The amount of heat produced during combustion in Engine cylinder 1. The negative range is to cover thermodynamic behavior during misfire.…";
CM_ SG_ 2364553982 EngineCylinder1PeakPressure "Peak pressure in engine cylinder 1 in combustion cycle.…";
CM_ SG_ 2364553982 EngnClndr1LwFrqnKnkLvl "Indicates the level of low frequency knock for engine cylinder 1. This knock occurs at frequencies below the typical knock level reported on SPNs 1352 & 6398. T…";
CM_ SG_ 2364553982 EngnClndr1MxmmPrssrInrsRt "The maximum slope, in degrees of crank angle, of the pressure increase in engine cylinder 1 during the combustion cycle.…";
CM_ SG_ 2364553982 EngnClndr1PrssrSnsrPrlmnrFMI "Used to identify the applicable J1939-73 FMI detected in the engine cylinder 1 pressure sensor. In the case of multiple failures the most severe is communicated…";
CM_ SG_ 2364553982 EngnClndr1SnhrnsKnkLvl "Used to indicate the level of knock for engine cylinder 1. The level of knock is reported using a relative scale where 0% is least level of knock, and increasin…";
CM_ BO_ 2364554238 "Engine Cylinder 2 Combustion Information";
CM_ SG_ 2364554238 EngineCylinder2HeatRelease "The amount of heat produced during combustion in engine cylinder 2.  The negative range is to cover thermodynamic behavior during misfire.…";
CM_ SG_ 2364554238 EngineCylinder2PeakPressure "Peak pressure in engine cylinder 2 in combustion cycle.…";
CM_ SG_ 2364554238 EngnClndr2LwFrqnKnkLvl "Indicates the level of low frequency knock for engine cylinder 2. This knock occurs at frequencies below the typical knock level reported on SPNs 1353 & 6402.  …";
CM_ SG_ 2364554238 EngnClndr2MxmmPrssrInrsRt "The maximum slope, in degrees of crank angle, of the pressure increase in engine cylinder 2 during the combustion cycle.…";
CM_ SG_ 2364554238 EngnClndr2PrssrSnsrPrlmnrFMI "Used to identify the applicable J1939-73 FMI detected in the engine cylinder 2 pressure sensor.  In the case of multiple failures the most severe is communicate…";
CM_ SG_ 2364554238 EngnClndr2SnhrnsKnkLvl "Used to indicate the level of knock for engine cylinder 2. The level of knock is reported using a relative scale where 0% is least level of knock, and increasin…";
CM_ BO_ 2364554494 "Engine Cylinder 3 Combustion Information";
CM_ SG_ 2364554494 EngineCylinder3HeatRelease "The amount of heat produced during combustion in engine cylinder 3.  The negative range is to cover thermodynamic behavior during misfire.…";
CM_ SG_ 2364554494 EngineCylinder3PeakPressure "Peak pressure in engine cylinder 3 in combustion cycle.…";
CM_ SG_ 2364554494 EngnClndr3LwFrqnKnkLvl "Indicates the level of low frequency knock for engine cylinder 3. This knock occurs at frequencies below the typical knock level reported on SPNs 1354 & 6406.  …";
CM_ SG_ 2364554494 EngnClndr3MxmmPrssrInrsRt "The maximum slope, in degrees of crank angle, of the pressure increase in engine cylinder 3 during the combustion cycle.…";
CM_ SG_ 2364554494 EngnClndr3PrssrSnsrPrlmnrFMI "Used to identify the applicable J1939-73 FMI detected in the engine cylinder 3 pressure sensor.  In the case of multiple failures the most severe is communicate…";
CM_ SG_ 2364554494 EngnClndr3SnhrnsKnkLvl "Used to indicate the level of knock for engine cylinder 3. The level of knock is reported using a relative scale where 0% is least level of knock, and increasin…";
CM_ BO_ 2364554750 "Engine Cylinder 4 Combustion Information";
CM_ SG_ 2364554750 EngineCylinder4HeatRelease "The amount of heat produced during combustion in engine cylinder 4.  The negative range is to cover thermodynamic behavior during misfire.…";
CM_ SG_ 2364554750 EngineCylinder4PeakPressure "Peak pressure in engine cylinder 4 in combustion cycle.…";
CM_ SG_ 2364554750 EngnClndr4LwFrqnKnkLvl "Indicates the level of low frequency knock for engine cylinder 4. This knock occurs at frequencies below the typical knock level reported on SPNs 1355 & 6410.  …";
CM_ SG_ 2364554750 EngnClndr4MxmmPrssrInrsRt "The maximum slope, in degrees of crank angle, of the pressure increase in engine cylinder 4 during the combustion cycle.…";
CM_ SG_ 2364554750 EngnClndr4PrssrSnsrPrlmnrFMI "Used to identify the applicable J1939-73 FMI detected in the engine cylinder 4 pressure sensor. In the case of multiple failures the most severe is communicated…";
CM_ SG_ 2364554750 EngnClndr4SnhrnsKnkLvl "Used to indicate the level of knock for engine cylinder 4. The level of knock is reported using a relative scale where 0% is least level of knock, and increasin…";
CM_ BO_ 2364555006 "Engine Cylinder 5 Combustion Information";
CM_ SG_ 2364555006 EngineCylinder5HeatRelease "The amount of heat produced during combustion in engine cylinder 5.  The negative range is to cover thermodynamic behavior during misfire.…";
CM_ SG_ 2364555006 EngineCylinder5PeakPressure "Peak pressure in engine cylinder 5 in combustion cycle.…";
CM_ SG_ 2364555006 EngnClndr5LwFrqnKnkLvl "Indicates the level of low frequency knock for engine cylinder 5. This knock occurs at frequencies below the typical knock level reported on SPNs 1356 & 6414.  …";
CM_ SG_ 2364555006 EngnClndr5MxmmPrssrInrsRt "The maximum slope, in degrees of crank angle, of the pressure increase in engine cylinder 5 during the combustion cycle.…";
CM_ SG_ 2364555006 EngnClndr5PrssrSnsrPrlmnrFMI "Used to identify the applicable J1939-73 FMI detected in the engine cylinder 5 pressure sensor.  In the case of multiple failures the most severe is communicate…";
CM_ SG_ 2364555006 EngnClndr5SnhrnsKnkLvl "Used to indicate the level of knock for engine cylinder 6. The level of knock is reported using a relative scale where 0% is least level of knock, and increasin…";
CM_ BO_ 2364555262 "Engine Cylinder 6 Combustion Information";
CM_ SG_ 2364555262 EngineCylinder6HeatRelease "The amount of heat produced during combustion in engine cylinder 6.  The negative range is to cover thermodynamic behavior during misfire.…";
CM_ SG_ 2364555262 EngineCylinder6PeakPressure "Peak pressure in engine cylinder 6 in combustion cycle.…";
CM_ SG_ 2364555262 EngnClndr6LwFrqnKnkLvl "Indicates the level of low frequency knock for engine cylinder 6. This knock occurs at frequencies below the typical knock level reported on SPNs 1357 & 6418.  …";
CM_ SG_ 2364555262 EngnClndr6MxmmPrssrInrsRt "The maximum slope, in degrees of crank angle, of the pressure increase in engine cylinder 6 during the combustion cycle.…";
CM_ SG_ 2364555262 EngnClndr6PrssrSnsrPrlmnrFMI "Used to identify the applicable J1939-73 FMI detected in the engine cylinder 6 pressure sensor.  In the case of multiple failures the most severe is communicate…";
CM_ SG_ 2364555262 EngnClndr6SnhrnsKnkLvl "Used to indicate the level of knock for engine cylinder 6. The level of knock is reported using a relative scale where 0% is least level of knock, and increasin…";
CM_ BO_ 2364555518 "Engine Cylinder 7 Combustion Information";
CM_ SG_ 2364555518 EngineCylinder7HeatRelease "The amount of heat produced during combustion in engine cylinder 7.  The negative range is to cover thermodynamic behavior during misfire.…";
CM_ SG_ 2364555518 EngineCylinder7PeakPressure "Peak pressure in engine cylinder 7 in combustion cycle.…";
CM_ SG_ 2364555518 EngnClndr7LwFrqnKnkLvl "Indicates the level of low frequency knock for engine cylinder 7. This knock occurs at frequencies below the typical knock level reported on SPNs 1358 & 6422.  …";
CM_ SG_ 2364555518 EngnClndr7MxmmPrssrInrsRt "The maximum slope, in degrees of crank angle, of the pressure increase in engine cylinder 7 during the combustion cycle.…";
CM_ SG_ 2364555518 EngnClndr7PrssrSnsrPrlmnrFMI "Used to identify the applicable J1939-73 FMI detected in the engine cylinder 7 pressure sensor. In the case of multiple failures the most severe is communicated…";
CM_ SG_ 2364555518 EngnClndr7SnhrnsKnkLvl "Used to indicate the level of knock for engine cylinder 7. The level of knock is reported using a relative scale where 0% is least level of knock, and increasin…";
CM_ BO_ 2364555774 "Engine Cylinder 8 Combustion Information";
CM_ SG_ 2364555774 EngineCylinder8HeatRelease "The amount of heat produced during combustion in engine cylinder 8.  The negative range is to cover thermodynamic behavior during misfire.…";
CM_ SG_ 2364555774 EngineCylinder8PeakPressure "Peak pressure in engine cylinder 8 in combustion cycle.…";
CM_ SG_ 2364555774 EngnClndr8LwFrqnKnkLvl "Indicates the level of low frequency knock for engine cylinder 8. This knock occurs at frequencies below the typical knock level reported on SPNs 1359 & 6426.  …";
CM_ SG_ 2364555774 EngnClndr8MxmmPrssrInrsRt "The maximum slope, in degrees of crank angle, of the pressure increase in engine cylinder 8 during the combustion cycle.…";
CM_ SG_ 2364555774 EngnClndr8PrssrSnsrPrlmnrFMI "Used to identify the applicable J1939-73 FMI detected in the engine cylinder 8 pressure sensor.  In the case of multiple failures the most severe is communicate…";
CM_ SG_ 2364555774 EngnClndr8SnhrnsKnkLvl "Used to indicate the level of knock for engine cylinder 8. The level of knock is reported using a relative scale where 0% is least level of knock, and increasin…";
CM_ BO_ 2364556030 "Engine Cylinder 9 Combustion Information";
CM_ SG_ 2364556030 EngineCylinder9HeatRelease "The amount of heat produced during combustion in engine cylinder 9.  The negative range is to cover thermodynamic behavior during misfire.…";
CM_ SG_ 2364556030 EngineCylinder9PeakPressure "Peak pressure in engine cylinder 9 in combustion cycle.…";
CM_ SG_ 2364556030 EngnClndr9LwFrqnKnkLvl "Indicates the level of low frequency knock for engine cylinder 9. This knock occurs at frequencies below the typical knock level reported on SPNs 1360 & 6430.  …";
CM_ SG_ 2364556030 EngnClndr9MxmmPrssrInrsRt "The maximum slope, in degrees of crank angle, of the pressure increase in engine cylinder 9 during the combustion cycle.…";
CM_ SG_ 2364556030 EngnClndr9PrssrSnsrPrlmnrFMI "Used to identify the applicable J1939-73 FMI detected in the engine cylinder 9 pressure sensor.  In the case of multiple failures the most severe is communicate…";
CM_ SG_ 2364556030 EngnClndr9SnhrnsKnkLvl "Used to indicate the level of knock for engine cylinder 9. The level of knock is reported using a relative scale where 0% is least level of knock, and increasin…";
CM_ BO_ 2364556286 "Engine Cylinder 10 Combustion Information";
CM_ SG_ 2364556286 EngineCylinder10HeatRelease "The amount of heat produced during combustion in engine cylinder 10.  The negative range is to cover thermodynamic behavior during misfire.…";
CM_ SG_ 2364556286 EngineCylinder10PeakPressure "Peak pressure in engine cylinder 10 in combustion cycle.…";
CM_ SG_ 2364556286 EngnClndr10LwFrqnKnkLvl "Indicates the level of low frequency knock for engine cylinder 10. This knock occurs at frequencies below the typical knock level reported on SPNs 1361 & 6434. …";
CM_ SG_ 2364556286 EngnClndr10MxmmPrssrInrsRt "The maximum slope, in degrees of crank angle, of the pressure increase in engine cylinder 10 during the combustion cycle.…";
CM_ SG_ 2364556286 EngnClndr10PrssrSnsrPrlmnrFMI "Used to identify the applicable J1939-73 FMI detected in the engine cylinder 10 pressure sensor.  In the case of multiple failures the most severe is communicat…";
CM_ SG_ 2364556286 EngnClndr10SnhrnsKnkLvl "Used to indicate the level of knock for engine cylinder 10. The level of knock is reported using a relative scale where 0% is least level of knock, and increasi…";
CM_ BO_ 2364556542 "Engine Cylinder 11 Combustion Information";
CM_ SG_ 2364556542 EngineCylinder11HeatRelease "The amount of heat produced during combustion in engine cylinder 11.  The negative range is to cover thermodynamic behavior during misfire.…";
CM_ SG_ 2364556542 EngineCylinder11PeakPressure "Peak pressure in engine cylinder 11 in combustion cycle.…";
CM_ SG_ 2364556542 EngnClndr11LwFrqnKnkLvl "Indicates the level of low frequency knock for engine cylinder 11. This knock occurs at frequencies below the typical knock level reported on SPNs 1362 & 6438. …";
CM_ SG_ 2364556542 EngnClndr11MxmmPrssrInrsRt "The maximum slope, in degrees of crank angle, of the pressure increase in engine cylinder 11 during the combustion cycle.…";
CM_ SG_ 2364556542 EngnClndr11PrssrSnsrPrlmnrFMI "Used to identify the applicable J1939-73 FMI detected in the engine cylinder 11 pressure sensor.  In the case of multiple failures the most severe is communicat…";
CM_ SG_ 2364556542 EngnClndr11SnhrnsKnkLvl "Used to indicate the level of knock for engine cylinder 11. The level of knock is reported using a relative scale where 0% is least level of knock, and increasi…";
CM_ BO_ 2364556798 "Engine Cylinder 12 Combustion Information";
CM_ SG_ 2364556798 EngineCylinder12HeatRelease "The amount of heat produced during combustion in engine cylinder 12.  The negative range is to cover thermodynamic behavior during misfire.…";
CM_ SG_ 2364556798 EngineCylinder12PeakPressure "Peak pressure in engine cylinder 12 in combustion cycle.…";
CM_ SG_ 2364556798 EngnClndr12LwFrqnKnkLvl "Indicates the level of low frequency knock for engine cylinder 12. This knock occurs at frequencies below the typical knock level reported on SPNs 1363 & 6442. …";
CM_ SG_ 2364556798 EngnClndr12MxmmPrssrInrsRt "The maximum slope, in degrees of crank angle, of the pressure increase in engine cylinder 12 during the combustion cycle.…";
CM_ SG_ 2364556798 EngnClndr12PrssrSnsrPrlmnrFMI "Used to identify the applicable J1939-73 FMI detected in the engine cylinder 12 pressure sensor.  In the case of multiple failures the most severe is communicat…";
CM_ SG_ 2364556798 EngnClndr12SnhrnsKnkLvl "Used to indicate the level of knock for engine cylinder 12. The level of knock is reported using a relative scale where 0% is least level of knock, and increasi…";
CM_ BO_ 2364557054 "Engine Cylinder 13 Combustion Information";
CM_ SG_ 2364557054 EngineCylinder13HeatRelease "The amount of heat produced during combustion in engine cylinder 13.  The negative range is to cover thermodynamic behavior during misfire.…";
CM_ SG_ 2364557054 EngineCylinder13PeakPressure "Peak pressure in engine cylinder 13 in combustion cycle.…";
CM_ SG_ 2364557054 EngnClndr13LwFrqnKnkLvl "Indicates the level of low frequency knock for engine cylinder 13. This knock occurs at frequencies below the typical knock level reported on SPNs 1364 & 6446. …";
CM_ SG_ 2364557054 EngnClndr13MxmmPrssrInrsRt "The maximum slope, in degrees of crank angle, of the pressure increase in engine cylinder 13 during the combustion cycle.…";
CM_ SG_ 2364557054 EngnClndr13PrssrSnsrPrlmnrFMI "Used to identify the applicable J1939-73 FMI detected in the engine cylinder 13 pressure sensor.  In the case of multiple failures the most severe is communicat…";
CM_ SG_ 2364557054 EngnClndr13SnhrnsKnkLvl "Used to indicate the level of knock for engine cylinder 13. The level of knock is reported using a relative scale where 0% is least level of knock, and increasi…";
CM_ BO_ 2364557310 "Engine Cylinder 14 Combustion Information";
CM_ SG_ 2364557310 EngineCylinder14HeatRelease "The amount of heat produced during combustion in engine cylinder 14.  The negative range is to cover thermodynamic behavior during misfire.…";
CM_ SG_ 2364557310 EngineCylinder14PeakPressure "Peak pressure in engine cylinder 14 in combustion cycle.…";
CM_ SG_ 2364557310 EngnClndr14LwFrqnKnkLvl "Indicates the level of low frequency knock for engine cylinder 14. This knock occurs at frequencies below the typical knock level reported on SPNs 1365 & 6450. …";
CM_ SG_ 2364557310 EngnClndr14MxmmPrssrInrsRt "The maximum slope, in degrees of crank angle, of the pressure increase in engine cylinder 14 during the combustion cycle.…";
CM_ SG_ 2364557310 EngnClndr14PrssrSnsrPrlmnrFMI "Used to identify the applicable J1939-73 FMI detected in the engine cylinder 14 pressure sensor.  In the case of multiple failures the most severe is communicat…";
CM_ SG_ 2364557310 EngnClndr14SnhrnsKnkLvl "Used to indicate the level of knock for engine cylinder 14. The level of knock is reported using a relative scale where 0% is least level of knock, and increasi…";
CM_ BO_ 2364557566 "Engine Cylinder 15 Combustion Information";
CM_ SG_ 2364557566 EngineCylinder15HeatRelease "The amount of heat produced during combustion in engine cylinder 15.  The negative range is to cover thermodynamic behavior during misfire.…";
CM_ SG_ 2364557566 EngineCylinder15PeakPressure "Peak pressure in engine cylinder 15 in combustion cycle.…";
CM_ SG_ 2364557566 EngnClndr15LwFrqnKnkLvl "Indicates the level of low frequency knock for engine cylinder 15. This knock occurs at frequencies below the typical knock level reported on SPNs 1366 & 6454. …";
CM_ SG_ 2364557566 EngnClndr15MxmmPrssrInrsRt "The maximum slope, in degrees of crank angle, of the pressure increase in engine cylinder 15 during the combustion cycle.…";
CM_ SG_ 2364557566 EngnClndr15PrssrSnsrPrlmnrFMI "Used to identify the applicable J1939-73 FMI detected in the engine cylinder 15 pressure sensor.  In the case of multiple failures the most severe is communicat…";
CM_ SG_ 2364557566 EngnClndr15SnhrnsKnkLvl "Used to indicate the level of knock for engine cylinder 15. The level of knock is reported using a relative scale where 0% is least level of knock, and increasi…";
CM_ BO_ 2364557822 "Engine Cylinder 16 Combustion Information";
CM_ SG_ 2364557822 EngineCylinder16HeatRelease "The amount of heat produced during combustion in engine cylinder 16.  The negative range is to cover thermodynamic behavior during misfire.…";
CM_ SG_ 2364557822 EngineCylinder16PeakPressure "Peak pressure in engine cylinder 16 in combustion cycle.…";
CM_ SG_ 2364557822 EngnClndr16LwFrqnKnkLvl "Indicates the level of low frequency knock for engine cylinder 16. This knock occurs at frequencies below the typical knock level reported on SPNs 1367 & 6458. …";
CM_ SG_ 2364557822 EngnClndr16MxmmPrssrInrsRt "The maximum slope, in degrees of crank angle, of the pressure increase in engine cylinder 16 during the combustion cycle.…";
CM_ SG_ 2364557822 EngnClndr16PrssrSnsrPrlmnrFMI "Used to identify the applicable J1939-73 FMI detected in the engine cylinder 16 pressure sensor.  In the case of multiple failures the most severe is communicat…";
CM_ SG_ 2364557822 EngnClndr16SnhrnsKnkLvl "Used to indicate the level of knock for engine cylinder 16. The level of knock is reported using a relative scale where 0% is least level of knock, and increasi…";
CM_ BO_ 2364558078 "Engine Cylinder 17 Combustion Information";
CM_ SG_ 2364558078 EngineCylinder17HeatRelease "The amount of heat produced during combustion in engine cylinder 17.  The negative range is to cover thermodynamic behavior during misfire.…";
CM_ SG_ 2364558078 EngineCylinder17PeakPressure "Peak pressure in engine cylinder 17 in combustion cycle.…";
CM_ SG_ 2364558078 EngnClndr17LwFrqnKnkLvl "Indicates the level of low frequency knock for engine cylinder 17. This knock occurs at frequencies below the typical knock level reported on SPNs 1368 & 6462. …";
CM_ SG_ 2364558078 EngnClndr17MxmmPrssrInrsRt "The maximum slope, in degrees of crank angle, of the pressure increase in engine cylinder 17 during the combustion cycle.…";
CM_ SG_ 2364558078 EngnClndr17PrssrSnsrPrlmnrFMI "Used to identify the applicable J1939-73 FMI detected in the engine cylinder 17 pressure sensor.  In the case of multiple failures the most severe is communicat…";
CM_ SG_ 2364558078 EngnClndr17SnhrnsKnkLvl "Used to indicate the level of knock for engine cylinder 17. The level of knock is reported using a relative scale where 0% is least level of knock, and increasi…";
CM_ BO_ 2364558334 "Engine Cylinder 18 Combustion Information";
CM_ SG_ 2364558334 EngineCylinder18HeatRelease "The amount of heat produced during combustion in engine cylinder 18.  The negative range is to cover thermodynamic behavior during misfire.…";
CM_ SG_ 2364558334 EngineCylinder18PeakPressure "Peak pressure in engine cylinder 18 in combustion cycle.…";
CM_ SG_ 2364558334 EngnClndr18LwFrqnKnkLvl "Indicates the level of low frequency knock for engine cylinder 18. This knock occurs at frequencies below the typical knock level reported on SPNs 1369 & 6466. …";
CM_ SG_ 2364558334 EngnClndr18MxmmPrssrInrsRt "The maximum slope, in degrees of crank angle, of the pressure increase in engine cylinder 18 during the combustion cycle.…";
CM_ SG_ 2364558334 EngnClndr18PrssrSnsrPrlmnrFMI "Used to identify the applicable J1939-73 FMI detected in the engine cylinder 18 pressure sensor. In the case of multiple failures the most severe is communicate…";
CM_ SG_ 2364558334 EngnClndr18SnhrnsKnkLvl "Used to indicate the level of knock for engine cylinder 18. The level of knock is reported using a relative scale where 0% is least level of knock, and increasi…";
CM_ BO_ 2364558590 "Engine Cylinder 19 Combustion Information";
CM_ SG_ 2364558590 EngineCylinder19HeatRelease "The amount of heat produced during combustion in engine cylinder 19.  The negative range is to cover thermodynamic behavior during misfire.…";
CM_ SG_ 2364558590 EngineCylinder19PeakPressure "Peak pressure in engine cylinder 19 in combustion cycle.…";
CM_ SG_ 2364558590 EngnClndr19LwFrqnKnkLvl "Indicates the level of low frequency knock for engine cylinder 19. This knock occurs at frequencies below the typical knock level reported on SPNs 1370 & 6470. …";
CM_ SG_ 2364558590 EngnClndr19MxmmPrssrInrsRt "The maximum slope, in degrees of crank angle, of the pressure increase in engine cylinder 19 during the combustion cycle.…";
CM_ SG_ 2364558590 EngnClndr19PrssrSnsrPrlmnrFMI "Used to identify the applicable J1939-73 FMI detected in the engine cylinder 19 pressure sensor.  In the case of multiple failures the most severe is communicat…";
CM_ SG_ 2364558590 EngnClndr19SnhrnsKnkLvl "Used to indicate the level of knock for engine cylinder 19. The level of knock is reported using a relative scale where 0% is least level of knock, and increasi…";
CM_ BO_ 2364558846 "Engine Cylinder 20 Combustion Information";
CM_ SG_ 2364558846 EngineCylinder20HeatRelease "The amount of heat produced during combustion in engine cylinder 20.  The negative range is to cover thermodynamic behavior during misfire.…";
CM_ SG_ 2364558846 EngineCylinder20PeakPressure "Peak pressure in engine cylinder 20 in combustion cycle.…";
CM_ SG_ 2364558846 EngnClndr20LwFrqnKnkLvl "Indicates the level of low frequency knock for engine cylinder 20. This knock occurs at frequencies below the typical knock level reported on SPNs 1371 & 6474. …";
CM_ SG_ 2364558846 EngnClndr20MxmmPrssrInrsRt "The maximum slope, in degrees of crank angle, of the pressure increase in engine cylinder 20 during the combustion cycle.…";
CM_ SG_ 2364558846 EngnClndr20PrssrSnsrPrlmnrFMI "Used to identify the applicable J1939-73 FMI detected in the engine cylinder 20 pressure sensor.  In the case of multiple failures the most severe is communicat…";
CM_ SG_ 2364558846 EngnClndr20SnhrnsKnkLvl "Used to indicate the level of knock for engine cylinder 20. The level of knock is reported using a relative scale where 0% is least level of knock, and increasi…";
CM_ BO_ 2364564478 "Fuel Information 5 (Gaseous)";
CM_ SG_ 2364564478 EngnGssFlVlvNmnlDrtnCmmnd "Amount of time the gaseous fuel valves are activated.  It's a nominal value used for all the gaseous fuel valves in the engine.Note: Please see SPNs 6658 - 6677…";
CM_ SG_ 2364564478 EngnGssFlVlvNmnlStrtfAttnCmmnd "The angle, relative to the TDC of each cylinder, with 0 being the TDC before the power stroke commences, at the which gaseous fuel valves are activated to open.…";
CM_ SG_ 2364564478 EngnPrChmrFlVlvNmnlDrtnCmmnd "Amount of time the pre-chamber fuel valves are activated. It's a nominal value used for all the prechamber fuel valves in the engine.Note: Please see SPNs 9591-…";
CM_ SG_ 2364564478 EPCFVvNSttAttCd "The angle, relative to the TDC of each cylinder, with 0 being the TDC before the power stroke commences, at the which pre-chamber fuel valves are activated to o…";
CM_ BO_ 2364564734 "Engine Gaseous Fuel Valve Duration Command 1";
CM_ SG_ 2364564734 EngnGssFlVlv1DrtnCmmnd "Amount of time the gaseous fuel valve 1 is activated.…";
CM_ SG_ 2364564734 EngnGssFlVlv2DrtnCmmnd "Amount of time the gaseous fuel valve 2 is activated.…";
CM_ SG_ 2364564734 EngnGssFlVlv3DrtnCmmnd "Amount of time the gaseous fuel valve 3 is activated.…";
CM_ SG_ 2364564734 EngnGssFlVlv4DrtnCmmnd "Amount of time the gaseous fuel valve 4 is activated.…";
CM_ BO_ 2364564990 "Engine Gaseous Fuel Valve Duration Command 2";
CM_ SG_ 2364564990 EngnGssFlVlv5DrtnCmmnd "Amount of time the gaseous fuel valve 5 is activated.…";
CM_ SG_ 2364564990 EngnGssFlVlv6DrtnCmmnd "Amount of time the gaseous fuel valve 6 is activated.…";
CM_ SG_ 2364564990 EngnGssFlVlv7DrtnCmmnd "Amount of time the gaseous fuel valve 7 is activated.…";
CM_ SG_ 2364564990 EngnGssFlVlv8DrtnCmmnd "Amount of time the gaseous fuel valve 8 is activated.…";
CM_ BO_ 2364565246 "Engine Gaseous Fuel Valve Duration Command 3";
CM_ SG_ 2364565246 EngnGssFlVlv10DrtnCmmnd "Amount of time the gaseous fuel valve 10 is activated.…";
CM_ SG_ 2364565246 EngnGssFlVlv11DrtnCmmnd "Amount of time the gaseous fuel valve 11 is activated.…";
CM_ SG_ 2364565246 EngnGssFlVlv12DrtnCmmnd "Amount of time the gaseous fuel valve 12 is activated.…";
CM_ SG_ 2364565246 EngnGssFlVlv9DrtnCmmnd "Amount of time the gaseous fuel valve 9 is activated.…";
CM_ BO_ 2364565502 "Engine Gaseous Fuel Valve Duration Command 4";
CM_ SG_ 2364565502 EngnGssFlVlv13DrtnCmmnd "Amount of time the gaseous fuel valve 13 is activated.…";
CM_ SG_ 2364565502 EngnGssFlVlv14DrtnCmmnd "Amount of time the gaseous fuel valve 14 is activated.…";
CM_ SG_ 2364565502 EngnGssFlVlv15DrtnCmmnd "Amount of time the gaseous fuel valve 15 is activated.…";
CM_ SG_ 2364565502 EngnGssFlVlv16DrtnCmmnd "Amount of time the gaseous fuel valve 16 is activated.…";
CM_ BO_ 2364565758 "Engine Gaseous Fuel Valve Duration Command 5";
CM_ SG_ 2364565758 EngnGssFlVlv17DrtnCmmnd "Amount of time the gaseous fuel valve 17 is activated.…";
CM_ SG_ 2364565758 EngnGssFlVlv18DrtnCmmnd "Amount of time the gaseous fuel valve 18 is activated.…";
CM_ SG_ 2364565758 EngnGssFlVlv19DrtnCmmnd "Amount of time the gaseous fuel valve 19 is activated.…";
CM_ SG_ 2364565758 EngnGssFlVlv20DrtnCmmnd "Amount of time the gaseous fuel valve 20 is activated.…";
CM_ BO_ 2364566014 "Engine Gaseous Fuel Valve Start of Actuation Command 1";
CM_ SG_ 2364566014 EngnGssFlVlv1StrtfAttnCmmnd "The angle, relative to the TDC of cylinder 1, with 0 being the TDC before the power stroke commences, at the which gaseous fuel valve 1 is activated to open.Tim…";
CM_ SG_ 2364566014 EngnGssFlVlv2StrtfAttnCmmnd "The angle, relative to the TDC of cylinder 2, with 0 being the TDC before the power stroke commences, at the which gaseous fuel valve 2 is activated to open.Tim…";
CM_ SG_ 2364566014 EngnGssFlVlv3StrtfAttnCmmnd "The angle, relative to the TDC of cylinder 3, with 0 being the TDC before the power stroke commences, at the which gaseous fuel valve 3 is activated to open.Tim…";
CM_ SG_ 2364566014 EngnGssFlVlv4StrtfAttnCmmnd "The angle, relative to the TDC of cylinder 4, with 0 being the TDC before the power stroke commences, at the which gaseous fuel valve 4 is activated to open.Tim…";
CM_ BO_ 2364566270 "Engine Gaseous Fuel Valve Start of Actuation Command 2";
CM_ SG_ 2364566270 EngnGssFlVlv5StrtfAttnCmmnd "The angle, relative to the TDC of cylinder 5, with 0 being the TDC before the power stroke commences, at the which gaseous fuel valve 5 is activated to open.Tim…";
CM_ SG_ 2364566270 EngnGssFlVlv6StrtfAttnCmmnd "The angle, relative to the TDC of cylinder 6, with 0 being the TDC before the power stroke commences, at the which gaseous fuel valve 6 is activated to open.Tim…";
CM_ SG_ 2364566270 EngnGssFlVlv7StrtfAttnCmmnd "The angle, relative to the TDC of cylinder 7, with 0 being the TDC before the power stroke commences, at the which gaseous fuel valve 7 is activated to open.Tim…";
CM_ SG_ 2364566270 EngnGssFlVlv8StrtfAttnCmmnd "The angle, relative to the TDC of cylinder 8, with 0 being the TDC before the power stroke commences, at the which gaseous fuel valve 8 is activated to open.Tim…";
CM_ BO_ 2364566526 "Engine Gaseous Fuel Valve Start of Actuation Command 3";
CM_ SG_ 2364566526 EngnGssFlVlv10StrtfAttnCmmnd "The angle, relative to the TDC of cylinder 10, with 0 being the TDC before the power stroke commences, at the which gaseous fuel valve 10 is activated to open.T…";
CM_ SG_ 2364566526 EngnGssFlVlv11StrtfAttnCmmnd "The angle, relative to the TDC of cylinder 11, with 0 being the TDC before the power stroke commences, at the which gaseous fuel valve 11 is activated to open.T…";
CM_ SG_ 2364566526 EngnGssFlVlv12StrtfAttnCmmnd "The angle, relative to the TDC of cylinder 12, with 0 being the TDC before the power stroke commences, at the which gaseous fuel valve 12 is activated to open.T…";
CM_ SG_ 2364566526 EngnGssFlVlv9StrtfAttnCmmnd "The angle, relative to the TDC of cylinder 9, with 0 being the TDC before the power stroke commences, at the which gaseous fuel valve 9 is activated to open.Tim…";
CM_ BO_ 2364566782 "Engine Gaseous Fuel Valve Start of Actuation Command 4";
CM_ SG_ 2364566782 EngnGssFlVlv13StrtfAttnCmmnd "The angle, relative to the TDC of cylinder 13, with 0 being the TDC before the power stroke commences, at the which gaseous fuel valve 13 is activated to open.T…";
CM_ SG_ 2364566782 EngnGssFlVlv14StrtfAttnCmmnd "The angle, relative to the TDC of cylinder 14, with 0 being the TDC before the power stroke commences, at the which gaseous fuel valve 14 is activated to open.T…";
CM_ SG_ 2364566782 EngnGssFlVlv15StrtfAttnCmmnd "The angle, relative to the TDC of cylinder 15, with 0 being the TDC before the power stroke commences, at the which gaseous fuel valve 15 is activated to open.T…";
CM_ SG_ 2364566782 EngnGssFlVlv16StrtfAttnCmmnd "The angle, relative to the TDC of cylinder 16, with 0 being the TDC before the power stroke commences, at the which gaseous fuel valve 16 is activated to open.T…";
CM_ BO_ 2364567038 "Engine Gaseous Fuel Valve Start of Actuation Command 5";
CM_ SG_ 2364567038 EngnGssFlVlv17StrtfAttnCmmnd "The angle, relative to the TDC of cylinder 17, with 0 being the TDC before the power stroke commences, at the which gaseous fuel valve 17 is activated to open.T…";
CM_ SG_ 2364567038 EngnGssFlVlv18StrtfAttnCmmnd "The angle, relative to the TDC of cylinder 18, with 0 being the TDC before the power stroke commences, at the which gaseous fuel valve 18 is activated to open.T…";
CM_ SG_ 2364567038 EngnGssFlVlv19StrtfAttnCmmnd "The angle, relative to the TDC of cylinder 19, with 0 being the TDC before the power stroke commences, at the which gaseous fuel valve 19 is activated to open.T…";
CM_ SG_ 2364567038 EngnGssFlVlv20StrtfAttnCmmnd "The angle, relative to the TDC of cylinder 20, with 0 being the TDC before the power stroke commences, at the which gaseous fuel valve 20 is activated to open.T…";
CM_ BO_ 2364567294 "Fuel Pump Actuator Control Command";
CM_ SG_ 2364567294 EngnFlInjtnPmp1FlCntrlVlvCmmnd "The control command to fuel control valve in fuel pump 1, normalized to percent, where 0% represents fully closed and 100% represents fully open.…";
CM_ SG_ 2364567294 EngnFlInjtnPmp2FlCntrlVlvCmmnd "The control command to fuel control valve in fuel pump 2, normalized to percent, where 0% represents fully closed and 100% represents fully open.…";
CM_ BO_ 2364575998 "High Voltage Energy Storage 1 Data 1";
CM_ SG_ 2364575998 HVES1AvailableChargePower "The rate at which the High Voltage Energy Storage 1 pack (or system) can currently receive energy from a regenerative or recharging system.…";
CM_ SG_ 2364575998 HVES1AvailableDischargePower "The rate at which the High Voltage Energy Storage 1 pack (or system) can currently provide energy for propulsion or other uses.…";
CM_ SG_ 2364575998 HVES1Current "The current in or out of the High Voltage Energy Storage 1 pack (or system).  This parameter should be synchronized with SPN 5919 (HVES1 Voltage Level) such tha…";
CM_ SG_ 2364575998 HVES1VoltageLevel "The voltage level of the High Voltage Energy Storage 1 pack (or system).  This parameter should be synchronized with SPN 5920 (HVES1 Current) such that a realiz…";
CM_ BO_ 2364576254 "High Voltage Energy Storage 1 Data 2";
CM_ SG_ 2364576254 HVES1CllVltgDffrntlStts "Indicates whether or not the differential between the highest and lowest cell voltages are within acceptable limits, according to the High Voltage Energy Storag…";
CM_ SG_ 2364576254 HVES1FastUpdateStateofCharge "Indicates the High Voltage Energy Storage 1 pack (or system) state of charge.  0% means no charge remaining, 100% means the system is fully charged in terms of …";
CM_ SG_ 2364576254 HVES1HighestCellVoltage "The highest voltage level reported by any cell in the High Voltage Energy Storage 1 pack (or system).  If a single voltage sensor covers more than one cell, the…";
CM_ SG_ 2364576254 HVES1LowestCellVoltage "The lowest voltage level reported by any cell in the High Voltage Energy Storage 1 pack (or system).   If a single voltage sensor covers more than one cell, the…";
CM_ BO_ 2364576510 "High Voltage Energy Storage 1 Data 3";
CM_ SG_ 2364576510 HVES1AverageCellTemperature "The average temperature level of all cells in the High Voltage Energy Storage 1 pack (or system).…";
CM_ SG_ 2364576510 HVES1CllTmprtrDffrntlStts "Indicates whether or not the differential between the highest and lowest cell temperatures are within acceptable limits per the High Voltage Energy Storage 1 pa…";
CM_ SG_ 2364576510 HVES1HighestCellTemperature "The highest temperature level reported by any cell in the High Voltage Energy Storage 1 pack (or system).  If a single temperature sensor covers more than one c…";
CM_ SG_ 2364576510 HVES1LowestCellTemperature "The lowest temperature level reported by any cell in the High Voltage Energy Storage 1 pack (or system).  If a single temperature sensor covers more than one ce…";
CM_ BO_ 2364576766 "High Voltage Energy Storage 1 Data 4";
CM_ SG_ 2364576766 HVES1CellBalancingCount "The number of cells that are currently being balanced in the High Voltage Energy Storage 1 pack (or system).…";
CM_ SG_ 2364576766 HVES1ChargeCapacity "The amount of unused electrical charge storage in the High Voltage Energy Storage 1 pack (or system) that is available to be filled by charging, i.e. “how much …";
CM_ SG_ 2364576766 HVES1DischargeCapacity "The amount of stored electrical charge in the High Voltage Energy Storage 1 pack (or system) that is available for use by the hybrid system, i.e. “how full is t…";
CM_ BO_ 2364577022 "High Voltage Energy Storage 1 Data 5";
CM_ SG_ 2364577022 HVES1ChargeCurrentLimit "The maximum permissible current flow into the High Voltage Energy Storage 1 pack (or system).  This parameter is defined from the high voltage energy storage sy…";
CM_ SG_ 2364577022 HVES1DischargeCurrentLimit "The maximum permissible current flow out of the High Voltage Energy Storage 1 pack (or system).  This parameter is defined from the high voltage energy storage …";
CM_ SG_ 2364577022 HVES1MaximumCellStateofCharge "Indicates the state of charge of the highest-charged cell in the High Voltage Energy Storage 1 pack (or system).  0% means no charge remaining, 100% means the c…";
CM_ SG_ 2364577022 HVES1MinimumCellStateofCharge "Indicates the state of charge of the lowest-charged cell in the High Voltage Energy Storage 1 pack (or system).  0% means no charge remaining, 100% means the ce…";
CM_ BO_ 2364577278 "High Voltage Energy Storage 1 Data 6";
CM_ SG_ 2364577278 HVES1BusVoltage "The voltage level of the high voltage bus, as measured by the High Voltage Energy Storage 1 pack (or system) on the bus side (not the battery side) of its conta…";
CM_ SG_ 2364577278 HVES1ElectronicsTemperature "The temperature of the electronics or control modules in the High Voltage Energy Storage 1 pack (or system).  If there are mulitple temperature sensors then thi…";
CM_ SG_ 2364577278 HVES1IgnitionVoltage "The voltage level at the ignition input of the High Voltage Energy Storage 1 pack (or system) controller.…";
CM_ SG_ 2364577278 HVES1IntakeCoolantTemperature "The temperature of liquid coolant as it enters the High Voltage Energy Storage 1 pack (or system).…";
CM_ SG_ 2364577278 HVES1OutletCoolantTemperature "The temperature of liquid coolant as it exits the High Voltage Energy Storage 1 pack (or system).…";
CM_ SG_ 2364577278 HVES1Temperature "The temperature of High Voltage Energy Storage 1 pack (or system). The value may be determined from a unique sensor specifically for this purpose, or by aggrega…";
CM_ BO_ 2364577534 "High Voltage Energy Storage 1 Status 1";
CM_ SG_ 2364577534 HVES1CellBalanceStatus "Indicates whether or not the cells in the High Voltage Energy Storage 1 pack (or system) are balanced.00b = Cells are balanced01b = Cells are unbalanced10b = Er…";
CM_ SG_ 2364577534 HVES1CellBalancingActive "Indicates whether or not the cells in the High Voltage Energy Storage 1 pack (or system) are currently being balanced.00b = Cell balancing is not active01b = Ce…";
CM_ SG_ 2364577534 HVES1CenterofPackContactorState "Position of the center high-voltage contactor.  When this contactor is closed, the positive half of the High Voltage Energy Storage 1 pack (or system) is connec…";
CM_ SG_ 2364577534 HVES1HghVltgBsAtvIsltnTstStts "Status of the high-voltage bus electrical active isolation test as performed by the High Voltage Energy Storage 1 pack (or system).0000b = No test requested / N…";
CM_ SG_ 2364577534 HVES1HghVltgBsCnntnStts "This parameter provides high level feedback on the HVES1 pack (or system) high voltage bus connection.  For specific contactor information, see HVES1 High-Volta…";
CM_ SG_ 2364577534 HVES1HghVltgBsDsnntFrwrnng "Indicates that the High Voltage Energy Storage 1 pack (or system) is about to disconnect from the high voltage bus due to unacceptable conditions.0000b = Discon…";
CM_ SG_ 2364577534 HVES1HghVltgBsNgtvCnttrStt "Position of the High Voltage Energy Storage 1 pack (or system) negative side bus contactor.  When this contactor is closed, the negative side of HVES1 is connec…";
CM_ SG_ 2364577534 HVES1HghVltgBsPrChrgRlStt "Position of the high-voltage bus contactor pre-charge relay.  When this relay is closed, the High Voltage Energy Storage 1 pack (or system) is bringing the high…";
CM_ SG_ 2364577534 HVES1HghVltgBsPssvIsltnTstStts "Status of the high-voltage bus electrical passive isolation test as performed by the High Voltage Energy Storage 1 pack (or system).0000b = No test requested / …";
CM_ SG_ 2364577534 HVES1HghVltgBsPstvCnttrStt "Position of the High Voltage Energy Storage 1 pack (or system) positive side bus contactor.  When this contactor is closed, the positive side of HVES1 is connec…";
CM_ SG_ 2364577534 HVES1HVILStatus "Status of the High Voltage Interlock Loop from the viewpoint of the High Voltage Energy Storage 1 pack (or system).00b = HVIL Closed01b = HVIL Open10b = Error11…";
CM_ SG_ 2364577534 HVES1InertiaSwitchStatus "Switch indicating that an impact has been sensed by the High Voltage Energy Storage 1 pack (or system).   The impact indication may require action by another co…";
CM_ SG_ 2364577534 HVES1InternalChargerStatus "Indicates that the charger in the HVES1 is on.  External chargers may use the External Energy Source Connection Status (SPN 7898) and related SPNs.00b = Chargin…";
CM_ SG_ 2364577534 HVES1OperationalStatus "Provides feedback on where the HVES1 pack (or system) is in its operating spectrum, and includes feedback in response to the Operation Consent [i.e. HVES1 Opera…";
CM_ SG_ 2364577534 HVES1StateofChargeStatus "Status of the High Voltage Energy Storage 1 pack (or system) State of Charge (SOC).  Note:  A given HVES controller may not support all of the states.0000b = SO…";
CM_ BO_ 2364580094 "High Voltage Energy Storage 1 Data 7";
CM_ SG_ 2364580094 HVES1ChargeEnergyCapacity "The amount of unused electrical energy storage available to be filled by charging High Voltage Energy Storage 1 pack (or system), i.e. “how much empty space is …";
CM_ SG_ 2364580094 HVES1DischargeEnergyCapacity "The amount of stored electrical energy in High Voltage Energy Storage 1 pack (or system) that is available for use by the hybrid system, i.e. “how full is the t…";
CM_ SG_ 2364580094 HVES1MaximumChargeVoltageLimit "The maximum voltage level not to be exceeded while charging the High Voltage Energy Storage 1 pack (or system).  If this parameter is not supported, the maximum…";
BA_DEF_ SG_  "SPN" INT 0 524287;
BA_DEF_ BO_  "VFrameFormat" ENUM  "StandardCAN","ExtendedCAN","reserved","J1939PG";
BA_DEF_  "DatabaseVersion" STRING ;
BA_DEF_  "BusType" STRING ;
BA_DEF_  "ProtocolType" STRING ;
BA_DEF_  "DatabaseCompiler" STRING ;
BA_DEF_DEF_  "SPN" 0;
BA_DEF_DEF_  "VFrameFormat" "J1939PG";
BA_DEF_DEF_  "DatabaseVersion" "";
BA_DEF_DEF_  "BusType" "";
BA_DEF_DEF_  "ProtocolType" "";
BA_DEF_DEF_  "DatabaseCompiler" "";
BA_ "ProtocolType" "J1939";
BA_ "BusType" "CAN";
BA_ "DatabaseCompiler" "CSS ELECTRONICS (WWW.CSSELECTRONICS.COM)";
BA_ "DatabaseVersion" "1.0.0";
BA_ "SPN" SG_ 2163223550 CrashChecksum 4975;
BA_ "SPN" SG_ 2163223550 CrashCounter 4974;
BA_ "SPN" SG_ 2163223550 CrashType 4973;
BA_ "SPN" SG_ 2230333950 WandAngle 5821;
BA_ "SPN" SG_ 2230333950 WandSensorFigureofMerit 5822;
BA_ "SPN" SG_ 2230334206 LnrDsplmntSnsrSnsrFgrfMrt 5824;
BA_ "SPN" SG_ 2230334206 MeasuredLinearDisplacement 5823;
BA_ "SPN" SG_ 2297441534 DropRelayControl 5403;
BA_ "SPN" SG_ 2297441534 GnrtrCrrntBstAtvStts 5012;
BA_ "SPN" SG_ 2297441534 LiftRelayControl 5402;
BA_ "SPN" SG_ 2297441534 MagnetForwardCurrent 5008;
BA_ "SPN" SG_ 2297441534 MagnetGeneratorControl 5551;
BA_ "SPN" SG_ 2297441534 MagnetReverseCurrent 5009;
BA_ "SPN" SG_ 2297441534 MaterialDropActiveStatus 5014;
BA_ "SPN" SG_ 2297441534 MaterialDropSwitch 5011;
BA_ "SPN" SG_ 2297441534 MaterialLiftActiveStatus 5013;
BA_ "SPN" SG_ 2297441534 MaterialLiftSwitch 5010;
BA_ "SPN" SG_ 2297441790 LngtdnlAlrtnExtnddRng 5348;
BA_ "SPN" SG_ 2297441790 LngtdnlAlrtnFgrfMrtExtnddRng 5351;
BA_ "SPN" SG_ 2297441790 LtrlAlrtnExtnddRng 5347;
BA_ "SPN" SG_ 2297441790 LtrlAlrtnFgrfMrtExtnddRng 5350;
BA_ "SPN" SG_ 2297441790 SpptVTsssRpttRtAtSs 5353;
BA_ "SPN" SG_ 2297441790 VrtlAlrtnExtnddRng 5349;
BA_ "SPN" SG_ 2297441790 VrtlAlrtnFgrfMrtExtnddRng 5352;
BA_ "SPN" SG_ 2297455358 TrnsmssnDrtnlOtptShftSpd 6585;
BA_ "SPN" SG_ 2297455358 TrnsmssnHdrsttLp1Prssr 6583;
BA_ "SPN" SG_ 2297455358 TrnsmssnHdrsttLp2Prssr 6584;
BA_ "SPN" SG_ 2297455358 TrnsmssnIntrmdtShftSpd 160;
BA_ "SPN" SG_ 2297499902 BrakePedalSwitch2 603;
BA_ "SPN" SG_ 2297499902 DmnddBrkAppltnPrssr 8484;
BA_ "SPN" SG_ 2298375934 FrontAxleLeftWheelSpeed 1592;
BA_ "SPN" SG_ 2298375934 Frontaxlerightwheelspeed 1593;
BA_ "SPN" SG_ 2298375934 Rearaxleleftwheelspeed 1594;
BA_ "SPN" SG_ 2298375934 Rearaxlerightwheelspeed 1595;
BA_ "SPN" SG_ 2348875518 EngineOverrideControlMode 695;
BA_ "SPN" SG_ 2348875518 EngineRequestedSpeedSpeedLimit 898;
BA_ "SPN" SG_ 2348875518 EngineRequestedTorqueFractional 4191;
BA_ "SPN" SG_ 2348875518 EngnRqstdSpdCntrlCndtns 696;
BA_ "SPN" SG_ 2348875518 EngnRqstdTrqTrqLmt 518;
BA_ "SPN" SG_ 2348875518 MessageChecksum 4207;
BA_ "SPN" SG_ 2348875518 MessageCounter 4206;
BA_ "SPN" SG_ 2348875518 OverrideControlModePriority 897;
BA_ "SPN" SG_ 2348875518 TSC1ControlPurpose 3350;
BA_ "SPN" SG_ 2348875518 TSC1TransmissionRate 3349;
BA_ "SPN" SG_ 2348941054 DisengageDrivelineRequest 683;
BA_ "SPN" SG_ 2348941054 DsnggDffrntlLkRqstCntrl 689;
BA_ "SPN" SG_ 2348941054 DsnggDffrntlLkRqstCntrlFrnt 690;
BA_ "SPN" SG_ 2348941054 DsnggDffrntlLkRqstCntrlRr 691;
BA_ "SPN" SG_ 2348941054 DsnggDffrntlLkRqstFrntAxl1 685;
BA_ "SPN" SG_ 2348941054 DsnggDffrntlLkRqstFrntAxl2 686;
BA_ "SPN" SG_ 2348941054 DsnggDffrntlLkRqstRrAxl1 687;
BA_ "SPN" SG_ 2348941054 DsnggDffrntlLkRqstRrAxl2 688;
BA_ "SPN" SG_ 2348941054 RequestedPercentClutchSlip 684;
BA_ "SPN" SG_ 2348941054 TransmissionMode1 1852;
BA_ "SPN" SG_ 2348941054 TransmissionMode2 1853;
BA_ "SPN" SG_ 2348941054 TransmissionMode3 1854;
BA_ "SPN" SG_ 2348941054 TransmissionMode4 1855;
BA_ "SPN" SG_ 2348941054 TransmissionMode5 4246;
BA_ "SPN" SG_ 2348941054 TransmissionMode6 4247;
BA_ "SPN" SG_ 2348941054 TransmissionMode7 4248;
BA_ "SPN" SG_ 2348941054 TransmissionMode8 4249;
BA_ "SPN" SG_ 2348941054 TransmissionRequestedGear 525;
BA_ "SPN" SG_ 2348941054 TransmissionRequestedLaunchGear 4255;
BA_ "SPN" SG_ 2348941054 TrnsmssnAtNtrlMnlRtrnRqst 7695;
BA_ "SPN" SG_ 2348941054 TrnsmssnGrShftInhtRqst 681;
BA_ "SPN" SG_ 2348941054 TrnsmssnLdRdtnInhtRqst 5762;
BA_ "SPN" SG_ 2348941054 TrnsmssnRvrsGrShftInhtRqst 4242;
BA_ "SPN" SG_ 2348941054 TrnsmssnShftSltrDsplMdSwth 2985;
BA_ "SPN" SG_ 2348941054 TrnsmssnTrqCnvrtrLkpRqst 682;
BA_ "SPN" SG_ 2349137662 ExternalAccelerationDemand 2920;
BA_ "SPN" SG_ 2349137662 XBRControlMode 2916;
BA_ "SPN" SG_ 2349137662 XBREBIMode 2914;
BA_ "SPN" SG_ 2349137662 XBRMessageChecksum 3188;
BA_ "SPN" SG_ 2349137662 XBRMessageCounter 3189;
BA_ "SPN" SG_ 2349137662 XBRPriority 2915;
BA_ "SPN" SG_ 2349137662 XBRurgency 4099;
BA_ "SPN" SG_ 2349399806 AuxiliaryIOChannel3 4158;
BA_ "SPN" SG_ 2349399806 AuxiliaryIOChannel4 4157;
BA_ "SPN" SG_ 2349399806 AuxiliaryIOChannel5 4156;
BA_ "SPN" SG_ 2349399806 AuxiliaryIOChannel6 4155;
BA_ "SPN" SG_ 2349465342 StaticRollAngle 5582;
BA_ "SPN" SG_ 2349465342 StaticRollAngleStatus 5583;
BA_ "SPN" SG_ 2349530878 CruiseControlDisableCommand 5603;
BA_ "SPN" SG_ 2349530878 CruiseControlPauseCommand 5605;
BA_ "SPN" SG_ 2349530878 CruiseControlResumeCommand 5604;
BA_ "SPN" SG_ 2349530878 IdleControlEnableState 8439;
BA_ "SPN" SG_ 2349530878 IdleControlRequestActivation 8440;
BA_ "SPN" SG_ 2349530878 IdleSpeedRequest 8438;
BA_ "SPN" SG_ 2349530878 CruiseControlSetCommand 9843;
BA_ "SPN" SG_ 2349530878 RemoteRoadSpeedLimitRequest 9569;
BA_ "SPN" SG_ 2349596414 AEBS2messagechecksum 5683;
BA_ "SPN" SG_ 2349596414 AEBS2messageCounter 5682;
BA_ "SPN" SG_ 2349596414 DvtvtddAdvdEBSst 5681;
BA_ "SPN" SG_ 2349727486 TransmissionMode10 6570;
BA_ "SPN" SG_ 2349727486 TransmissionMode9 6569;
BA_ "SPN" SG_ 2350644990 HVES1CellBalancingCommand 8127;
BA_ "SPN" SG_ 2350644990 HVES1EnlIntrnlChrgrCmmnd 8213;
BA_ "SPN" SG_ 2350644990 HVES1HghVltgBsAtvIsltnTstCmmnd 8125;
BA_ "SPN" SG_ 2350644990 HVES1HghVltgBsCnntCmmnd 8123;
BA_ "SPN" SG_ 2350644990 HVES1HghVltgBsLwSdRsstrCnntRqst 8434;
BA_ "SPN" SG_ 2350644990 HVES1HghVltgBsPssvIsltnTstCmmnd 8126;
BA_ "SPN" SG_ 2350644990 HVES1HVtBsHSdRsstCtRqst 8433;
BA_ "SPN" SG_ 2350644990 HVES1OperationConsent 8412;
BA_ "SPN" SG_ 2350644990 HVES1PowerDownCommand 8124;
BA_ "SPN" SG_ 2350710526 MessageChecksum 7042;
BA_ "SPN" SG_ 2350710526 MessageCounter 7041;
BA_ "SPN" SG_ 2350710526 TransmissionOverrideControlMode 7037;
BA_ "SPN" SG_ 2350710526 TrnsmssnOvrrdCntrlMdPrrt 7038;
BA_ "SPN" SG_ 2350710526 TrnsmssnRqstdOtptShftSpd 7039;
BA_ "SPN" SG_ 2350710526 TrnsmssnRqstdTrqTrqLmt 7040;
BA_ "SPN" SG_ 2350776062 EngineTimingAdvance 7355;
BA_ "SPN" SG_ 2350841598 AlternatorTorqueRampTimeCommand 7591;
BA_ "SPN" SG_ 2350841598 AltrntrExttnMxmmCrrntLmt 7590;
BA_ "SPN" SG_ 2350841598 AltrntrStpntVltgCmmnd 7589;
BA_ "SPN" SG_ 2350841598 AltrntrTrqRmpMxmmSpdCmmnd 7592;
BA_ "SPN" SG_ 2358902526 Joystick1Lamp10Command 4469;
BA_ "SPN" SG_ 2358902526 Joystick1Lamp1Command 4460;
BA_ "SPN" SG_ 2358902526 Joystick1Lamp2Command 4461;
BA_ "SPN" SG_ 2358902526 Joystick1Lamp3Command 4462;
BA_ "SPN" SG_ 2358902526 Joystick1Lamp4Command 4463;
BA_ "SPN" SG_ 2358902526 Joystick1Lamp5Command 4464;
BA_ "SPN" SG_ 2358902526 Joystick1Lamp6Command 4465;
BA_ "SPN" SG_ 2358902526 Joystick1Lamp7Command 4466;
BA_ "SPN" SG_ 2358902526 Joystick1Lamp8Command 4467;
BA_ "SPN" SG_ 2358902526 Joystick1Lamp9Command 4468;
BA_ "SPN" SG_ 2358902526 Joystick2Lamp10Command 4479;
BA_ "SPN" SG_ 2358902526 Joystick2Lamp1Command 4470;
BA_ "SPN" SG_ 2358902526 Joystick2Lamp2Command 4471;
BA_ "SPN" SG_ 2358902526 Joystick2Lamp3Command 4472;
BA_ "SPN" SG_ 2358902526 Joystick2Lamp4Command 4473;
BA_ "SPN" SG_ 2358902526 Joystick2Lamp5Command 4474;
BA_ "SPN" SG_ 2358902526 Joystick2Lamp6Command 4475;
BA_ "SPN" SG_ 2358902526 Joystick2Lamp7Command 4476;
BA_ "SPN" SG_ 2358902526 Joystick2Lamp8Command 4477;
BA_ "SPN" SG_ 2358902526 Joystick2Lamp9Command 4478;
BA_ "SPN" SG_ 2358902526 Joystick3Lamp10Command 4489;
BA_ "SPN" SG_ 2358902526 Joystick3Lamp1Command 4480;
BA_ "SPN" SG_ 2358902526 Joystick3Lamp2Command 4481;
BA_ "SPN" SG_ 2358902526 Joystick3Lamp3Command 4482;
BA_ "SPN" SG_ 2358902526 Joystick3Lamp4Command 4483;
BA_ "SPN" SG_ 2358902526 Joystick3Lamp5Command 4484;
BA_ "SPN" SG_ 2358902526 Joystick3Lamp6Command 4485;
BA_ "SPN" SG_ 2358902526 Joystick3Lamp7Command 4486;
BA_ "SPN" SG_ 2358902526 Joystick3Lamp8Command 4487;
BA_ "SPN" SG_ 2358902526 Joystick3Lamp9Command 4488;
BA_ "SPN" SG_ 2362572542 LevelPresetFrontAxleLeft 1732;
BA_ "SPN" SG_ 2362572542 LevelPresetFrontAxleRight 1757;
BA_ "SPN" SG_ 2362572542 LevelPresetRearAxleLeft 1758;
BA_ "SPN" SG_ 2362572542 LevelPresetRearAxleRight 1735;
BA_ "SPN" SG_ 2362638078 AllwLvlCntrlDrngBrkngCmmnd 5293;
BA_ "SPN" SG_ 2362638078 Atmttrtnhlpldtrnsfr 2984;
BA_ "SPN" SG_ 2362638078 DamperStiffnessRequestFrontAxle 1718;
BA_ "SPN" SG_ 2362638078 DamperStiffnessRequestRearAxle 1719;
BA_ "SPN" SG_ 2362638078 DmprStffnssRqstLftTgAxl 1720;
BA_ "SPN" SG_ 2362638078 KneelingCommandFrontAxle 1830;
BA_ "SPN" SG_ 2362638078 KneelingCommandRearAxle 1829;
BA_ "SPN" SG_ 2362638078 KneelingControlModeRequest 1747;
BA_ "SPN" SG_ 2362638078 KneelingRequestLeftSide 1749;
BA_ "SPN" SG_ 2362638078 KneelingRequestRightSide 1748;
BA_ "SPN" SG_ 2362638078 LevelControlModeRequest 1753;
BA_ "SPN" SG_ 2362638078 LiftAxle1PositionCommand 1752;
BA_ "SPN" SG_ 2362638078 LiftAxle2PositionCommand 1828;
BA_ "SPN" SG_ 2362638078 Memorylevelrequest 5433;
BA_ "SPN" SG_ 2362638078 NominalLevelRequestFrontAxle 1751;
BA_ "SPN" SG_ 2362638078 NominalLevelRequestRearAxle 1750;
BA_ "SPN" SG_ 2362638078 PrhtAtmtArSspnsnCntrl 5274;
BA_ "SPN" SG_ 2362638078 Prohibitairsuspensioncontrol 3215;
BA_ "SPN" SG_ 2362638078 SpdDpndntLvlCntrlRqst 5295;
BA_ "SPN" SG_ 2364539646 EngineMomentaryOverspeedEnable 606;
BA_ "SPN" SG_ 2364539646 MmntrEngnMxmmPwrEnl 5015;
BA_ "SPN" SG_ 2364539646 PercentClutchSlip 522;
BA_ "SPN" SG_ 2364539646 ProgressiveShiftDisable 607;
BA_ "SPN" SG_ 2364539646 SAddssCtDvTsssCt 1482;
BA_ "SPN" SG_ 2364539646 Transmission1InputShaftSpeed 161;
BA_ "SPN" SG_ 2364539646 Transmission1OutputShaftSpeed 191;
BA_ "SPN" SG_ 2364539646 TransmissionDrivelineEngaged 560;
BA_ "SPN" SG_ 2364539646 TransmissionShiftInProcess 574;
BA_ "SPN" SG_ 2364539646 TrnsmssnTrqCnvrtrLkpEnggd 573;
BA_ "SPN" SG_ 2364539646 TrnsmssnTrqCnvrtrLkpTrnstnnPrss 4816;
BA_ "SPN" SG_ 2364539902 AcceleratorPedal1LowIdleSwitch 558;
BA_ "SPN" SG_ 2364539902 AcceleratorPedal2LowIdleSwitch 2970;
BA_ "SPN" SG_ 2364539902 AcceleratorPedalKickdownSwitch 559;
BA_ "SPN" SG_ 2364539902 AcceleratorPedalPosition1 91;
BA_ "SPN" SG_ 2364539902 AtlMxmmAvllEngnPrntTrq 3357;
BA_ "SPN" SG_ 2364539902 DPFThermalManagementActive 5399;
BA_ "SPN" SG_ 2364539902 EnginePercentLoadAtCurrentSpeed 92;
BA_ "SPN" SG_ 2364539902 EstimatedPumpingPercentTorque 5398;
BA_ "SPN" SG_ 2364539902 MmntrEngnMxmmPwrEnlFdk 5021;
BA_ "SPN" SG_ 2364539902 RemoteAcceleratorPedalPosition 974;
BA_ "SPN" SG_ 2364539902 RoadSpeedLimitStatus 1437;
BA_ "SPN" SG_ 2364539902 SCRThermalManagementActive 5400;
BA_ "SPN" SG_ 2364539902 VhlAlrtnRtLmtStts 2979;
BA_ "SPN" SG_ 2364539902 AcceleratorPedal2Position 29;
BA_ "SPN" SG_ 2364540158 ActualEnginePercentTorque 513;
BA_ "SPN" SG_ 2364540158 AtlEngnPrntTrqFrtnl 4154;
BA_ "SPN" SG_ 2364540158 DrvrsDmndEngnPrntTrq 512;
BA_ "SPN" SG_ 2364540158 EngineSpeed 190;
BA_ "SPN" SG_ 2364540158 EngineStarterMode 1675;
BA_ "SPN" SG_ 2364540158 EngineTorqueMode 899;
BA_ "SPN" SG_ 2364540158 SrAddrssfCntrllngDvfrEngnCntrl 1483;
BA_ "SPN" SG_ 2364540158 EngineDemandPercentTorque 2432;
BA_ "SPN" SG_ 2364541694 EngineIntakeAirMassFlowRate 132;
BA_ "SPN" SG_ 2364541694 EngnExhstGsRrltn1MssFlwRt 2659;
BA_ "SPN" SG_ 2364541694 EngnExhstGsRrltn2MssFlwRt 5257;
BA_ "SPN" SG_ 2364542206 TrnsmssnClthCnvrtrInptSpd 5052;
BA_ "SPN" SG_ 2364542206 TrnsmssnTrqCnvrtrRt 3030;
BA_ "SPN" SG_ 2364542206 TransmissionShiftInhibitReason 10152;
BA_ "SPN" SG_ 2364542206 TrnsmssnTrqCnvrtrLkpInhtRsn 10151;
BA_ "SPN" SG_ 2364542206 TrnsmssnTrqCnvrtrLkpInhtIndtr 10150;
BA_ "SPN" SG_ 2364542462 BladeAutoModeCommand 3158;
BA_ "SPN" SG_ 2364542462 BladeControlModeSwitch 3156;
BA_ "SPN" SG_ 2364542462 DesiredGradeOffsetSwitch 3157;
BA_ "SPN" SG_ 2364542462 LftBldCntrlMdOprtrCntrl 3334;
BA_ "SPN" SG_ 2364542462 LftDsrdBldOffstOprtrCntrl 3336;
BA_ "SPN" SG_ 2364542462 RghtBldCntrlMdOprtrCntrl 3335;
BA_ "SPN" SG_ 2364542462 RghtDsrdBldOffstOprtrCntrl 3337;
BA_ "SPN" SG_ 2364542462 SdshftBldCntrlMdOprtrCntrl 3338;
BA_ "SPN" SG_ 2364542462 SdshftDsrdBldOffstOprtrCntrl 3339;
BA_ "SPN" SG_ 2364542462 StElvtnSnsr1RfrnElvtn 5405;
BA_ "SPN" SG_ 2364542462 StElvtnSnsr2RfrnElvtn 5406;
BA_ "SPN" SG_ 2364543998 PitchandRollCompensated 3326;
BA_ "SPN" SG_ 2364543998 PitchAngle 3318;
BA_ "SPN" SG_ 2364543998 PitchAngleFigureofMerit 3323;
BA_ "SPN" SG_ 2364543998 PitchRate 3322;
BA_ "SPN" SG_ 2364543998 PitchRateFigureofMerit 3325;
BA_ "SPN" SG_ 2364543998 RollandPitchMeasurementLatency 3327;
BA_ "SPN" SG_ 2364543998 RollAngle 3319;
BA_ "SPN" SG_ 2364543998 RollAngleFigureofMerit 3324;
BA_ "SPN" SG_ 2364544254 BladeRotationAngle 3331;
BA_ "SPN" SG_ 2364544254 BladeRotationAngleFigureofMerit 3332;
BA_ "SPN" SG_ 2364544254 RelativeBladeHeight 3365;
BA_ "SPN" SG_ 2364544254 RltvBldHghtFgrfMrt 3367;
BA_ "SPN" SG_ 2364544254 RtvBdHtdBdRttAMstLt 3366;
BA_ "SPN" SG_ 2364544510 RqstdGnrtrOvrllPwrFtr 3384;
BA_ "SPN" SG_ 2364544510 RqstdGnrtrOvrllPwrFtrLggng 3385;
BA_ "SPN" SG_ 2364544510 RqstdGnrtrTtlACRtvPwr 3383;
BA_ "SPN" SG_ 2364544766 EngineCylinder1CombustionStatus 3387;
BA_ "SPN" SG_ 2364544766 EngineCylinder2CombustionStatus 3388;
BA_ "SPN" SG_ 2364544766 EngineCylinder3CombustionStatus 3389;
BA_ "SPN" SG_ 2364544766 EngineCylinder4CombustionStatus 3390;
BA_ "SPN" SG_ 2364544766 EngineCylinder5CombustionStatus 3391;
BA_ "SPN" SG_ 2364544766 EngineCylinder6CombustionStatus 3392;
BA_ "SPN" SG_ 2364544766 EngineCylinder7CombustionStatus 3393;
BA_ "SPN" SG_ 2364544766 EngineCylinder8CombustionStatus 3394;
BA_ "SPN" SG_ 2364544766 EngineCylinder9CombustionStatus 3395;
BA_ "SPN" SG_ 2364544766 EngnClndr10CmstnStts 3396;
BA_ "SPN" SG_ 2364544766 EngnClndr11CmstnStts 3397;
BA_ "SPN" SG_ 2364544766 EngnClndr12CmstnStts 3398;
BA_ "SPN" SG_ 2364544766 EngnClndr13CmstnStts 3399;
BA_ "SPN" SG_ 2364544766 EngnClndr14CmstnStts 3400;
BA_ "SPN" SG_ 2364544766 EngnClndr15CmstnStts 3401;
BA_ "SPN" SG_ 2364544766 EngnClndr16CmstnStts 3402;
BA_ "SPN" SG_ 2364544766 EngnClndr17CmstnStts 3403;
BA_ "SPN" SG_ 2364544766 EngnClndr18CmstnStts 3404;
BA_ "SPN" SG_ 2364544766 EngnClndr19CmstnStts 3405;
BA_ "SPN" SG_ 2364544766 EngnClndr20CmstnStts 3406;
BA_ "SPN" SG_ 2364544766 EngnClndr21CmstnStts 3407;
BA_ "SPN" SG_ 2364544766 EngnClndr22CmstnStts 3408;
BA_ "SPN" SG_ 2364544766 EngnClndr23CmstnStts 3409;
BA_ "SPN" SG_ 2364544766 EngnClndr24CmstnStts 3410;
BA_ "SPN" SG_ 2364545022 EngineCylinder1KnockLevel 1352;
BA_ "SPN" SG_ 2364545022 EngineCylinder2KnockLevel 1353;
BA_ "SPN" SG_ 2364545022 EngineCylinder3KnockLevel 1354;
BA_ "SPN" SG_ 2364545022 EngineCylinder4KnockLevel 1355;
BA_ "SPN" SG_ 2364545022 EngineCylinder5KnockLevel 1356;
BA_ "SPN" SG_ 2364545022 EngineCylinder6KnockLevel 1357;
BA_ "SPN" SG_ 2364545022 EngineCylinder7KnockLevel 1358;
BA_ "SPN" SG_ 2364545022 EngineCylinder8KnockLevel 1359;
BA_ "SPN" SG_ 2364545278 EngineCylinder10KnockLevel 1361;
BA_ "SPN" SG_ 2364545278 EngineCylinder11KnockLevel 1362;
BA_ "SPN" SG_ 2364545278 EngineCylinder12KnockLevel 1363;
BA_ "SPN" SG_ 2364545278 EngineCylinder13KnockLevel 1364;
BA_ "SPN" SG_ 2364545278 EngineCylinder14KnockLevel 1365;
BA_ "SPN" SG_ 2364545278 EngineCylinder15KnockLevel 1366;
BA_ "SPN" SG_ 2364545278 EngineCylinder16KnockLevel 1367;
BA_ "SPN" SG_ 2364545278 EngineCylinder9KnockLevel 1360;
BA_ "SPN" SG_ 2364545534 EngineCylinder17KnockLevel 1368;
BA_ "SPN" SG_ 2364545534 EngineCylinder18KnockLevel 1369;
BA_ "SPN" SG_ 2364545534 EngineCylinder19KnockLevel 1370;
BA_ "SPN" SG_ 2364545534 EngineCylinder20KnockLevel 1371;
BA_ "SPN" SG_ 2364545534 EngineCylinder21KnockLevel 1372;
BA_ "SPN" SG_ 2364545534 EngineCylinder22KnockLevel 1373;
BA_ "SPN" SG_ 2364545534 EngineCylinder23KnockLevel 1374;
BA_ "SPN" SG_ 2364545534 EngineCylinder24KnockLevel 1375;
BA_ "SPN" SG_ 2364546302 RqstdGnrtrAvrgLnLnACRMSVltg 3386;
BA_ "SPN" SG_ 2364546814 EngineLoadSetpointRequest 8430;
BA_ "SPN" SG_ 2364546814 EngineSelfInducedDerateInhibit 8429;
BA_ "SPN" SG_ 2364546814 GeneratorGoverningBias 3938;
BA_ "SPN" SG_ 2364548094 Aftertreatment1SCRSystem1State 4332;
BA_ "SPN" SG_ 2364548094 Aftertreatment1SCRSystem2State 7524;
BA_ "SPN" SG_ 2364548094 Atttt1DsExstFdAtDsQtt 4331;
BA_ "SPN" SG_ 2364548094 Atttt1DsExstFdAtDsQttHR 6595;
BA_ "SPN" SG_ 2364548094 Atttt1DsExstFdAtQttItt 4333;
BA_ "SPN" SG_ 2364548094 Atttt1DsExstFdDs1AstPss 4334;
BA_ "SPN" SG_ 2364548350 Aftrtrtmnt1SCRSstmRqstdStt 4349;
BA_ "SPN" SG_ 2364548350 Atttt1DsExstFdDsRqstdQtt 4348;
BA_ "SPN" SG_ 2364548350 Atttt1DsExstFdDsRqstdQttHR 6593;
BA_ "SPN" SG_ 2364548350 Atttt1DsExstFdDsTstItPssStts 7518;
BA_ "SPN" SG_ 2364548350 Atttt1DsExstFdHdStssCPssStts 7517;
BA_ "SPN" SG_ 2364548350 Atttt1DsExstFdRqstdQttItt 4350;
BA_ "SPN" SG_ 2364548606 Aftertreatment1OutletNH3 4377;
BA_ "SPN" SG_ 2364548606 Aftrtrtmnt1OtltNH3GsSnsrtTmprtr 4381;
BA_ "SPN" SG_ 2364548606 Aftrtrtmnt1OtltNH3RdngStl 4379;
BA_ "SPN" SG_ 2364548606 Aftrtrtmnt1OtltNH3SnsrPrlmnrFMI 4378;
BA_ "SPN" SG_ 2364548606 Atttt1OttNH3GsSsHtCt 4383;
BA_ "SPN" SG_ 2364548606 Atttt1OttNH3GsSsHtPFMI 4382;
BA_ "SPN" SG_ 2364548606 Atttt1OttNH3GsSsPwIR 4380;
BA_ "SPN" SG_ 2364548862 Aftertreatment2SCRSystem1State 4385;
BA_ "SPN" SG_ 2364548862 Aftertreatment2SCRSystem2State 7525;
BA_ "SPN" SG_ 2364548862 Atttt2DsExstFdAtDsQtt 4384;
BA_ "SPN" SG_ 2364548862 Atttt2DsExstFdAtDsQttHR 6596;
BA_ "SPN" SG_ 2364548862 Atttt2DsExstFdAtQttItt 4386;
BA_ "SPN" SG_ 2364548862 Atttt2DsExstFdDs1AstPss 4387;
BA_ "SPN" SG_ 2364549118 Aftrtrtmnt2SCRSstmRqstdStt 4402;
BA_ "SPN" SG_ 2364549118 Atttt2DsExstFdDsRqstdQtt 4401;
BA_ "SPN" SG_ 2364549118 Atttt2DsExstFdDsRqstdQttHR 6594;
BA_ "SPN" SG_ 2364549118 Atttt2DsExstFdDsTstItPssStts 7520;
BA_ "SPN" SG_ 2364549118 Atttt2DsExstFdHdStssCPssStts 7519;
BA_ "SPN" SG_ 2364549118 Atttt2DsExstFdPpHtCd 7087;
BA_ "SPN" SG_ 2364549118 Atttt2DsExstFdRqstdQttItt 4403;
BA_ "SPN" SG_ 2364549374 Aftertreatment2OutletNH3 4443;
BA_ "SPN" SG_ 2364549374 Aftrtrtmnt2OtltNH3GsSnsrtTmprtr 4447;
BA_ "SPN" SG_ 2364549374 Aftrtrtmnt2OtltNH3RdngStl 4445;
BA_ "SPN" SG_ 2364549374 Aftrtrtmnt2OtltNH3SnsrPrlmnrFMI 4444;
BA_ "SPN" SG_ 2364549374 Atttt2OttNH3GsSsHtCt 4449;
BA_ "SPN" SG_ 2364549374 Atttt2OttNH3GsSsHtPFMI 4448;
BA_ "SPN" SG_ 2364549374 Atttt2OttNH3GsSsPwIR 4446;
BA_ "SPN" SG_ 2364549630 PitchAngleExtendedRange 4976;
BA_ "SPN" SG_ 2364549630 PthAnglCmpnstnExtnddRng 4978;
BA_ "SPN" SG_ 2364549630 PthAnglFgrfMrtExtnddRng 4979;
BA_ "SPN" SG_ 2364549630 RllAnglCmpnstnExtnddRng 4980;
BA_ "SPN" SG_ 2364549630 RllAnglFgrfMrtExtnddRng 4981;
BA_ "SPN" SG_ 2364549630 RllndPthMsrmntLtnExtnddRng 4982;
BA_ "SPN" SG_ 2364549630 RollAngleExtendedRange 4977;
BA_ "SPN" SG_ 2364549886 AngularRateMeasurementLatency 4989;
BA_ "SPN" SG_ 2364549886 PitchRateExtendedRange 4983;
BA_ "SPN" SG_ 2364549886 PthRtFgrfMrtExtnddRng 4986;
BA_ "SPN" SG_ 2364549886 RllRtFgrfMrtExtnddRng 4987;
BA_ "SPN" SG_ 2364549886 RollRateExtendedRange 4984;
BA_ "SPN" SG_ 2364549886 YawRateExtendedRange 4985;
BA_ "SPN" SG_ 2364549886 YwRtFgrfMrtExtnddRng 4988;
BA_ "SPN" SG_ 2364551166 Bndffprltfrlvntjt 5679;
BA_ "SPN" SG_ 2364551166 Collisionwarninglevel 5677;
BA_ "SPN" SG_ 2364551166 Rlvntjtdttdfrdvndmrgnrkngsstm 5678;
BA_ "SPN" SG_ 2364551166 Tmtllsnwthrlvntjt 5680;
BA_ "SPN" SG_ 2364551166 FwdCsAdvdEBSstStt 5676;
BA_ "SPN" SG_ 2364551166 RdDprtrAdvndEmrgnBrkngSstmStt 9748;
BA_ "SPN" SG_ 2364551422 TransmitterCommandState 5751;
BA_ "SPN" SG_ 2364551422 TransmitterID1 5752;
BA_ "SPN" SG_ 2364551422 WirelessRollingMessageCounter 5750;
BA_ "SPN" SG_ 2364551422 WirelessSignalStrength1 5753;
BA_ "SPN" SG_ 2364552958 HVES1ChrgPwrLmtDtBttrCrrnt 8113;
BA_ "SPN" SG_ 2364552958 HVES1ChrgPwrLmtDtBttrDgnstCndtn 8111;
BA_ "SPN" SG_ 2364552958 HVES1ChrgPwrLmtDtBttrrCllVltg 8112;
BA_ "SPN" SG_ 2364552958 HVES1ChrgPwrLmtDtBttrTmprtr 8110;
BA_ "SPN" SG_ 2364552958 HVES1ChrgPwrLmtDtnUndfndCs 8114;
BA_ "SPN" SG_ 2364552958 HVES1ChrgPwrLmtDtSttfChrg 8109;
BA_ "SPN" SG_ 2364552958 HVES1DshrgPwrLmtDtBttrCrrnt 8107;
BA_ "SPN" SG_ 2364552958 HVES1DshrgPwrLmtDtBttrrCllVltg 8106;
BA_ "SPN" SG_ 2364552958 HVES1DshrgPwrLmtDtBttrTmprtr 8104;
BA_ "SPN" SG_ 2364552958 HVES1DshrgPwrLmtDtnUndfndCs 8108;
BA_ "SPN" SG_ 2364552958 HVES1DshrgPwrLmtDtSttfChrg 8103;
BA_ "SPN" SG_ 2364552958 HVES1DsPwLtDtBttDstCdt 8105;
BA_ "SPN" SG_ 2364553214 EngnTrhrgrCmprssrBlwffAttr1Pstn 6315;
BA_ "SPN" SG_ 2364553214 ETCpssBwAtt1DsdPst 6314;
BA_ "SPN" SG_ 2364553214 ETCpssBwAtt1OptStts 6316;
BA_ "SPN" SG_ 2364553214 ETCpssBwAtt1PFMI 6311;
BA_ "SPN" SG_ 2364553214 ETCpssBwAtt1Tpt 6313;
BA_ "SPN" SG_ 2364553214 ETCpssBwAtt1TptStts 6312;
BA_ "SPN" SG_ 2364553470 EngineCylinderTorque 6389;
BA_ "SPN" SG_ 2364553470 EngineDualFuelModeCommand 6792;
BA_ "SPN" SG_ 2364553470 EngnClndrDslMssFlwRtCmmnd 6388;
BA_ "SPN" SG_ 2364553470 EngnClndrGsMssFlwRtCmmnd 6387;
BA_ "SPN" SG_ 2364553470 EngnGsSstttnFlPrntgCmmnd 6386;
BA_ "SPN" SG_ 2364553726 EngineDesiredAirFuelRatio 6392;
BA_ "SPN" SG_ 2364553726 EngnFlSstm1TtlIntkMssArFlwRt 6393;
BA_ "SPN" SG_ 2364553726 EngnFlSstm2TtlIntkMssArFlwRt 8310;
BA_ "SPN" SG_ 2364553982 EngineCylinder1HeatRelease 6396;
BA_ "SPN" SG_ 2364553982 EngineCylinder1PeakPressure 6397;
BA_ "SPN" SG_ 2364553982 EngnClndr1LwFrqnKnkLvl 7609;
BA_ "SPN" SG_ 2364553982 EngnClndr1MxmmPrssrInrsRt 7629;
BA_ "SPN" SG_ 2364553982 EngnClndr1PrssrSnsrPrlmnrFMI 6399;
BA_ "SPN" SG_ 2364553982 EngnClndr1SnhrnsKnkLvl 6398;
BA_ "SPN" SG_ 2364554238 EngineCylinder2HeatRelease 6400;
BA_ "SPN" SG_ 2364554238 EngineCylinder2PeakPressure 6401;
BA_ "SPN" SG_ 2364554238 EngnClndr2LwFrqnKnkLvl 7610;
BA_ "SPN" SG_ 2364554238 EngnClndr2MxmmPrssrInrsRt 7630;
BA_ "SPN" SG_ 2364554238 EngnClndr2PrssrSnsrPrlmnrFMI 6403;
BA_ "SPN" SG_ 2364554238 EngnClndr2SnhrnsKnkLvl 6402;
BA_ "SPN" SG_ 2364554494 EngineCylinder3HeatRelease 6404;
BA_ "SPN" SG_ 2364554494 EngineCylinder3PeakPressure 6405;
BA_ "SPN" SG_ 2364554494 EngnClndr3LwFrqnKnkLvl 7611;
BA_ "SPN" SG_ 2364554494 EngnClndr3MxmmPrssrInrsRt 7631;
BA_ "SPN" SG_ 2364554494 EngnClndr3PrssrSnsrPrlmnrFMI 6407;
BA_ "SPN" SG_ 2364554494 EngnClndr3SnhrnsKnkLvl 6406;
BA_ "SPN" SG_ 2364554750 EngineCylinder4HeatRelease 6408;
BA_ "SPN" SG_ 2364554750 EngineCylinder4PeakPressure 6409;
BA_ "SPN" SG_ 2364554750 EngnClndr4LwFrqnKnkLvl 7612;
BA_ "SPN" SG_ 2364554750 EngnClndr4MxmmPrssrInrsRt 7632;
BA_ "SPN" SG_ 2364554750 EngnClndr4PrssrSnsrPrlmnrFMI 6411;
BA_ "SPN" SG_ 2364554750 EngnClndr4SnhrnsKnkLvl 6410;
BA_ "SPN" SG_ 2364555006 EngineCylinder5HeatRelease 6412;
BA_ "SPN" SG_ 2364555006 EngineCylinder5PeakPressure 6413;
BA_ "SPN" SG_ 2364555006 EngnClndr5LwFrqnKnkLvl 7613;
BA_ "SPN" SG_ 2364555006 EngnClndr5MxmmPrssrInrsRt 7633;
BA_ "SPN" SG_ 2364555006 EngnClndr5PrssrSnsrPrlmnrFMI 6415;
BA_ "SPN" SG_ 2364555006 EngnClndr5SnhrnsKnkLvl 6414;
BA_ "SPN" SG_ 2364555262 EngineCylinder6HeatRelease 6416;
BA_ "SPN" SG_ 2364555262 EngineCylinder6PeakPressure 6417;
BA_ "SPN" SG_ 2364555262 EngnClndr6LwFrqnKnkLvl 7614;
BA_ "SPN" SG_ 2364555262 EngnClndr6MxmmPrssrInrsRt 7634;
BA_ "SPN" SG_ 2364555262 EngnClndr6PrssrSnsrPrlmnrFMI 6419;
BA_ "SPN" SG_ 2364555262 EngnClndr6SnhrnsKnkLvl 6418;
BA_ "SPN" SG_ 2364555518 EngineCylinder7HeatRelease 6420;
BA_ "SPN" SG_ 2364555518 EngineCylinder7PeakPressure 6421;
BA_ "SPN" SG_ 2364555518 EngnClndr7LwFrqnKnkLvl 7615;
BA_ "SPN" SG_ 2364555518 EngnClndr7MxmmPrssrInrsRt 7635;
BA_ "SPN" SG_ 2364555518 EngnClndr7PrssrSnsrPrlmnrFMI 6423;
BA_ "SPN" SG_ 2364555518 EngnClndr7SnhrnsKnkLvl 6422;
BA_ "SPN" SG_ 2364555774 EngineCylinder8HeatRelease 6424;
BA_ "SPN" SG_ 2364555774 EngineCylinder8PeakPressure 6425;
BA_ "SPN" SG_ 2364555774 EngnClndr8LwFrqnKnkLvl 7616;
BA_ "SPN" SG_ 2364555774 EngnClndr8MxmmPrssrInrsRt 7636;
BA_ "SPN" SG_ 2364555774 EngnClndr8PrssrSnsrPrlmnrFMI 6427;
BA_ "SPN" SG_ 2364555774 EngnClndr8SnhrnsKnkLvl 6426;
BA_ "SPN" SG_ 2364556030 EngineCylinder9HeatRelease 6428;
BA_ "SPN" SG_ 2364556030 EngineCylinder9PeakPressure 6429;
BA_ "SPN" SG_ 2364556030 EngnClndr9LwFrqnKnkLvl 7617;
BA_ "SPN" SG_ 2364556030 EngnClndr9MxmmPrssrInrsRt 7637;
BA_ "SPN" SG_ 2364556030 EngnClndr9PrssrSnsrPrlmnrFMI 6431;
BA_ "SPN" SG_ 2364556030 EngnClndr9SnhrnsKnkLvl 6430;
BA_ "SPN" SG_ 2364556286 EngineCylinder10HeatRelease 6432;
BA_ "SPN" SG_ 2364556286 EngineCylinder10PeakPressure 6433;
BA_ "SPN" SG_ 2364556286 EngnClndr10LwFrqnKnkLvl 7618;
BA_ "SPN" SG_ 2364556286 EngnClndr10MxmmPrssrInrsRt 7638;
BA_ "SPN" SG_ 2364556286 EngnClndr10PrssrSnsrPrlmnrFMI 6435;
BA_ "SPN" SG_ 2364556286 EngnClndr10SnhrnsKnkLvl 6434;
BA_ "SPN" SG_ 2364556542 EngineCylinder11HeatRelease 6436;
BA_ "SPN" SG_ 2364556542 EngineCylinder11PeakPressure 6437;
BA_ "SPN" SG_ 2364556542 EngnClndr11LwFrqnKnkLvl 7619;
BA_ "SPN" SG_ 2364556542 EngnClndr11MxmmPrssrInrsRt 7639;
BA_ "SPN" SG_ 2364556542 EngnClndr11PrssrSnsrPrlmnrFMI 6439;
BA_ "SPN" SG_ 2364556542 EngnClndr11SnhrnsKnkLvl 6438;
BA_ "SPN" SG_ 2364556798 EngineCylinder12HeatRelease 6440;
BA_ "SPN" SG_ 2364556798 EngineCylinder12PeakPressure 6441;
BA_ "SPN" SG_ 2364556798 EngnClndr12LwFrqnKnkLvl 7620;
BA_ "SPN" SG_ 2364556798 EngnClndr12MxmmPrssrInrsRt 7640;
BA_ "SPN" SG_ 2364556798 EngnClndr12PrssrSnsrPrlmnrFMI 6443;
BA_ "SPN" SG_ 2364556798 EngnClndr12SnhrnsKnkLvl 6442;
BA_ "SPN" SG_ 2364557054 EngineCylinder13HeatRelease 6444;
BA_ "SPN" SG_ 2364557054 EngineCylinder13PeakPressure 6445;
BA_ "SPN" SG_ 2364557054 EngnClndr13LwFrqnKnkLvl 7621;
BA_ "SPN" SG_ 2364557054 EngnClndr13MxmmPrssrInrsRt 7641;
BA_ "SPN" SG_ 2364557054 EngnClndr13PrssrSnsrPrlmnrFMI 6447;
BA_ "SPN" SG_ 2364557054 EngnClndr13SnhrnsKnkLvl 6446;
BA_ "SPN" SG_ 2364557310 EngineCylinder14HeatRelease 6448;
BA_ "SPN" SG_ 2364557310 EngineCylinder14PeakPressure 6449;
BA_ "SPN" SG_ 2364557310 EngnClndr14LwFrqnKnkLvl 7622;
BA_ "SPN" SG_ 2364557310 EngnClndr14MxmmPrssrInrsRt 7642;
BA_ "SPN" SG_ 2364557310 EngnClndr14PrssrSnsrPrlmnrFMI 6451;
BA_ "SPN" SG_ 2364557310 EngnClndr14SnhrnsKnkLvl 6450;
BA_ "SPN" SG_ 2364557566 EngineCylinder15HeatRelease 6452;
BA_ "SPN" SG_ 2364557566 EngineCylinder15PeakPressure 6453;
BA_ "SPN" SG_ 2364557566 EngnClndr15LwFrqnKnkLvl 7623;
BA_ "SPN" SG_ 2364557566 EngnClndr15MxmmPrssrInrsRt 7643;
BA_ "SPN" SG_ 2364557566 EngnClndr15PrssrSnsrPrlmnrFMI 6455;
BA_ "SPN" SG_ 2364557566 EngnClndr15SnhrnsKnkLvl 6454;
BA_ "SPN" SG_ 2364557822 EngineCylinder16HeatRelease 6456;
BA_ "SPN" SG_ 2364557822 EngineCylinder16PeakPressure 6457;
BA_ "SPN" SG_ 2364557822 EngnClndr16LwFrqnKnkLvl 7624;
BA_ "SPN" SG_ 2364557822 EngnClndr16MxmmPrssrInrsRt 7644;
BA_ "SPN" SG_ 2364557822 EngnClndr16PrssrSnsrPrlmnrFMI 6459;
BA_ "SPN" SG_ 2364557822 EngnClndr16SnhrnsKnkLvl 6458;
BA_ "SPN" SG_ 2364558078 EngineCylinder17HeatRelease 6460;
BA_ "SPN" SG_ 2364558078 EngineCylinder17PeakPressure 6461;
BA_ "SPN" SG_ 2364558078 EngnClndr17LwFrqnKnkLvl 7625;
BA_ "SPN" SG_ 2364558078 EngnClndr17MxmmPrssrInrsRt 7645;
BA_ "SPN" SG_ 2364558078 EngnClndr17PrssrSnsrPrlmnrFMI 6463;
BA_ "SPN" SG_ 2364558078 EngnClndr17SnhrnsKnkLvl 6462;
BA_ "SPN" SG_ 2364558334 EngineCylinder18HeatRelease 6464;
BA_ "SPN" SG_ 2364558334 EngineCylinder18PeakPressure 6465;
BA_ "SPN" SG_ 2364558334 EngnClndr18LwFrqnKnkLvl 7626;
BA_ "SPN" SG_ 2364558334 EngnClndr18MxmmPrssrInrsRt 7646;
BA_ "SPN" SG_ 2364558334 EngnClndr18PrssrSnsrPrlmnrFMI 6467;
BA_ "SPN" SG_ 2364558334 EngnClndr18SnhrnsKnkLvl 6466;
BA_ "SPN" SG_ 2364558590 EngineCylinder19HeatRelease 6468;
BA_ "SPN" SG_ 2364558590 EngineCylinder19PeakPressure 6469;
BA_ "SPN" SG_ 2364558590 EngnClndr19LwFrqnKnkLvl 7627;
BA_ "SPN" SG_ 2364558590 EngnClndr19MxmmPrssrInrsRt 7647;
BA_ "SPN" SG_ 2364558590 EngnClndr19PrssrSnsrPrlmnrFMI 6471;
BA_ "SPN" SG_ 2364558590 EngnClndr19SnhrnsKnkLvl 6470;
BA_ "SPN" SG_ 2364558846 EngineCylinder20HeatRelease 6472;
BA_ "SPN" SG_ 2364558846 EngineCylinder20PeakPressure 6473;
BA_ "SPN" SG_ 2364558846 EngnClndr20LwFrqnKnkLvl 7628;
BA_ "SPN" SG_ 2364558846 EngnClndr20MxmmPrssrInrsRt 7648;
BA_ "SPN" SG_ 2364558846 EngnClndr20PrssrSnsrPrlmnrFMI 6475;
BA_ "SPN" SG_ 2364558846 EngnClndr20SnhrnsKnkLvl 6474;
BA_ "SPN" SG_ 2364564478 EngnGssFlVlvNmnlDrtnCmmnd 6656;
BA_ "SPN" SG_ 2364564478 EngnGssFlVlvNmnlStrtfAttnCmmnd 6657;
BA_ "SPN" SG_ 2364564478 EngnPrChmrFlVlvNmnlDrtnCmmnd 9650;
BA_ "SPN" SG_ 2364564478 EPCFVvNSttAttCd 9651;
BA_ "SPN" SG_ 2364564734 EngnGssFlVlv1DrtnCmmnd 6658;
BA_ "SPN" SG_ 2364564734 EngnGssFlVlv2DrtnCmmnd 6659;
BA_ "SPN" SG_ 2364564734 EngnGssFlVlv3DrtnCmmnd 6660;
BA_ "SPN" SG_ 2364564734 EngnGssFlVlv4DrtnCmmnd 6661;
BA_ "SPN" SG_ 2364564990 EngnGssFlVlv5DrtnCmmnd 6662;
BA_ "SPN" SG_ 2364564990 EngnGssFlVlv6DrtnCmmnd 6663;
BA_ "SPN" SG_ 2364564990 EngnGssFlVlv7DrtnCmmnd 6664;
BA_ "SPN" SG_ 2364564990 EngnGssFlVlv8DrtnCmmnd 6665;
BA_ "SPN" SG_ 2364565246 EngnGssFlVlv10DrtnCmmnd 6667;
BA_ "SPN" SG_ 2364565246 EngnGssFlVlv11DrtnCmmnd 6668;
BA_ "SPN" SG_ 2364565246 EngnGssFlVlv12DrtnCmmnd 6669;
BA_ "SPN" SG_ 2364565246 EngnGssFlVlv9DrtnCmmnd 6666;
BA_ "SPN" SG_ 2364565502 EngnGssFlVlv13DrtnCmmnd 6670;
BA_ "SPN" SG_ 2364565502 EngnGssFlVlv14DrtnCmmnd 6671;
BA_ "SPN" SG_ 2364565502 EngnGssFlVlv15DrtnCmmnd 6672;
BA_ "SPN" SG_ 2364565502 EngnGssFlVlv16DrtnCmmnd 6673;
BA_ "SPN" SG_ 2364565758 EngnGssFlVlv17DrtnCmmnd 6674;
BA_ "SPN" SG_ 2364565758 EngnGssFlVlv18DrtnCmmnd 6675;
BA_ "SPN" SG_ 2364565758 EngnGssFlVlv19DrtnCmmnd 6676;
BA_ "SPN" SG_ 2364565758 EngnGssFlVlv20DrtnCmmnd 6677;
BA_ "SPN" SG_ 2364566014 EngnGssFlVlv1StrtfAttnCmmnd 6678;
BA_ "SPN" SG_ 2364566014 EngnGssFlVlv2StrtfAttnCmmnd 6679;
BA_ "SPN" SG_ 2364566014 EngnGssFlVlv3StrtfAttnCmmnd 6680;
BA_ "SPN" SG_ 2364566014 EngnGssFlVlv4StrtfAttnCmmnd 6681;
BA_ "SPN" SG_ 2364566270 EngnGssFlVlv5StrtfAttnCmmnd 6682;
BA_ "SPN" SG_ 2364566270 EngnGssFlVlv6StrtfAttnCmmnd 6683;
BA_ "SPN" SG_ 2364566270 EngnGssFlVlv7StrtfAttnCmmnd 6684;
BA_ "SPN" SG_ 2364566270 EngnGssFlVlv8StrtfAttnCmmnd 6685;
BA_ "SPN" SG_ 2364566526 EngnGssFlVlv10StrtfAttnCmmnd 6687;
BA_ "SPN" SG_ 2364566526 EngnGssFlVlv11StrtfAttnCmmnd 6688;
BA_ "SPN" SG_ 2364566526 EngnGssFlVlv12StrtfAttnCmmnd 6689;
BA_ "SPN" SG_ 2364566526 EngnGssFlVlv9StrtfAttnCmmnd 6686;
BA_ "SPN" SG_ 2364566782 EngnGssFlVlv13StrtfAttnCmmnd 6690;
BA_ "SPN" SG_ 2364566782 EngnGssFlVlv14StrtfAttnCmmnd 6691;
BA_ "SPN" SG_ 2364566782 EngnGssFlVlv15StrtfAttnCmmnd 6692;
BA_ "SPN" SG_ 2364566782 EngnGssFlVlv16StrtfAttnCmmnd 6693;
BA_ "SPN" SG_ 2364567038 EngnGssFlVlv17StrtfAttnCmmnd 6694;
BA_ "SPN" SG_ 2364567038 EngnGssFlVlv18StrtfAttnCmmnd 6695;
BA_ "SPN" SG_ 2364567038 EngnGssFlVlv19StrtfAttnCmmnd 6696;
BA_ "SPN" SG_ 2364567038 EngnGssFlVlv20StrtfAttnCmmnd 6697;
BA_ "SPN" SG_ 2364567294 EngnFlInjtnPmp1FlCntrlVlvCmmnd 6719;
BA_ "SPN" SG_ 2364567294 EngnFlInjtnPmp2FlCntrlVlvCmmnd 6720;
BA_ "SPN" SG_ 2364575998 HVES1AvailableChargePower 5918;
BA_ "SPN" SG_ 2364575998 HVES1AvailableDischargePower 5917;
BA_ "SPN" SG_ 2364575998 HVES1Current 5920;
BA_ "SPN" SG_ 2364575998 HVES1VoltageLevel 5919;
BA_ "SPN" SG_ 2364576254 HVES1CllVltgDffrntlStts 5924;
BA_ "SPN" SG_ 2364576254 HVES1FastUpdateStateofCharge 5921;
BA_ "SPN" SG_ 2364576254 HVES1HighestCellVoltage 5922;
BA_ "SPN" SG_ 2364576254 HVES1LowestCellVoltage 5923;
BA_ "SPN" SG_ 2364576510 HVES1AverageCellTemperature 8077;
BA_ "SPN" SG_ 2364576510 HVES1CllTmprtrDffrntlStts 8078;
BA_ "SPN" SG_ 2364576510 HVES1HighestCellTemperature 8075;
BA_ "SPN" SG_ 2364576510 HVES1LowestCellTemperature 8076;
BA_ "SPN" SG_ 2364576766 HVES1CellBalancingCount 8081;
BA_ "SPN" SG_ 2364576766 HVES1ChargeCapacity 8080;
BA_ "SPN" SG_ 2364576766 HVES1DischargeCapacity 8079;
BA_ "SPN" SG_ 2364577022 HVES1ChargeCurrentLimit 8083;
BA_ "SPN" SG_ 2364577022 HVES1DischargeCurrentLimit 8082;
BA_ "SPN" SG_ 2364577022 HVES1MaximumCellStateofCharge 8085;
BA_ "SPN" SG_ 2364577022 HVES1MinimumCellStateofCharge 8084;
BA_ "SPN" SG_ 2364577278 HVES1BusVoltage 8086;
BA_ "SPN" SG_ 2364577278 HVES1ElectronicsTemperature 8204;
BA_ "SPN" SG_ 2364577278 HVES1IgnitionVoltage 8087;
BA_ "SPN" SG_ 2364577278 HVES1IntakeCoolantTemperature 8088;
BA_ "SPN" SG_ 2364577278 HVES1OutletCoolantTemperature 8089;
BA_ "SPN" SG_ 2364577278 HVES1Temperature 9119;
BA_ "SPN" SG_ 2364577534 HVES1CellBalanceStatus 8101;
BA_ "SPN" SG_ 2364577534 HVES1CellBalancingActive 8102;
BA_ "SPN" SG_ 2364577534 HVES1CenterofPackContactorState 8095;
BA_ "SPN" SG_ 2364577534 HVES1HghVltgBsAtvIsltnTstStts 8096;
BA_ "SPN" SG_ 2364577534 HVES1HghVltgBsCnntnStts 8413;
BA_ "SPN" SG_ 2364577534 HVES1HghVltgBsDsnntFrwrnng 8093;
BA_ "SPN" SG_ 2364577534 HVES1HghVltgBsNgtvCnttrStt 8092;
BA_ "SPN" SG_ 2364577534 HVES1HghVltgBsPrChrgRlStt 8094;
BA_ "SPN" SG_ 2364577534 HVES1HghVltgBsPssvIsltnTstStts 8097;
BA_ "SPN" SG_ 2364577534 HVES1HghVltgBsPstvCnttrStt 8091;
BA_ "SPN" SG_ 2364577534 HVES1HVILStatus 8098;
BA_ "SPN" SG_ 2364577534 HVES1InertiaSwitchStatus 8099;
BA_ "SPN" SG_ 2364577534 HVES1InternalChargerStatus 8207;
BA_ "SPN" SG_ 2364577534 HVES1OperationalStatus 8414;
BA_ "SPN" SG_ 2364577534 HVES1StateofChargeStatus 8100;
BA_ "SPN" SG_ 2364580094 HVES1ChargeEnergyCapacity 8206;
BA_ "SPN" SG_ 2364580094 HVES1DischargeEnergyCapacity 8205;
BA_ "SPN" SG_ 2364580094 HVES1MaximumChargeVoltageLimit 8090;
